VERSION ""

NS_ :

BS_:

BU_: LMFS RMFS TPMS TCU_ERAGLONASS E_APU PCCM NOX_2 NOX_1 ENGINE_CONTROL_MODULE TRANSMISSION INTARDER EBS TACHOGRAPH INSTRUMENT_CLUSTER CAMERA RADAR BCM

BO_ 2566841377 SHUTDN_BCM: 8 BCM
 SG_ ConcretePumpStartRequest : 62|2@1+ (1,0) [0|3] ""  PCCM,ENGINE_CONTROL_MODULE
 SG_ APUPressureSwitchStatus : 26|2@1+ (1,0) [0|3] ""  PCCM,ENGINE_CONTROL_MODULE
 SG_ AC_clutch_status : 22|2@1+ (1,0) [0|3] ""  PCCM,ENGINE_CONTROL_MODULE
 SG_ EngOverspeedTest : 54|2@1+ (1,0) [0|3] ""  PCCM,ENGINE_CONTROL_MODULE
 SG_ EngAirShutoffCmdStatus : 52|2@1+ (1,0) [0|3] ""  PCCM,ENGINE_CONTROL_MODULE
 SG_ EngAlarmOutputCmdStatus : 50|2@1+ (1,0) [0|3] ""  PCCM,ENGINE_CONTROL_MODULE
 SG_ EngAlarmAcknowledge : 48|2@1+ (1,0) [0|3] ""  PCCM,ENGINE_CONTROL_MODULE
 SG_ EngProtectionSystemConfig : 46|2@1+ (1,0) [0|3] ""  PCCM,ENGINE_CONTROL_MODULE
 SG_ EngProtectionSystemTimerState : 38|2@1+ (1,0) [0|3] ""  PCCM,ENGINE_CONTROL_MODULE
 SG_ EngPrtectionSystemTimerOverride : 36|2@1+ (1,0) [0|3] ""  PCCM,ENGINE_CONTROL_MODULE
 SG_ EngPrtctnSystmApprchingShutdown : 34|2@1+ (1,0) [0|3] ""  PCCM,ENGINE_CONTROL_MODULE
 SG_ EngWaitToStartLamp : 24|2@1+ (1,0) [0|3] ""  PCCM,ENGINE_CONTROL_MODULE
 SG_ RefrigerantHighPressSwitch : 20|2@1+ (1,0) [0|3] ""  PCCM,ENGINE_CONTROL_MODULE
 SG_ RefrigerantLowPressSwitch : 18|2@1+ (1,0) [0|3] ""  PCCM,ENGINE_CONTROL_MODULE
 SG_ A_CHighPressFanSwitch : 16|2@1+ (1,0) [0|3] ""  PCCM,ENGINE_CONTROL_MODULE
 SG_ EngIdleShutdownTimerFunction : 14|2@1+ (1,0) [0|3] ""  PCCM,ENGINE_CONTROL_MODULE
 SG_ EngIdleShutdownTimerState : 6|2@1+ (1,0) [0|3] ""  PCCM,ENGINE_CONTROL_MODULE
 SG_ EngIdleShutdownTimerOverride : 4|2@1+ (1,0) [0|3] ""  PCCM,ENGINE_CONTROL_MODULE
 SG_ EngIdleShutdownDriverAlertMode : 2|2@1+ (1,0) [0|3] ""  PCCM,ENGINE_CONTROL_MODULE
 SG_ PTOShutdownHasShutdownEng : 58|2@1+ (1,0) [0|3] ""  PCCM,ENGINE_CONTROL_MODULE
 SG_ EngPrtctnSystmHasShutdownEngine : 32|2@1+ (1,0) [0|3] ""  PCCM,ENGINE_CONTROL_MODULE
 SG_ EngIdlShutdownHasShutdownEngine : 0|2@1+ (1,0) [0|3] ""  PCCM,ENGINE_CONTROL_MODULE
 SG_ EngAirShutoffStatus : 56|2@1+ (1,0) [0|3] ""  PCCM,ENGINE_CONTROL_MODULE

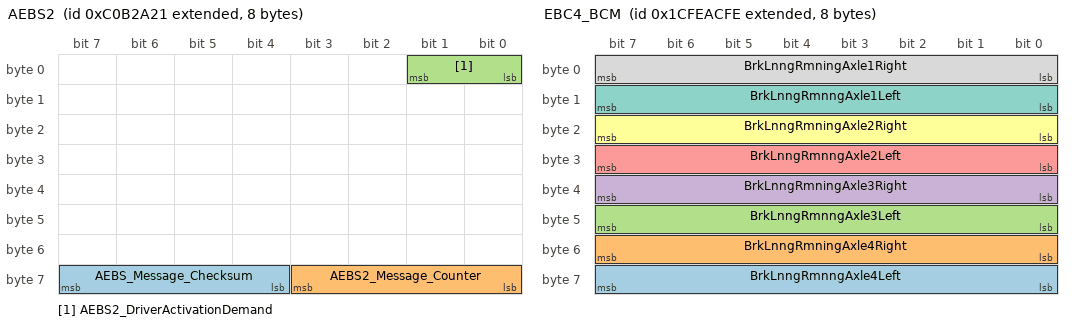
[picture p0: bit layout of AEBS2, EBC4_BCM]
BO_ 2349541921 AEBS2: 8 BCM
 SG_ AEBS_Message_Checksum : 60|4@1+ (1,0) [0|15] ""  PCCM,RADAR
 SG_ AEBS2_Message_Counter : 56|4@1+ (1,0) [0|15] ""  PCCM,RADAR
 SG_ AEBS2_DriverActivationDemand : 0|2@1+ (1,0) [0|3] ""  PCCM,RADAR

BO_ 2633936126 EBC4_BCM: 8 Vector__XXX
 SG_ BrkLnngRmnngAxle4Left : 56|8@1+ (1,0) [0|255] "" Vector__XXX
 SG_ BrkLnngRmningAxle4Right : 48|8@1+ (1,0) [0|255] "" Vector__XXX
 SG_ BrkLnngRmnngAxle3Left : 40|8@1+ (1,0) [0|255] "" Vector__XXX
 SG_ BrkLnngRmningAxle3Right : 32|8@1+ (1,0) [0|255] "" Vector__XXX
 SG_ BrkLnngRmnngAxle2Left : 24|8@1+ (1,0) [0|255] "" Vector__XXX
 SG_ BrkLnngRmningAxle2Right : 16|8@1+ (1,0) [0|255] "" Vector__XXX
 SG_ BrkLnngRmnngAxle1Left : 8|8@1+ (1,0) [0|255] "" Vector__XXX
 SG_ BrkLnngRmningAxle1Right : 0|8@1+ (1,0) [0|255] "" Vector__XXX

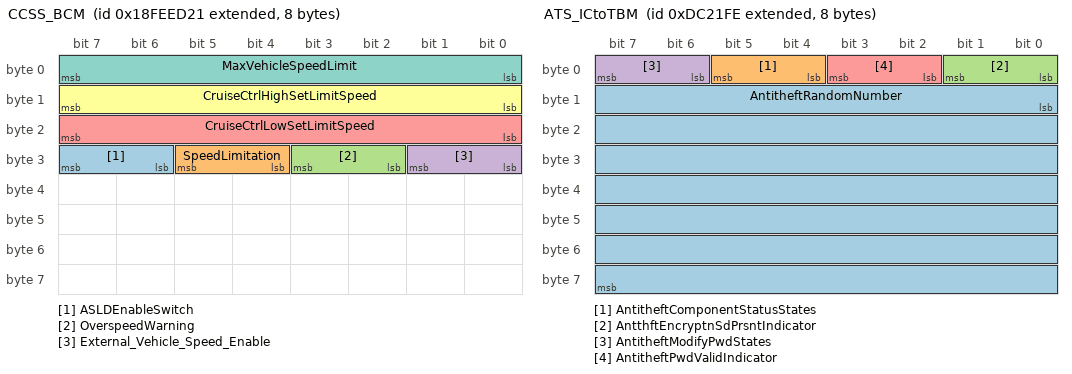
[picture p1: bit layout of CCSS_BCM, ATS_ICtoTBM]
BO_ 2566843681 CCSS_BCM: 8 BCM
 SG_ ASLDEnableSwitch : 30|2@1+ (1,0) [0|3] "SED"  PCCM,ENGINE_CONTROL_MODULE,INSTRUMENT_CLUSTER
 SG_ SpeedLimitation : 28|2@1+ (1,0) [0|3] ""  PCCM,ENGINE_CONTROL_MODULE,INSTRUMENT_CLUSTER
 SG_ OverspeedWarning : 26|2@1+ (1,0) [0|3] ""  PCCM,ENGINE_CONTROL_MODULE,INSTRUMENT_CLUSTER
 SG_ External_Vehicle_Speed_Enable : 24|2@1+ (1,0) [0|3] ""  PCCM,ENGINE_CONTROL_MODULE,INSTRUMENT_CLUSTER
 SG_ CruiseCtrlLowSetLimitSpeed : 16|8@1+ (1,0) [0|250] "km/h"  PCCM,ENGINE_CONTROL_MODULE,INSTRUMENT_CLUSTER
 SG_ CruiseCtrlHighSetLimitSpeed : 8|8@1+ (1,0) [0|250] "km/h"  PCCM,ENGINE_CONTROL_MODULE,INSTRUMENT_CLUSTER
 SG_ MaxVehicleSpeedLimit : 0|8@1+ (1,0) [0|250] "km/h"  PCCM,ENGINE_CONTROL_MODULE,INSTRUMENT_CLUSTER

BO_ 2566844705 CCVS_BCM: 8 BCM
 SG_ AutoECall_Inhibit : 40|2@1+ (1,0) [0|3] ""  PCCM
 SG_ PCCScreenSelection : 61|2@1+ (1,0) [0|3] ""  PCCM,INSTRUMENT_CLUSTER
 SG_ CruiseCtrlEnableSwitch_BCM : 26|2@1+ (1,0) [0|3] ""  PCCM
 SG_ CruiseControlDisableCommand_BCM : 0|2@1+ (1,0) [0|3] ""  PCCM,ENGINE_CONTROL_MODULE,INSTRUMENT_CLUSTER
 SG_ ConcretePumpTransferCaseACK : 56|2@1+ (1,0) [0|3] ""  PCCM,ENGINE_CONTROL_MODULE,INSTRUMENT_CLUSTER
 SG_ PTO_Application_Mode : 58|3@1+ (1,0) [0|7] ""  PCCM,ENGINE_CONTROL_MODULE,INSTRUMENT_CLUSTER
 SG_ ParkBrakeReleaseInhibitRq_CCVSB : 6|2@1+ (1,0) [0|3] ""  PCCM,ENGINE_CONTROL_MODULE,INSTRUMENT_CLUSTER
 SG_ PTOGovernorState_CCVS_BCM : 48|5@1+ (1,0) [0|31] ""  PCCM,ENGINE_CONTROL_MODULE,INSTRUMENT_CLUSTER
 SG_ CruiseCtrlAccelerateSwitch_CCVSB : 38|2@1+ (1,0) [0|3] ""  PCCM,ENGINE_CONTROL_MODULE,INSTRUMENT_CLUSTER
 SG_ CruiseCtrlResumeSwitch_CCVS_BCM : 36|2@1+ (1,0) [0|3] ""  PCCM,ENGINE_CONTROL_MODULE,INSTRUMENT_CLUSTER
 SG_ CruiseCtrlCoastSwitch_CCVS_BCM : 34|2@1+ (1,0) [0|3] ""  PCCM,ENGINE_CONTROL_MODULE,INSTRUMENT_CLUSTER
 SG_ CruiseCtrlOffSwitch : 32|2@1+ (1,0) [0|3] ""  PCCM,ENGINE_CONTROL_MODULE,INSTRUMENT_CLUSTER
 SG_ ClutchSwitch_CCVS_BCM : 30|2@1+ (1,0) [0|3] ""  PCCM,ENGINE_CONTROL_MODULE,INSTRUMENT_CLUSTER
 SG_ BrakeSwitch_CCVS_BCM : 28|2@1+ (1,0) [0|3] ""  PCCM,ENGINE_CONTROL_MODULE,INSTRUMENT_CLUSTER
 SG_ DamperActivation : 24|2@1+ (1,0) [0|3] ""  PCCM,ENGINE_CONTROL_MODULE,INSTRUMENT_CLUSTER
 SG_ WheelBasedVehicleSpeed_CCVS_BCM : 8|16@1+ (0.00390625,0) [0|251] "km/h"  PCCM,ENGINE_CONTROL_MODULE,INSTRUMENT_CLUSTER
 SG_ CruiseCtrlPauseSwitch_CCVS_BCM : 4|2@1+ (1,0) [0|3] ""  PCCM,ENGINE_CONTROL_MODULE,INSTRUMENT_CLUSTER
 SG_ ParkingBrakeSwitch_CCVS_BCM : 2|2@1+ (1,0) [0|3] ""  PCCM,ENGINE_CONTROL_MODULE,INSTRUMENT_CLUSTER

BO_ 2566834967 DM2_IC: 22 Vector__XXX
 SG_ MalfunctionIndicatorLampStatus : 6|2@1+ (1,0) [0|3] "" Vector__XXX
 SG_ RedStopLampState : 4|2@1+ (1,0) [0|3] "" Vector__XXX
 SG_ AmberWarningLampStatus : 2|2@1+ (1,0) [0|3] "" Vector__XXX
 SG_ ProtectLampStatus : 0|2@1+ (1,0) [0|3] "" Vector__XXX
 SG_ FlashRedStopLamp : 12|2@1+ (1,0) [0|3] "" Vector__XXX
 SG_ FlashProtectLamp : 8|2@1+ (1,0) [0|3] "" Vector__XXX
 SG_ FlashMalfuncIndicatorLamp : 14|2@1+ (1,0) [0|3] "" Vector__XXX
 SG_ FlashAmberWarningLamp : 10|2@1+ (1,0) [0|3] "" Vector__XXX
 SG_ DTC5 : 144|32@1+ (1,0) [0|4294967295] "" Vector__XXX
 SG_ DTC4 : 112|32@1+ (1,0) [0|4294967295] "" Vector__XXX
 SG_ DTC3 : 80|32@1+ (1,0) [0|4294967295] "" Vector__XXX
 SG_ DTC2 : 48|32@1+ (1,0) [0|4294967295] "" Vector__XXX
 SG_ DTC1 : 16|32@1+ (1,0) [0|4294967295] "" Vector__XXX

BO_ 2566834711 DM1_IC: 64 INSTRUMENT_CLUSTER
 SG_ FlashRedStopLamp : 12|2@1+ (1,0) [0|3] ""  PCCM
 SG_ FlashProtectLamp : 8|2@1+ (1,0) [0|3] ""  PCCM
 SG_ FlashMalfuncIndicatorLamp : 14|2@1+ (1,0) [0|3] ""  PCCM
 SG_ FlashAmberWarningLamp : 10|2@1+ (1,0) [0|3] ""  PCCM
 SG_ MalfunctionIndicatorLampStatus : 6|2@1+ (1,0) [0|3] ""  PCCM
 SG_ AmberWarningLampStatus : 2|2@1+ (1,0) [0|3] ""  PCCM
 SG_ RedStopLampState : 4|2@1+ (1,0) [0|3] ""  PCCM
 SG_ ProtectLampStatus : 0|2@1+ (1,0) [0|3] ""  PCCM
 SG_ DTC5 : 144|32@1+ (1,0) [0|4294967295] ""  PCCM
 SG_ DTC4 : 112|32@1+ (1,0) [0|4294967295] ""  PCCM
 SG_ DTC3 : 80|32@1+ (1,0) [0|4294967295] ""  PCCM
 SG_ DTC2 : 48|32@1+ (1,0) [0|4294967295] ""  PCCM
 SG_ DTC1 : 16|32@1+ (1,0) [0|4294967295] ""  PCCM

BO_ 2161910270 ATS_ICtoTBM: 8 Vector__XXX
 SG_ AntitheftRandomNumber : 8|56@1+ (1,0) [0|255] "" Vector__XXX
 SG_ AntitheftComponentStatusStates : 4|2@1+ (1,0) [0|3] "" Vector__XXX
 SG_ AntthftEncryptnSdPrsntIndicator : 0|2@1+ (1,0) [0|3] "" Vector__XXX
 SG_ AntitheftModifyPwdStates : 6|2@1+ (1,0) [0|3] "" Vector__XXX
 SG_ AntitheftPwdValidIndicator : 2|2@1+ (1,0) [0|3] "" Vector__XXX

BO_ 2566835198 DM2_ABS_ABSwESP: 22 Vector__XXX
 SG_ MalfunctionIndicatorLampStatus : 6|2@1+ (1,0) [0|3] "" Vector__XXX
 SG_ RedStopLampState : 4|2@1+ (1,0) [0|3] "" Vector__XXX
 SG_ AmberWarningLampStatus : 2|2@1+ (1,0) [0|3] "" Vector__XXX
 SG_ ProtectLampStatus : 0|2@1+ (1,0) [0|3] "" Vector__XXX
 SG_ FlashRedStopLamp : 12|2@1+ (1,0) [0|3] "" Vector__XXX
 SG_ FlashProtectLamp : 8|2@1+ (1,0) [0|3] "" Vector__XXX
 SG_ FlashMalfuncIndicatorLamp : 14|2@1+ (1,0) [0|3] "" Vector__XXX
 SG_ FlashAmberWarningLamp : 10|2@1+ (1,0) [0|3] "" Vector__XXX
 SG_ DTC5 : 144|32@1+ (1,0) [0|4294967295] "" Vector__XXX
 SG_ DTC4 : 112|32@1+ (1,0) [0|4294967295] "" Vector__XXX
 SG_ DTC3 : 80|32@1+ (1,0) [0|4294967295] "" Vector__XXX
 SG_ DTC2 : 48|32@1+ (1,0) [0|4294967295] "" Vector__XXX
 SG_ DTC1 : 16|32@1+ (1,0) [0|4294967295] "" Vector__XXX

BO_ 2550596608 EDC2NOx: 8 Vector__XXX

BO_ 2349334270 NOxSensorMessage: 8 Vector__XXX

BO_ 2566881534 FWLI: 8 Vector__XXX
 SG_ TBMTelltale : 0|2@1+ (1,0) [0|3] "" Vector__XXX
 SG_ ErrorIndication : 2|6@1+ (1,0) [0|63] "" Vector__XXX

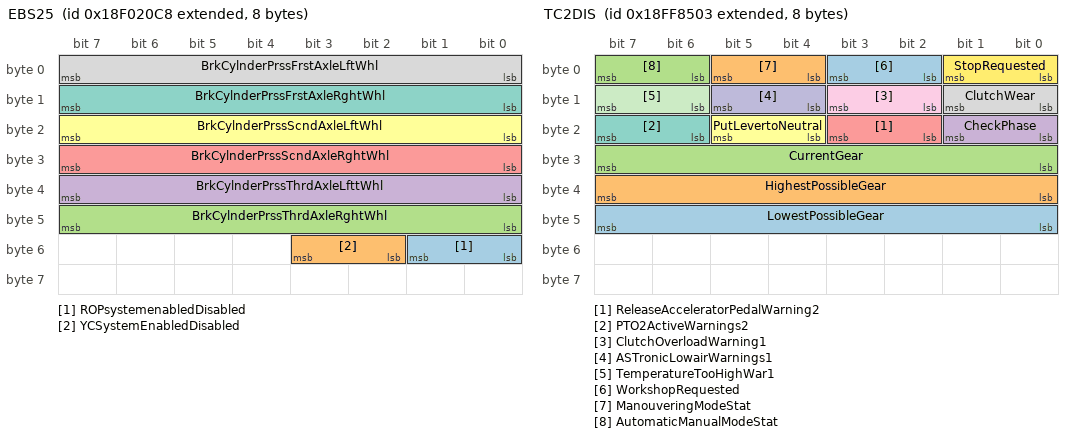
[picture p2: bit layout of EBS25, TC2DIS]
BO_ 2565873864 EBS25: 8 Vector__XXX
 SG_ ROPsystemenabledDisabled : 48|2@1+ (1,0) [0|3] "" Vector__XXX
 SG_ YCSystemEnabledDisabled : 50|2@1+ (1,0) [0|3] "" Vector__XXX
 SG_ BrkCylnderPrssThrdAxleRghtWhl : 40|8@1+ (5,0) [0|1250] "kPa" Vector__XXX
 SG_ BrkCylnderPrssThrdAxleLfttWhl : 32|8@1+ (5,0) [0|1250] "kPa" Vector__XXX
 SG_ BrkCylnderPrssScndAxleRghtWhl : 24|8@1+ (5,0) [0|1250] "kPa" Vector__XXX
 SG_ BrkCylnderPrssScndAxleLftWhl : 16|8@1+ (5,0) [0|1250] "kPa" Vector__XXX
 SG_ BrkCylnderPrssFrstAxleRghtWhl : 8|8@1+ (5,0) [0|1250] "kPa" Vector__XXX
 SG_ BrkCylnderPrssFrstAxleLftWhl : 0|8@1+ (5,0) [0|1250] "kPa" Vector__XXX

BO_ 2566882563 TC2DIS: 8 TRANSMISSION
 SG_ LowestPossibleGear : 40|8@1+ (1,-125) [-125|125] "gearvalue"  PCCM,INSTRUMENT_CLUSTER,BCM
 SG_ HighestPossibleGear : 32|8@1+ (1,-125) [-125|125] "gearvalue"  PCCM,INSTRUMENT_CLUSTER,BCM
 SG_ CurrentGear : 24|8@1+ (1,-125) [-125|125] "gearvalue"  PCCM,INSTRUMENT_CLUSTER,BCM
 SG_ CheckPhase : 16|2@1+ (1,0) [0|3] ""  PCCM,INSTRUMENT_CLUSTER,BCM
 SG_ ReleaseAcceleratorPedalWarning2 : 18|2@1+ (1,0) [0|3] ""  PCCM,INSTRUMENT_CLUSTER,BCM
 SG_ PutLevertoNeutral : 20|2@1+ (1,0) [0|3] ""  PCCM,INSTRUMENT_CLUSTER,BCM
 SG_ PTO2ActiveWarnings2 : 22|2@1+ (1,0) [0|3] ""  PCCM,INSTRUMENT_CLUSTER,BCM
 SG_ ClutchWear : 8|2@1+ (1,0) [0|3] ""  PCCM,INSTRUMENT_CLUSTER,BCM
 SG_ ClutchOverloadWarning1 : 10|2@1+ (1,0) [0|3] ""  PCCM,INSTRUMENT_CLUSTER,BCM
 SG_ ASTronicLowairWarnings1 : 12|2@1+ (1,0) [0|3] ""  PCCM,INSTRUMENT_CLUSTER,BCM
 SG_ TemperatureTooHighWar1 : 14|2@1+ (1,0) [0|3] ""  PCCM,INSTRUMENT_CLUSTER,BCM
 SG_ StopRequested : 0|2@1+ (1,0) [0|3] ""  PCCM,INSTRUMENT_CLUSTER,BCM
 SG_ WorkshopRequested : 2|2@1+ (1,0) [0|3] ""  PCCM,INSTRUMENT_CLUSTER,BCM
 SG_ ManouveringModeStat : 4|2@1+ (1,0) [0|3] ""  PCCM,BCM,INSTRUMENT_CLUSTER
 SG_ AutomaticManualModeStat : 6|2@1+ (1,0) [0|3] ""  PCCM,INSTRUMENT_CLUSTER,BCM

BO_ 2550596157 SCR2: 8 Vector__XXX
 SG_ UreaTankLevel : 0|8@1- (0.4,0) [0|100] "%" Vector__XXX
 SG_ SCR2 : 8|56@1+ (1,0) [0|7.2057594038E+016] "" Vector__XXX

BO_ 2550726398 SCR1_DCU: 8 Vector__XXX
 SG_ SCR1 : 0|64@1+ (1,0) [0|1.8446744074E+019] "" Vector__XXX

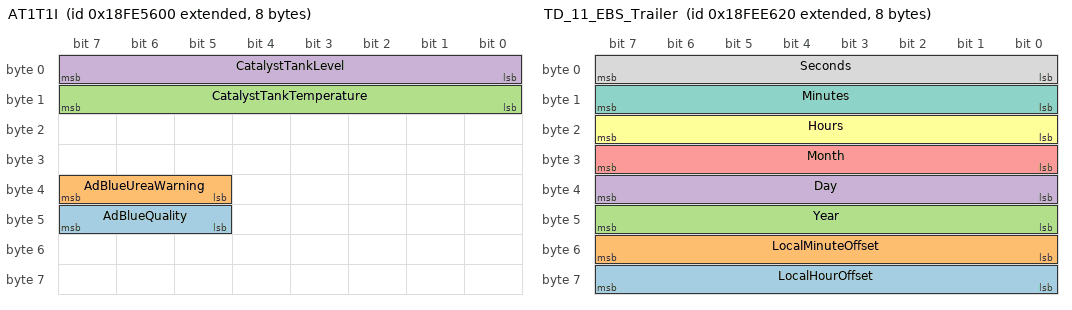
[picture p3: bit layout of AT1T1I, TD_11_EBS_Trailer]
BO_ 2566804992 AT1T1I: 8 ENGINE_CONTROL_MODULE
 SG_ AdBlueQuality : 45|3@1+ (1,0) [0|7] "SED"  PCCM,BCM,INSTRUMENT_CLUSTER
 SG_ AdBlueUreaWarning : 37|3@1+ (1,0) [0|7] "SED"  PCCM,BCM,INSTRUMENT_CLUSTER
 SG_ CatalystTankTemperature : 8|8@1+ (1,-40) [-40|210] "degree"  PCCM,BCM,INSTRUMENT_CLUSTER
 SG_ CatalystTankLevel : 0|8@1+ (0.4,0) [0|100] "%"  PCCM,BCM,INSTRUMENT_CLUSTER

BO_ 2566857214 EDC2BC: 8 Vector__XXX
 SG_ Humudity : 56|8@1+ (0.4,0) [0|102] "%" Vector__XXX
 SG_ EngineDegradationLevel : 48|4@1+ (1,0) [0|15] "" Vector__XXX
 SG_ EDCOperationalStat : 52|4@1+ (1,0) [0|15] "" Vector__XXX
 SG_ EngineOilPressureLow : 40|2@1+ (1,0) [0|3] "" Vector__XXX
 SG_ WaterinFeulDetection : 42|2@1+ (1,0) [0|3] "" Vector__XXX
 SG_ FuelFilterStatus : 44|2@1+ (1,0) [0|3] "" Vector__XXX
 SG_ EngineOilTemperatureHigh : 46|2@1+ (1,0) [0|3] "" Vector__XXX
 SG_ StatofEngComprtmntStopButton : 36|2@1+ (1,0) [0|3] "" Vector__XXX
 SG_ StatofEngCompartmentStartButton : 38|2@1+ (1,0) [0|3] "" Vector__XXX
 SG_ MILStatus : 24|2@1+ (1,0) [0|3] "" Vector__XXX
 SG_ AdjustabelSpeedLimiterStatus : 28|2@1+ (1,0) [0|3] "" Vector__XXX
 SG_ ECMFuellingState : 30|2@1+ (1,0) [0|3] "" Vector__XXX
 SG_ MaximumVehicleSpeedLimitSetPoint : 16|8@1+ (1,0) [0|255] "km/h" Vector__XXX
 SG_ SpeedLimiterStatus : 8|2@1+ (1,0) [0|3] "" Vector__XXX
 SG_ EngineOverSpeed : 10|2@1+ (1,0) [0|3] "" Vector__XXX
 SG_ EngineOverTemperature : 13|3@1+ (1,0) [0|7] "" Vector__XXX
 SG_ ColdStartHeaterStat : 0|4@1+ (1,0) [0|15] "" Vector__XXX
 SG_ FuelBlockStatByImmobilizer : 4|2@1+ (1,0) [0|3] "" Vector__XXX
 SG_ DiagnosticLampStat : 6|2@1+ (1,0) [0|3] "" Vector__XXX

BO_ 2365537790 ECM2SCR: 8 Vector__XXX
 SG_ ECM2SCR : 0|64@1+ (1,0) [0|999999] "" Vector__XXX

BO_ 2566841888 TD_11_EBS_Trailer: 8 Vector__XXX
 SG_ LocalHourOffset : 56|8@1+ (1,-125) [-125|125] "hr" Vector__XXX
 SG_ LocalMinuteOffset : 48|8@1+ (1,-125) [-125|125] "mins" Vector__XXX
 SG_ Year : 40|8@1+ (1,1985) [1985|2235] "years" Vector__XXX
 SG_ Day : 32|8@1+ (0.25,0) [0|62.5] "days" Vector__XXX
 SG_ Month : 24|8@1+ (1,0) [0|250] "months" Vector__XXX
 SG_ Hours : 16|8@1+ (1,0) [0|250] "hr" Vector__XXX
 SG_ Minutes : 8|8@1+ (1,0) [0|250] "mins" Vector__XXX
 SG_ Seconds : 0|8@1+ (0.25,0) [0|62.5] "s" Vector__XXX

BO_ 2566835710 DM4_AST: 13 Vector__XXX
 SG_ EngIntakeManifold1Press : 48|8@1+ (2,0) [0|500] "kPa" Vector__XXX
 SG_ FreezeFrameLength : 0|8@1+ (1,0) [0|255] "Byte" Vector__XXX
 SG_ EngSpeed : 56|16@1+ (0.125,0) [0|8031.875] "rpm" Vector__XXX
 SG_ EngTorqueMode : 40|4@1+ (1,0) [0|15] "" Vector__XXX
 SG_ WheelBasedVehicleSpeed : 88|16@1+ (0.00390625,0) [0|250.996] "km/h" Vector__XXX
 SG_ EngPercentLoadAtCurrentSpeed : 72|8@1+ (1,0) [0|250] "%" Vector__XXX
 SG_ EngineCoolantTemperature : 80|8@1+ (1,-40) [-40|210] "°C" Vector__XXX
 SG_ DTC1 : 8|32@1+ (1,0) [0|4294967295] "" Vector__XXX

BO_ 2566840592 RC_Intarder: 19 INTARDER
 SG_ PercentTorqueAtPeakTorquePoint5 : 144|8@1+ (1,-125) [-125|125] "%"  PCCM,TRANSMISSION,EBS
 SG_ ReferenceRetarderTorque : 128|16@1+ (1,0) [0|64255] "Nm"  PCCM,TRANSMISSION,EBS
 SG_ RetarderSpeedAtPeakTorquePoint5 : 112|16@1+ (0.125,0) [0|8031.875] "rpm"  PCCM,TRANSMISSION,EBS
 SG_ PercentTorqueAtPoint4 : 104|8@1+ (1,-125) [-125|125] "%"  PCCM,TRANSMISSION,EBS
 SG_ RetarderSpeedAtPoint4 : 88|16@1+ (0.125,0) [0|8031.875] "rpm"  PCCM,TRANSMISSION,EBS
 SG_ PercentTorqueAtPoint3 : 80|8@1+ (1,-125) [-125|125] "%"  PCCM,TRANSMISSION,EBS
 SG_ RetarderSpeedAtPoint3 : 64|16@1+ (0.125,0) [0|8031.875] "rpm"  PCCM,TRANSMISSION,EBS
 SG_ PercentTorqueAtMaxSpeedPoint2 : 56|8@1+ (1,-125) [-125|125] "%"  PCCM,TRANSMISSION,EBS
 SG_ MaxRetarderSpeedPoint2 : 40|16@1+ (0.125,0) [0|8031.875] "rpm"  PCCM,TRANSMISSION,EBS
 SG_ PercentTorqueAtIdlePoint1 : 32|8@1+ (1,-125) [-125|125] "%"  PCCM,TRANSMISSION,EBS
 SG_ RetarderSpeedAtIdlePoint1 : 16|16@1+ (0.125,0) [0|8031.875] "rpm"  PCCM,TRANSMISSION,EBS
 SG_ RetarderCtrlMethod : 8|8@1+ (1,0) [0|250] "steps"  PCCM,TRANSMISSION,EBS
 SG_ RetarderLocation : 4|4@1+ (1,0) [0|15] ""  PCCM,TRANSMISSION,EBS
 SG_ RetarderType : 0|4@1+ (1,0) [0|15] ""  PCCM,TRANSMISSION,EBS

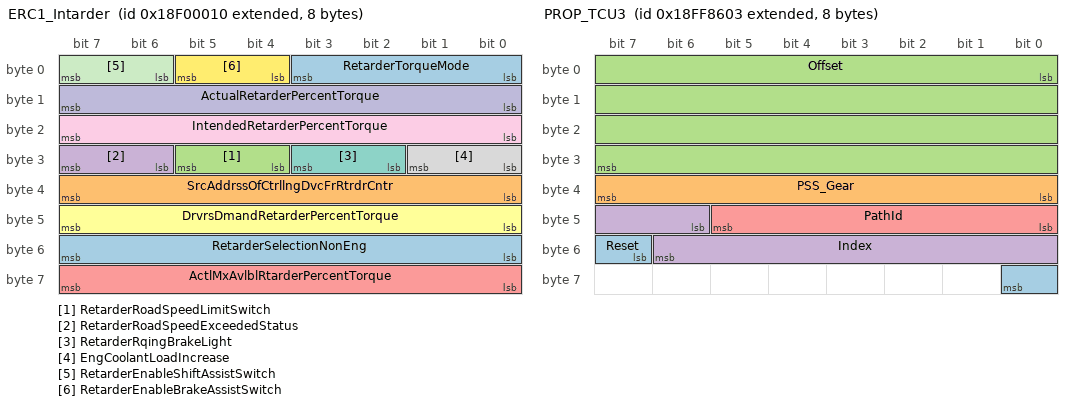
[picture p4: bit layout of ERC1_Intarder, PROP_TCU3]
BO_ 2565865488 ERC1_Intarder: 8 INTARDER
 SG_ RetarderSelectionNonEng : 48|8@1+ (0.4,0) [0|100] "%"  PCCM,TRANSMISSION,EBS,INSTRUMENT_CLUSTER,BCM
 SG_ SrcAddrssOfCtrllngDvcFrRtrdrCntr : 32|8@1+ (1,0) [0|255] ""  PCCM,TRANSMISSION,EBS,INSTRUMENT_CLUSTER,BCM
 SG_ RetarderRoadSpeedLimitSwitch : 28|2@1+ (1,0) [0|3] ""  PCCM,TRANSMISSION,EBS,INSTRUMENT_CLUSTER,BCM
 SG_ RetarderRoadSpeedExceededStatus : 30|2@1+ (1,0) [0|3] ""  PCCM,TRANSMISSION,EBS,INSTRUMENT_CLUSTER,BCM
 SG_ ActlMxAvlblRtarderPercentTorque : 56|8@1+ (1,-125) [-125|0] "%"  PCCM,TRANSMISSION,EBS,INSTRUMENT_CLUSTER,BCM
 SG_ DrvrsDmandRetarderPercentTorque : 40|8@1+ (1,-125) [-125|0] "%"  PCCM,TRANSMISSION,EBS,INSTRUMENT_CLUSTER,BCM
 SG_ RetarderRqingBrakeLight : 26|2@1+ (1,0) [0|3] ""  PCCM,TRANSMISSION,EBS,INSTRUMENT_CLUSTER,BCM
 SG_ EngCoolantLoadIncrease : 24|2@1+ (1,0) [0|3] ""  PCCM,TRANSMISSION,EBS,INSTRUMENT_CLUSTER,BCM
 SG_ IntendedRetarderPercentTorque : 16|8@1+ (1,-125) [-125|0] "%"  PCCM,TRANSMISSION,EBS,INSTRUMENT_CLUSTER,BCM
 SG_ ActualRetarderPercentTorque : 8|8@1+ (1,-125) [-125|0] "%"  PCCM,TRANSMISSION,EBS,INSTRUMENT_CLUSTER,BCM
 SG_ RetarderEnableShiftAssistSwitch : 6|2@1+ (1,0) [0|3] ""  PCCM,TRANSMISSION,EBS,INSTRUMENT_CLUSTER,BCM
 SG_ RetarderEnableBrakeAssistSwitch : 4|2@1+ (1,0) [0|3] ""  PCCM,TRANSMISSION,EBS,INSTRUMENT_CLUSTER,BCM
 SG_ RetarderTorqueMode : 0|4@1+ (1,0) [0|15] ""  PCCM,TRANSMISSION,EBS,INSTRUMENT_CLUSTER,BCM

BO_ 2566834960 DM2_Int: 64 INTARDER
 SG_ MalfunctionIndicatorLampStatus : 6|2@1+ (1,0) [0|3] ""  PCCM
 SG_ RedStopLampState : 4|2@1+ (1,0) [0|3] ""  PCCM
 SG_ AmberWarningLampStatus : 2|2@1+ (1,0) [0|3] ""  PCCM
 SG_ ProtectLampStatus : 0|2@1+ (1,0) [0|3] ""  PCCM
 SG_ FlashRedStopLamp : 12|2@1+ (1,0) [0|3] ""  PCCM
 SG_ FlashProtectLamp : 8|2@1+ (1,0) [0|3] ""  PCCM
 SG_ FlashMalfuncIndicatorLamp : 14|2@1+ (1,0) [0|3] ""  PCCM
 SG_ FlashAmberWarningLamp : 10|2@1+ (1,0) [0|3] ""  PCCM
 SG_ DTC5 : 144|32@1+ (1,0) [0|4294967295] ""  PCCM
 SG_ DTC4 : 112|32@1+ (1,0) [0|4294967295] ""  PCCM
 SG_ DTC3 : 80|32@1+ (1,0) [0|4294967295] ""  PCCM
 SG_ DTC2 : 48|32@1+ (1,0) [0|4294967295] ""  PCCM
 SG_ DTC1 : 16|32@1+ (1,0) [0|4294967295] ""  PCCM

BO_ 2566882819 PROP_TCU3: 8 TRANSMISSION
 SG_ Reset : 55|2@1+ (1,0) [0|3] ""  PCCM
 SG_ PSS_Gear : 32|8@1+ (1,-125) [-125|125] ""  PCCM
 SG_ Offset : 0|32@1+ (1,0) [0|4294967295] "m"  PCCM
 SG_ Index : 46|9@1+ (1,0) [0|511] ""  PCCM
 SG_ PathId : 40|6@1+ (1,0) [0|63] ""  PCCM

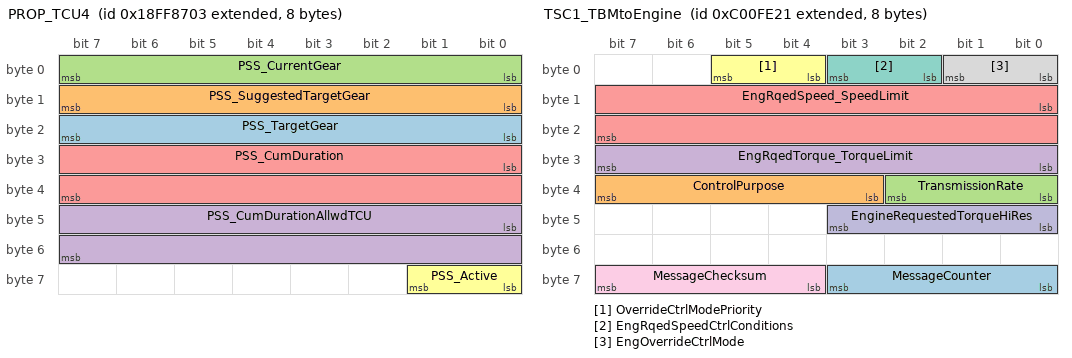
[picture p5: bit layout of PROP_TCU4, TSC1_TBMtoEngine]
BO_ 2566883075 PROP_TCU4: 8 TRANSMISSION
 SG_ PSS_TargetGear : 16|8@1+ (1,-125) [-125|125] ""  PCCM
 SG_ PSS_SuggestedTargetGear : 8|8@1+ (1,-125) [-125|125] ""  PCCM
 SG_ PSS_CurrentGear : 0|8@1+ (1,-125) [-125|125] ""  PCCM
 SG_ PSS_CumDurationAllwdTCU : 40|16@1+ (1,0) [0|65535] "min"  PCCM
 SG_ PSS_CumDuration : 24|16@1+ (1,0) [0|65535] "min"  PCCM
 SG_ PSS_Active : 56|2@1+ (1,0) [0|3] ""  PCCM

BO_ 2566834749 DM1_DCU: 22 Vector__XXX
 SG_ FlashRedStopLamp : 12|2@1+ (1,0) [0|3] "" Vector__XXX
 SG_ FlashProtectLamp : 8|2@1+ (1,0) [0|3] "" Vector__XXX
 SG_ FlashMalfuncIndicatorLamp : 14|2@1+ (1,0) [0|3] "" Vector__XXX
 SG_ FlashAmberWarningLamp : 10|2@1+ (1,0) [0|3] "" Vector__XXX
 SG_ MalfunctionIndicatorLampStatus : 6|2@1+ (1,0) [0|3] "" Vector__XXX
 SG_ AmberWarningLampStatus : 2|2@1+ (1,0) [0|3] "" Vector__XXX
 SG_ RedStopLampState : 4|2@1+ (1,0) [0|3] "" Vector__XXX
 SG_ ProtectLampStatus : 0|2@1+ (1,0) [0|3] "" Vector__XXX
 SG_ DTC5 : 144|32@1+ (1,0) [0|4294967295] "" Vector__XXX
 SG_ DTC4 : 112|32@1+ (1,0) [0|4294967295] "" Vector__XXX
 SG_ DTC3 : 80|32@1+ (1,0) [0|4294967295] "" Vector__XXX
 SG_ DTC2 : 48|32@1+ (1,0) [0|4294967295] "" Vector__XXX
 SG_ DTC1 : 16|32@1+ (1,0) [0|4294967295] "" Vector__XXX

BO_ 2348875297 TSC1_TBMtoEngine: 8 Vector__XXX
 SG_ MessageCounter : 56|4@1+ (1,0) [0|15] "" Vector__XXX
 SG_ ControlPurpose : 35|5@1+ (1,0) [0|31] "" Vector__XXX
 SG_ TransmissionRate : 32|3@1+ (1,0) [0|7] "" Vector__XXX
 SG_ EngRqedTorque_TorqueLimit : 24|8@1+ (1,-125) [-125|125] "%" Vector__XXX
 SG_ EngRqedSpeed_SpeedLimit : 8|16@1+ (0.125,0) [0|8031.875] "rpm" Vector__XXX
 SG_ OverrideCtrlModePriority : 4|2@1+ (1,0) [0|3] "" Vector__XXX
 SG_ EngRqedSpeedCtrlConditions : 2|2@1+ (1,0) [0|3] "" Vector__XXX
 SG_ EngOverrideCtrlMode : 0|2@1+ (1,0) [0|3] "" Vector__XXX
 SG_ MessageChecksum : 60|4@1+ (1,0) [0|15] "" Vector__XXX
 SG_ EngineRequestedTorqueHiRes : 40|4@1+ (0.125,0) [0|0.875] "%" Vector__XXX

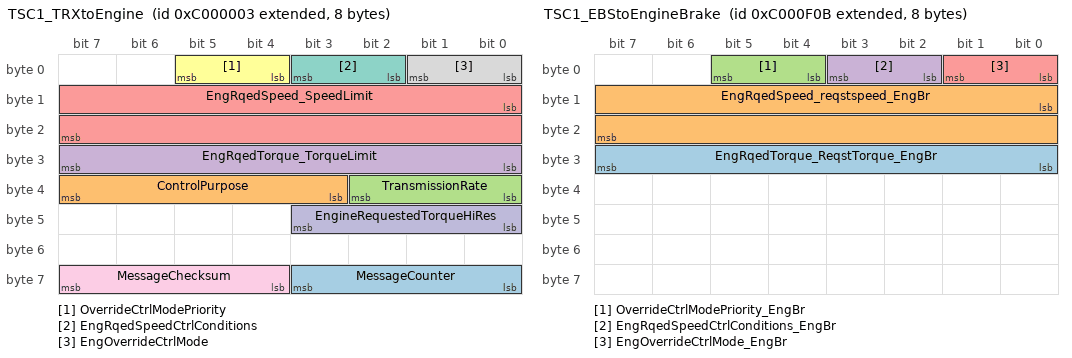
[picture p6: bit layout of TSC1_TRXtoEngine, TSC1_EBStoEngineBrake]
BO_ 2348810243 TSC1_TRXtoEngine: 8 TRANSMISSION
 SG_ MessageCounter : 56|4@1+ (1,0) [0|15] ""  PCCM,ENGINE_CONTROL_MODULE
 SG_ ControlPurpose : 35|5@1+ (1,0) [0|31] ""  PCCM,ENGINE_CONTROL_MODULE
 SG_ TransmissionRate : 32|3@1+ (1,0) [0|7] ""  PCCM,ENGINE_CONTROL_MODULE
 SG_ EngRqedTorque_TorqueLimit : 24|8@1+ (1,-125) [-125|125] "%"  PCCM,ENGINE_CONTROL_MODULE
 SG_ EngRqedSpeed_SpeedLimit : 8|16@1+ (0.125,0) [0|8031.875] "rpm"  PCCM,ENGINE_CONTROL_MODULE
 SG_ OverrideCtrlModePriority : 4|2@1+ (1,0) [0|3] ""  PCCM,ENGINE_CONTROL_MODULE
 SG_ EngRqedSpeedCtrlConditions : 2|2@1+ (1,0) [0|3] ""  PCCM,ENGINE_CONTROL_MODULE
 SG_ EngOverrideCtrlMode : 0|2@1+ (1,0) [0|3] ""  PCCM,ENGINE_CONTROL_MODULE
 SG_ MessageChecksum : 60|4@1+ (1,0) [0|15] ""  PCCM,ENGINE_CONTROL_MODULE
 SG_ EngineRequestedTorqueHiRes : 40|4@1+ (0.125,0) [0|0.875] "%"  PCCM,ENGINE_CONTROL_MODULE

BO_ 2348814091 TSC1_EBStoEngineBrake: 8 EBS
 SG_ EngRqedTorque_ReqstTorque_EngBr : 24|8@1+ (1,-125) [-125|125] "%"  ENGINE_CONTROL_MODULE,PCCM
 SG_ EngRqedSpeed_reqstspeed_EngBr : 8|16@1+ (0.125,0) [0|8031.875] "rpm"  ENGINE_CONTROL_MODULE,PCCM
 SG_ OverrideCtrlModePriority_EngBr : 4|2@1+ (1,0) [0|3] ""  ENGINE_CONTROL_MODULE,PCCM
 SG_ EngRqedSpeedCtrlConditions_EngBr : 2|2@1+ (1,0) [0|3] ""  ENGINE_CONTROL_MODULE,PCCM
 SG_ EngOverrideCtrlMode_EngBr : 0|2@1+ (1,0) [0|3] ""  ENGINE_CONTROL_MODULE,PCCM

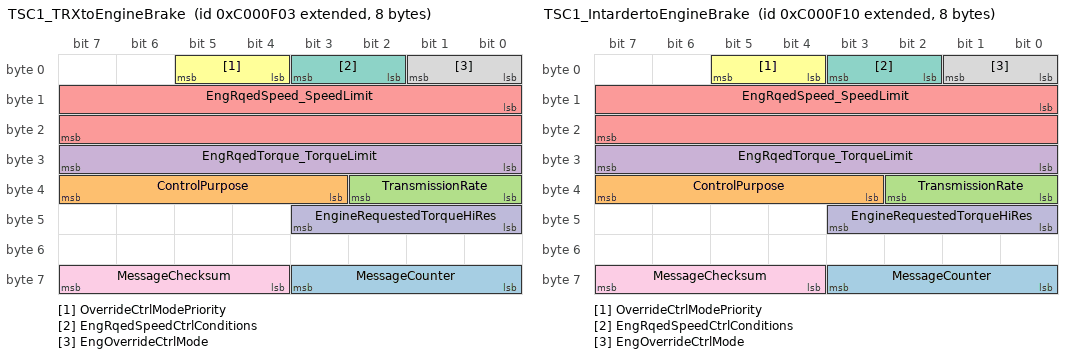
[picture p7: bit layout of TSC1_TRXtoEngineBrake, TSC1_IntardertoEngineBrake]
BO_ 2348814083 TSC1_TRXtoEngineBrake: 8 TRANSMISSION
 SG_ MessageCounter : 56|4@1+ (1,0) [0|15] ""  PCCM
 SG_ ControlPurpose : 35|5@1+ (1,0) [0|31] ""  PCCM
 SG_ TransmissionRate : 32|3@1+ (1,0) [0|7] ""  PCCM
 SG_ EngRqedTorque_TorqueLimit : 24|8@1+ (1,-125) [-125|125] "%"  PCCM
 SG_ EngRqedSpeed_SpeedLimit : 8|16@1+ (0.125,0) [0|8031.875] "rpm"  PCCM
 SG_ OverrideCtrlModePriority : 4|2@1+ (1,0) [0|3] ""  PCCM
 SG_ EngRqedSpeedCtrlConditions : 2|2@1+ (1,0) [0|3] ""  PCCM
 SG_ EngOverrideCtrlMode : 0|2@1+ (1,0) [0|3] ""  PCCM
 SG_ MessageChecksum : 60|4@1+ (1,0) [0|15] ""  PCCM
 SG_ EngineRequestedTorqueHiRes : 40|4@1+ (0.125,0) [0|0.875] "%"  PCCM

BO_ 2348814096 TSC1_IntardertoEngineBrake: 8 INTARDER
 SG_ MessageCounter : 56|4@1+ (1,0) [0|15] ""  PCCM,ENGINE_CONTROL_MODULE
 SG_ ControlPurpose : 35|5@1+ (1,0) [0|31] ""  PCCM,ENGINE_CONTROL_MODULE
 SG_ TransmissionRate : 32|3@1+ (1,0) [0|7] ""  PCCM,ENGINE_CONTROL_MODULE
 SG_ EngRqedTorque_TorqueLimit : 24|8@1+ (1,-125) [-125|125] "%"  PCCM,ENGINE_CONTROL_MODULE
 SG_ EngRqedSpeed_SpeedLimit : 8|16@1+ (0.125,0) [0|8031.875] "rpm"  PCCM,ENGINE_CONTROL_MODULE
 SG_ OverrideCtrlModePriority : 4|2@1+ (1,0) [0|3] ""  PCCM,ENGINE_CONTROL_MODULE
 SG_ EngRqedSpeedCtrlConditions : 2|2@1+ (1,0) [0|3] ""  PCCM,ENGINE_CONTROL_MODULE
 SG_ EngOverrideCtrlMode : 0|2@1+ (1,0) [0|3] ""  PCCM,ENGINE_CONTROL_MODULE
 SG_ MessageChecksum : 60|4@1+ (1,0) [0|15] ""  PCCM,ENGINE_CONTROL_MODULE
 SG_ EngineRequestedTorqueHiRes : 40|4@1+ (0.125,0) [0|0.875] "%"  PCCM,ENGINE_CONTROL_MODULE

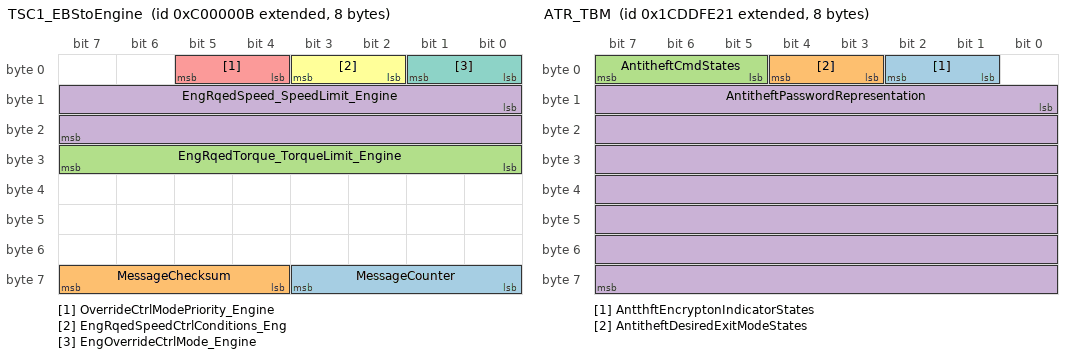
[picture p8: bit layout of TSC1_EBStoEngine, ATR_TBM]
BO_ 2348810251 TSC1_EBStoEngine: 8 EBS
 SG_ MessageCounter : 56|4@1+ (1,0) [0|7] ""  PCCM
 SG_ MessageChecksum : 60|4@1+ (1,0) [0|15] ""  PCCM
 SG_ EngRqedTorque_TorqueLimit_Engine : 24|8@1+ (1,-125) [-125|125] "%"  PCCM,ENGINE_CONTROL_MODULE
 SG_ EngRqedSpeed_SpeedLimit_Engine : 8|16@1+ (0.125,0) [0|8031.875] "rpm"  PCCM,ENGINE_CONTROL_MODULE
 SG_ OverrideCtrlModePriority_Engine : 4|2@1+ (1,0) [0|3] ""  PCCM,ENGINE_CONTROL_MODULE
 SG_ EngRqedSpeedCtrlConditions_Eng : 2|2@1+ (1,0) [0|3] ""  PCCM,ENGINE_CONTROL_MODULE
 SG_ EngOverrideCtrlMode_Engine : 0|2@1+ (1,0) [0|3] ""  PCCM,ENGINE_CONTROL_MODULE

BO_ 2566834699 DM1_EBS: 64 EBS
 SG_ FlashRedStopLamp : 12|2@1+ (1,0) [0|3] ""  PCCM,INSTRUMENT_CLUSTER
 SG_ FlashProtectLamp : 8|2@1+ (1,0) [0|3] ""  PCCM,INSTRUMENT_CLUSTER
 SG_ FlashMalfuncIndicatorLamp : 14|2@1+ (1,0) [0|3] ""  PCCM,INSTRUMENT_CLUSTER
 SG_ FlashAmberWarningLamp : 10|2@1+ (1,0) [0|3] ""  PCCM,INSTRUMENT_CLUSTER
 SG_ MalfunctionIndicatorLampStatus : 6|2@1+ (1,0) [0|3] ""  PCCM,INSTRUMENT_CLUSTER
 SG_ AmberWarningLampStatus : 2|2@1+ (1,0) [0|3] ""  PCCM,INSTRUMENT_CLUSTER
 SG_ RedStopLampState : 4|2@1+ (1,0) [0|3] ""  PCCM,INSTRUMENT_CLUSTER
 SG_ ProtectLampStatus : 0|2@1+ (1,0) [0|3] ""  PCCM,INSTRUMENT_CLUSTER
 SG_ DTC5 : 144|32@1+ (1,0) [0|4294967295] ""  PCCM,INSTRUMENT_CLUSTER
 SG_ DTC4 : 112|32@1+ (1,0) [0|4294967295] ""  PCCM,INSTRUMENT_CLUSTER
 SG_ DTC3 : 80|32@1+ (1,0) [0|4294967295] ""  PCCM,INSTRUMENT_CLUSTER
 SG_ DTC2 : 48|32@1+ (1,0) [0|4294967295] ""  PCCM,INSTRUMENT_CLUSTER
 SG_ DTC1 : 16|32@1+ (1,0) [0|4294967295] ""  PCCM,INSTRUMENT_CLUSTER

BO_ 2566834942 DM1_AST: 22 Vector__XXX
 SG_ FlashRedStopLamp : 12|2@1+ (1,0) [0|3] "" Vector__XXX
 SG_ FlashProtectLamp : 8|2@1+ (1,0) [0|3] "" Vector__XXX
 SG_ FlashMalfuncIndicatorLamp : 14|2@1+ (1,0) [0|3] "" Vector__XXX
 SG_ FlashAmberWarningLamp : 10|2@1+ (1,0) [0|3] "" Vector__XXX
 SG_ MalfunctionIndicatorLampStatus : 6|2@1+ (1,0) [0|3] "" Vector__XXX
 SG_ AmberWarningLampStatus : 2|2@1+ (1,0) [0|3] "" Vector__XXX
 SG_ RedStopLampState : 4|2@1+ (1,0) [0|3] "" Vector__XXX
 SG_ ProtectLampStatus : 0|2@1+ (1,0) [0|3] "" Vector__XXX
 SG_ DTC5 : 144|32@1+ (1,0) [0|4294967295] "" Vector__XXX
 SG_ DTC4 : 112|32@1+ (1,0) [0|4294967295] "" Vector__XXX
 SG_ DTC3 : 80|32@1+ (1,0) [0|4294967295] "" Vector__XXX
 SG_ DTC2 : 48|32@1+ (1,0) [0|4294967295] "" Vector__XXX
 SG_ DTC1 : 16|32@1+ (1,0) [0|4294967295] "" Vector__XXX

BO_ 2566834688 DM1_ECM: 22 ENGINE_CONTROL_MODULE
 SG_ FlashRedStopLamp : 12|2@1+ (1,0) [0|3] ""  LMFS,PCCM,BCM,INSTRUMENT_CLUSTER
 SG_ FlashProtectLamp : 8|2@1+ (1,0) [0|3] ""  LMFS,PCCM,BCM,INSTRUMENT_CLUSTER
 SG_ FlashMalfuncIndicatorLamp : 14|2@1+ (1,0) [0|3] ""  LMFS,PCCM,BCM,INSTRUMENT_CLUSTER
 SG_ FlashAmberWarningLamp : 10|2@1+ (1,0) [0|3] ""  LMFS,PCCM,BCM,INSTRUMENT_CLUSTER
 SG_ MalfunctionIndicatorLampStatus : 6|2@1+ (1,0) [0|3] ""  LMFS,PCCM,BCM,INSTRUMENT_CLUSTER
 SG_ AmberWarningLampStatus : 2|2@1+ (1,0) [0|3] ""  LMFS,PCCM,BCM,INSTRUMENT_CLUSTER
 SG_ RedStopLampState : 4|2@1+ (1,0) [0|3] ""  LMFS,PCCM,BCM,INSTRUMENT_CLUSTER
 SG_ ProtectLampStatus : 0|2@1+ (1,0) [0|3] ""  LMFS,PCCM,BCM,INSTRUMENT_CLUSTER
 SG_ DTC5 : 144|32@1+ (1,0) [0|4294967295] ""  LMFS,PCCM,BCM,INSTRUMENT_CLUSTER
 SG_ DTC4 : 112|32@1+ (1,0) [0|4294967295] ""  LMFS,PCCM,BCM,INSTRUMENT_CLUSTER
 SG_ DTC3 : 80|32@1+ (1,0) [0|4294967295] ""  LMFS,PCCM,BCM,INSTRUMENT_CLUSTER
 SG_ DTC2 : 48|32@1+ (1,0) [0|4294967295] ""  LMFS,PCCM,BCM,INSTRUMENT_CLUSTER
 SG_ DTC1 : 16|32@1+ (1,0) [0|4294967295] ""  LMFS,PCCM,BCM,INSTRUMENT_CLUSTER

BO_ 2566834926 DM1_Tachograph: 64 TACHOGRAPH
 SG_ FlashRedStopLamp : 12|2@1+ (1,0) [0|3] ""  PCCM,INSTRUMENT_CLUSTER
 SG_ FlashProtectLamp : 8|2@1+ (1,0) [0|3] ""  PCCM,INSTRUMENT_CLUSTER
 SG_ FlashMalfuncIndicatorLamp : 14|2@1+ (1,0) [0|3] ""  PCCM,INSTRUMENT_CLUSTER
 SG_ FlashAmberWarningLamp : 10|2@1+ (1,0) [0|3] ""  PCCM,INSTRUMENT_CLUSTER
 SG_ MalfunctionIndicatorLampStatus : 6|2@1+ (1,0) [0|3] ""  PCCM,INSTRUMENT_CLUSTER
 SG_ AmberWarningLampStatus : 2|2@1+ (1,0) [0|3] ""  PCCM,INSTRUMENT_CLUSTER
 SG_ RedStopLampState : 4|2@1+ (1,0) [0|3] ""  PCCM,INSTRUMENT_CLUSTER
 SG_ ProtectLampStatus : 0|2@1+ (1,0) [0|3] ""  PCCM,INSTRUMENT_CLUSTER
 SG_ DTC5 : 144|32@1+ (1,0) [0|4294967295] ""  PCCM,INSTRUMENT_CLUSTER
 SG_ DTC4 : 112|32@1+ (1,0) [0|4294967295] ""  PCCM,INSTRUMENT_CLUSTER
 SG_ DTC3 : 80|32@1+ (1,0) [0|4294967295] ""  PCCM,INSTRUMENT_CLUSTER
 SG_ DTC2 : 48|32@1+ (1,0) [0|4294967295] ""  PCCM,INSTRUMENT_CLUSTER
 SG_ DTC1 : 16|32@1+ (1,0) [0|4294967295] ""  PCCM,INSTRUMENT_CLUSTER

BO_ 2631794209 ATR_TBM: 8 Vector__XXX
 SG_ AntthftEncryptonIndicatorStates : 1|2@1+ (1,0) [0|3] "" Vector__XXX
 SG_ AntitheftDesiredExitModeStates : 3|2@1+ (1,0) [0|3] "" Vector__XXX
 SG_ AntitheftCmdStates : 5|3@1+ (1,0) [0|7] "" Vector__XXX
 SG_ AntitheftPasswordRepresentation : 8|56@1+ (1,0) [0|255] "" Vector__XXX

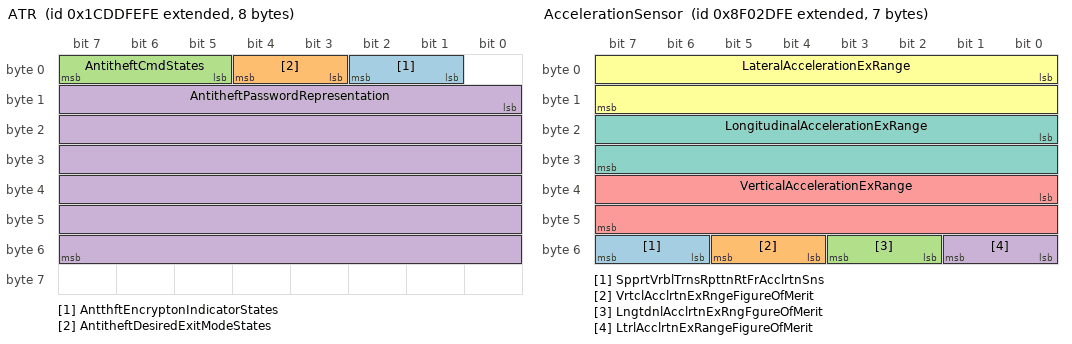
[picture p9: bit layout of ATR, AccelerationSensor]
BO_ 2631794430 ATR: 8 Vector__XXX
 SG_ AntthftEncryptonIndicatorStates : 1|2@1+ (1,0) [0|3] "" Vector__XXX
 SG_ AntitheftDesiredExitModeStates : 3|2@1+ (1,0) [0|3] "" Vector__XXX
 SG_ AntitheftCmdStates : 5|3@1+ (1,0) [0|7] "" Vector__XXX
 SG_ AntitheftPasswordRepresentation : 8|48@1+ (1,0) [0|4] "" Vector__XXX

BO_ 2297441790 AccelerationSensor: 7 Vector__XXX
 SG_ SpprtVrblTrnsRpttnRtFrAcclrtnSns : 54|2@1+ (1,0) [0|3] "" Vector__XXX
 SG_ VrtclAcclrtnExRngeFigureOfMerit : 52|2@1+ (1,0) [0|3] "" Vector__XXX
 SG_ LngtdnlAcclrtnExRngFgureOfMerit : 50|2@1+ (1,0) [0|3] "" Vector__XXX
 SG_ LtrlAcclrtnExRangeFigureOfMerit : 48|2@1+ (1,0) [0|3] "" Vector__XXX
 SG_ VerticalAccelerationExRange : 32|16@1+ (0.01,-320) [-320|322.55] "m/s²" Vector__XXX
 SG_ LateralAccelerationExRange : 0|16@1+ (0.01,-320) [-320|322.55] "m/s²" Vector__XXX
 SG_ LongitudinalAccelerationExRange : 16|16@1+ (0.01,-320) [-320|322.55] "m/s²" Vector__XXX

BO_ 2566712062 VEP4: 8 Vector__XXX
 SG_ HybrdBatteryPackRemainingCharge : 0|16@1+ (0.0025,0) [0|160.6375] "%" Vector__XXX

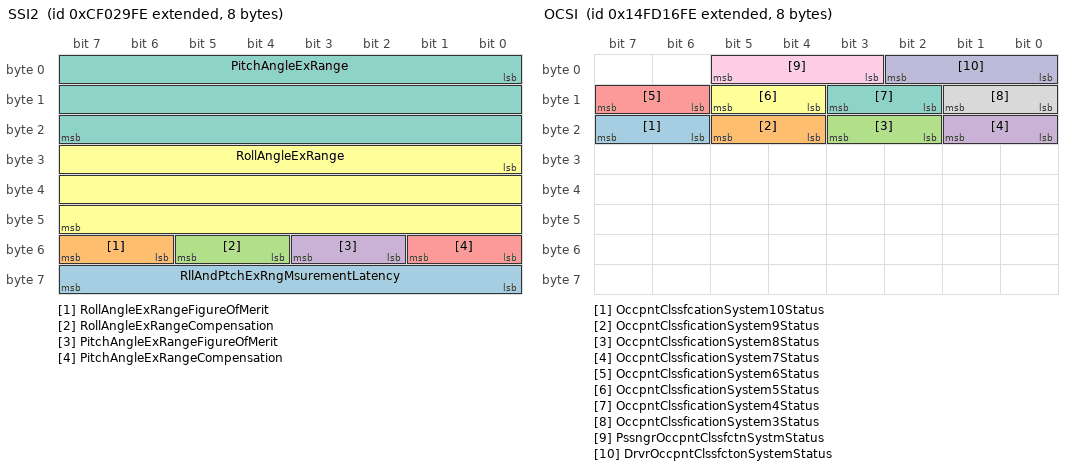
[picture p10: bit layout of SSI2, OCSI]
BO_ 2364549630 SSI2: 8 Vector__XXX
 SG_ RllAndPtchExRngMsurementLatency : 56|8@1+ (0.5,0) [0|125] "ms" Vector__XXX
 SG_ RollAngleExRangeFigureOfMerit : 54|2@1+ (1,0) [0|3] "" Vector__XXX
 SG_ RollAngleExRangeCompensation : 52|2@1+ (1,0) [0|3] "" Vector__XXX
 SG_ PitchAngleExRangeFigureOfMerit : 50|2@1+ (1,0) [0|3] "" Vector__XXX
 SG_ PitchAngleExRangeCompensation : 48|2@1+ (1,0) [0|3] "" Vector__XXX
 SG_ RollAngleExRange : 24|24@1+ (3.0517578125E-005,-250) [-250|250.9999] "deg" Vector__XXX
 SG_ PitchAngleExRange : 0|24@1+ (3.0517578125E-005,-250) [-250|250.9999] "deg" Vector__XXX

BO_ 2499614462 OCSI: 8 Vector__XXX
 SG_ OccpntClssfcationSystem10Status : 22|2@1+ (1,0) [0|3] "" Vector__XXX
 SG_ OccpntClssficationSystem9Status : 20|2@1+ (1,0) [0|3] "" Vector__XXX
 SG_ OccpntClssficationSystem8Status : 18|2@1+ (1,0) [0|3] "" Vector__XXX
 SG_ OccpntClssficationSystem7Status : 16|2@1+ (1,0) [0|3] "" Vector__XXX
 SG_ OccpntClssficationSystem6Status : 14|2@1+ (1,0) [0|3] "" Vector__XXX
 SG_ OccpntClssficationSystem5Status : 12|2@1+ (1,0) [0|3] "" Vector__XXX
 SG_ OccpntClssficationSystem4Status : 10|2@1+ (1,0) [0|3] "" Vector__XXX
 SG_ OccpntClssficationSystem3Status : 8|2@1+ (1,0) [0|3] "" Vector__XXX
 SG_ PssngrOccpntClssfctnSystmStatus : 3|3@1+ (1,0) [0|7] "" Vector__XXX
 SG_ DrvrOccpntClssfctonSystemStatus : 0|3@1+ (1,0) [0|7] "" Vector__XXX

BO_ 2560098046 NCS: 8 Vector__XXX
 SG_ CabNoiseCtrlTuningStatus : 2|4@1+ (1,0) [0|15] "" Vector__XXX
 SG_ CabNoiseCtrlStatus : 0|2@1+ (1,0) [0|3] "" Vector__XXX

BO_ 2560163582 NC1: 8 Vector__XXX
 SG_ CabNoiseCtrlTuningState : 2|3@1+ (1,0) [0|7] "" Vector__XXX
 SG_ CabNoiseCtrlState : 0|2@1+ (1,0) [0|3] "" Vector__XXX

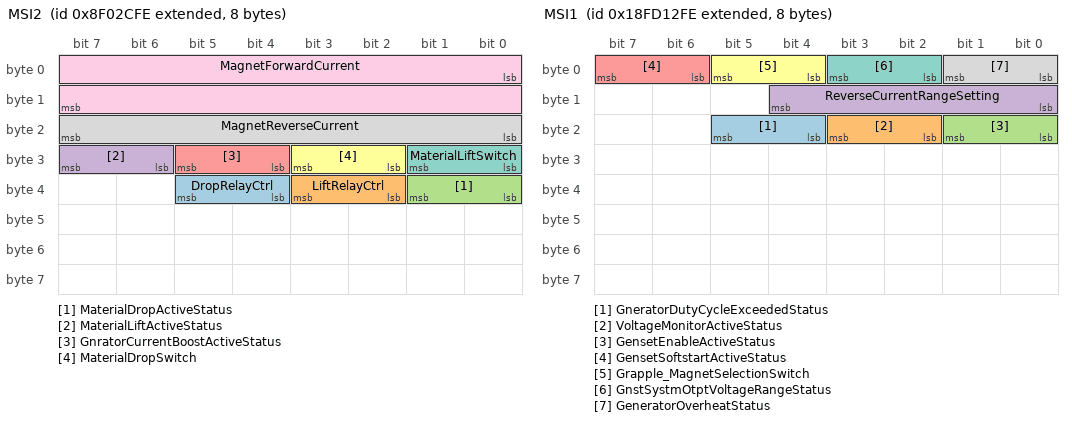
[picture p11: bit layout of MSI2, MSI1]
BO_ 2297441534 MSI2: 8 Vector__XXX
 SG_ DropRelayCtrl : 36|2@1+ (1,0) [0|3] "" Vector__XXX
 SG_ LiftRelayCtrl : 34|2@1+ (1,0) [0|3] "" Vector__XXX
 SG_ MaterialDropActiveStatus : 32|2@1+ (1,0) [0|3] "" Vector__XXX
 SG_ MaterialLiftActiveStatus : 30|2@1+ (1,0) [0|3] "" Vector__XXX
 SG_ GnratorCurrentBoostActiveStatus : 28|2@1+ (1,0) [0|3] "" Vector__XXX
 SG_ MaterialDropSwitch : 26|2@1+ (1,0) [0|3] "" Vector__XXX
 SG_ MaterialLiftSwitch : 24|2@1+ (1,0) [0|3] "" Vector__XXX
 SG_ MagnetReverseCurrent : 16|8@1+ (1,0) [0|250] "A" Vector__XXX
 SG_ MagnetForwardCurrent : 0|16@1+ (1,0) [0|64255] "Amps" Vector__XXX

BO_ 2566722302 MSI1: 8 Vector__XXX
 SG_ GneratorDutyCycleExceededStatus : 20|2@1+ (1,0) [0|3] "" Vector__XXX
 SG_ VoltageMonitorActiveStatus : 18|2@1+ (1,0) [0|3] "" Vector__XXX
 SG_ GensetEnableActiveStatus : 16|2@1+ (1,0) [0|3] "" Vector__XXX
 SG_ ReverseCurrentRangeSetting : 8|5@1+ (1,0) [0|31] "" Vector__XXX
 SG_ GensetSoftstartActiveStatus : 6|2@1+ (1,0) [0|3] "" Vector__XXX
 SG_ Grapple_MagnetSelectionSwitch : 4|2@1+ (1,0) [0|3] "" Vector__XXX
 SG_ GnstSystmOtptVoltageRangeStatus : 2|2@1+ (1,0) [0|3] "" Vector__XXX
 SG_ GeneratorOverheatStatus : 0|2@1+ (1,0) [0|3] "" Vector__XXX

BO_ 2566722558 MSCI: 8 Vector__XXX
 SG_ MagnetRatedPower : 8|16@1+ (0.5,0) [0|32127.5] "kW" Vector__XXX
 SG_ MagnetBoostTime : 0|8@1+ (0.25,0) [0|62.5] "s" Vector__XXX

BO_ 2560032510 LVDSOM: 8 Vector__XXX
 SG_ LwVltgDscnnctDsredOperatingMode : 0|4@1+ (1,0) [0|15] "" Vector__XXX

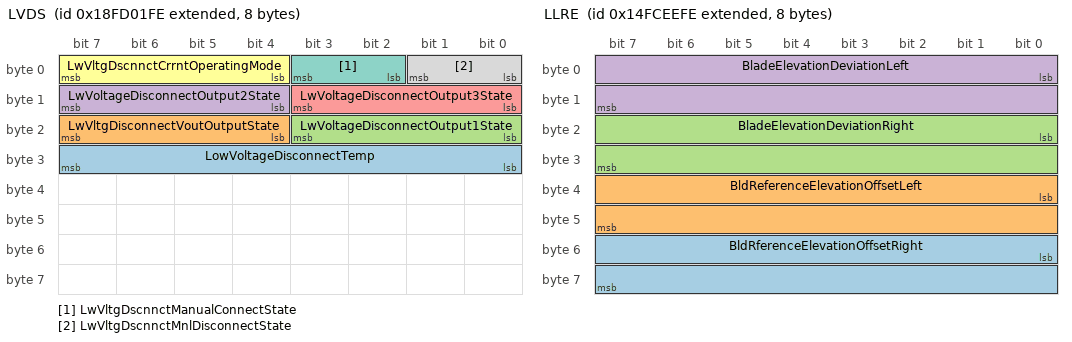
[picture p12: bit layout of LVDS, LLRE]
BO_ 2566717950 LVDS: 8 Vector__XXX
 SG_ LowVoltageDisconnectTemp : 24|8@1+ (1,-40) [-40|210] "deg C" Vector__XXX
 SG_ LwVltgDisconnectVoutOutputState : 20|4@1+ (1,0) [0|15] "" Vector__XXX
 SG_ LwVoltageDisconnectOutput1State : 16|4@1+ (1,0) [0|15] "" Vector__XXX
 SG_ LwVoltageDisconnectOutput2State : 12|4@1+ (1,0) [0|15] "" Vector__XXX
 SG_ LwVoltageDisconnectOutput3State : 8|4@1+ (1,0) [0|15] "" Vector__XXX
 SG_ LwVltgDscnnctCrrntOperatingMode : 4|4@1+ (1,0) [0|15] "" Vector__XXX
 SG_ LwVltgDscnnctManualConnectState : 2|2@1+ (1,0) [0|3] "" Vector__XXX
 SG_ LwVltgDscnnctMnlDisconnectState : 0|2@1+ (1,0) [0|3] "" Vector__XXX

BO_ 2499604222 LLRE: 8 Vector__XXX
 SG_ BldRferenceElevationOffsetRight : 48|16@1+ (1,-32000) [-32000|32255] "mm" Vector__XXX
 SG_ BldReferenceElevationOffsetLeft : 32|16@1+ (1,-32000) [-32000|32255] "mm" Vector__XXX
 SG_ BladeElevationDeviationRight : 16|16@1+ (1,-32000) [-32000|32255] "mm" Vector__XXX
 SG_ BladeElevationDeviationLeft : 0|16@1+ (1,-32000) [-32000|32255] "mm" Vector__XXX

BO_ 2358902526 JLCM: 8 Vector__XXX
 SG_ Joystick3Lamp10Cmd : 58|2@1+ (1,0) [0|3] "" Vector__XXX
 SG_ Joystick3Lamp9Cmd : 56|2@1+ (1,0) [0|3] "" Vector__XXX
 SG_ Joystick3Lamp8Cmd : 54|2@1+ (1,0) [0|3] "" Vector__XXX
 SG_ Joystick3Lamp7Cmd : 52|2@1+ (1,0) [0|3] "" Vector__XXX
 SG_ Joystick3Lamp6Cmd : 50|2@1+ (1,0) [0|3] "" Vector__XXX
 SG_ Joystick3Lamp5Cmd : 48|2@1+ (1,0) [0|3] "" Vector__XXX
 SG_ Joystick3Lamp4Cmd : 46|2@1+ (1,0) [0|3] "" Vector__XXX
 SG_ Joystick3Lamp3Cmd : 44|2@1+ (1,0) [0|3] "" Vector__XXX
 SG_ Joystick3Lamp2Cmd : 42|2@1+ (1,0) [0|3] "" Vector__XXX
 SG_ Joystick3Lamp1Cmd : 40|2@1+ (1,0) [0|3] "" Vector__XXX
 SG_ Joystick2Lamp10Cmd : 38|2@1+ (1,0) [0|3] "" Vector__XXX
 SG_ Joystick2Lamp9Cmd : 36|2@1+ (1,0) [0|3] "" Vector__XXX
 SG_ Joystick2Lamp8Cmd : 34|2@1+ (1,0) [0|3] "" Vector__XXX
 SG_ Joystick2Lamp7Cmd : 32|2@1+ (1,0) [0|3] "" Vector__XXX
 SG_ Joystick2Lamp6Cmd : 30|2@1+ (1,0) [0|3] "" Vector__XXX
 SG_ Joystick2Lamp5Cmd : 28|2@1+ (1,0) [0|3] "" Vector__XXX
 SG_ Joystick2Lamp4Cmd : 26|2@1+ (1,0) [0|3] "" Vector__XXX
 SG_ Joystick2Lamp3Cmd : 24|2@1+ (1,0) [0|3] "" Vector__XXX
 SG_ Joystick2Lamp2Cmd : 22|2@1+ (1,0) [0|3] "" Vector__XXX
 SG_ Joystick2Lamp1Cmd : 20|2@1+ (1,0) [0|3] "" Vector__XXX
 SG_ Joystick1Lamp10Cmd : 18|2@1+ (1,0) [0|3] "" Vector__XXX
 SG_ Joystick1Lamp9Cmd : 16|2@1+ (1,0) [0|3] "" Vector__XXX
 SG_ Joystick1Lamp8Cmd : 14|2@1+ (1,0) [0|3] "" Vector__XXX
 SG_ Joystick1Lamp7Cmd : 12|2@1+ (1,0) [0|3] "" Vector__XXX
 SG_ Joystick1Lamp6Cmd : 10|2@1+ (1,0) [0|3] "" Vector__XXX
 SG_ Joystick1Lamp5Cmd : 8|2@1+ (1,0) [0|3] "" Vector__XXX
 SG_ Joystick1Lamp4Cmd : 6|2@1+ (1,0) [0|3] "" Vector__XXX
 SG_ Joystick1Lamp3Cmd : 4|2@1+ (1,0) [0|3] "" Vector__XXX
 SG_ Joystick1Lamp2Cmd : 2|2@1+ (1,0) [0|3] "" Vector__XXX
 SG_ Joystick1Lamp1Cmd : 0|2@1+ (1,0) [0|3] "" Vector__XXX

BO_ 2566711550 IVAC: 8 Vector__XXX
 SG_ IntkVlvActtnSystmOlPrss2SlndCtrl : 2|2@1+ (1,0) [0|3] "" Vector__XXX
 SG_ IntkVlvActtnSystmOlPrss1SlndCtrl : 0|2@1+ (1,0) [0|3] "" Vector__XXX

BO_ 2633832958 ILI: 200 Vector__XXX
 SG_ SpecialIgnitorLoop90Resistance : 1584|16@1+ (0.1,0) [0|6425.5] "ohm" Vector__XXX
 SG_ SpecialIgnitorLoop89Resistance : 1568|16@1+ (0.1,0) [0|6425.5] "ohm" Vector__XXX
 SG_ SpecialIgnitorLoop88Resistance : 1552|16@1+ (0.1,0) [0|6425.5] "ohm" Vector__XXX
 SG_ SpecialIgnitorLoop87Resistance : 1536|16@1+ (0.1,0) [0|6425.5] "ohm" Vector__XXX
 SG_ SpecialIgnitorLoop86Resistance : 1520|16@1+ (0.1,0) [0|6425.5] "ohm" Vector__XXX
 SG_ SpecialIgnitorLoop85Resistance : 1504|16@1+ (0.1,0) [0|6425.5] "ohm" Vector__XXX
 SG_ SpecialIgnitorLoop84Resistance : 1488|16@1+ (0.1,0) [0|6425.5] "ohm" Vector__XXX
 SG_ SpecialIgnitorLoop83Resistance : 1472|16@1+ (0.1,0) [0|6425.5] "ohm" Vector__XXX
 SG_ SpecialIgnitorLoop82Resistance : 1456|16@1+ (0.1,0) [0|6425.5] "ohm" Vector__XXX
 SG_ SpecialIgnitorLoop81Resistance : 1440|16@1+ (0.1,0) [0|6425.5] "ohm" Vector__XXX
 SG_ SpecialIgnitorLoop80Resistance : 1424|16@1+ (0.1,0) [0|6425.5] "ohm" Vector__XXX
 SG_ SpecialIgnitorLoop79Resistance : 1408|16@1+ (0.1,0) [0|6425.5] "ohm" Vector__XXX
 SG_ SpecialIgnitorLoop78Resistance : 1392|16@1+ (0.1,0) [0|6425.5] "ohm" Vector__XXX
 SG_ SpecialIgnitorLoop77Resistance : 1376|16@1+ (0.1,0) [0|6425.5] "ohm" Vector__XXX
 SG_ SpecialIgnitorLoop76Resistance : 1360|16@1+ (0.1,0) [0|6425.5] "ohm" Vector__XXX
 SG_ SpecialIgnitorLoop75Resistance : 1344|16@1+ (0.1,0) [0|6425.5] "ohm" Vector__XXX
 SG_ SpecialIgnitorLoop74Resistance : 1328|16@1+ (0.1,0) [0|6425.5] "ohm" Vector__XXX
 SG_ SpecialIgnitorLoop73Resistance : 1312|16@1+ (0.1,0) [0|6425.5] "ohm" Vector__XXX
 SG_ SpecialIgnitorLoop72Resistance : 1296|16@1+ (0.1,0) [0|6425.5] "ohm" Vector__XXX
 SG_ SpecialIgnitorLoop71Resistance : 1280|16@1+ (0.1,0) [0|6425.5] "ohm" Vector__XXX
 SG_ SpecialIgnitorLoop70Resistance : 1264|16@1+ (0.1,0) [0|6425.5] "ohm" Vector__XXX
 SG_ SpecialIgnitorLoop69Resistance : 1248|16@1+ (0.1,0) [0|6425.5] "ohm" Vector__XXX
 SG_ SpecialIgnitorLoop68Resistance : 1232|16@1+ (0.1,0) [0|6425.5] "ohm" Vector__XXX
 SG_ SpecialIgnitorLoop67Resistance : 1216|16@1+ (0.1,0) [0|6425.5] "ohm" Vector__XXX
 SG_ SpecialIgnitorLoop66Resistance : 1200|16@1+ (0.1,0) [0|6425.5] "ohm" Vector__XXX
 SG_ SpecialIgnitorLoop65Resistance : 1184|16@1+ (0.1,0) [0|6425.5] "ohm" Vector__XXX
 SG_ SpecialIgnitorLoop64Resistance : 1168|16@1+ (0.1,0) [0|6425.5] "ohm" Vector__XXX
 SG_ SpecialIgnitorLoop63Resistance : 1152|16@1+ (0.1,0) [0|6425.5] "ohm" Vector__XXX
 SG_ SpecialIgnitorLoop61Resistance : 1120|16@1+ (0.1,0) [0|6425.5] "ohm" Vector__XXX
 SG_ SpecialIgnitorLoop60Resistance : 1104|16@1+ (0.1,0) [0|6425.5] "ohm" Vector__XXX
 SG_ SpecialIgnitorLoop59Resistance : 1088|16@1+ (0.1,0) [0|6425.5] "ohm" Vector__XXX
 SG_ SpecialIgnitorLoop58Resistance : 1072|16@1+ (0.1,0) [0|6425.5] "ohm" Vector__XXX
 SG_ SpecialIgnitorLoop57Resistance : 1056|16@1+ (0.1,0) [0|6425.5] "ohm" Vector__XXX
 SG_ SpecialIgnitorLoop56Resistance : 1040|16@1+ (0.1,0) [0|6425.5] "ohm" Vector__XXX
 SG_ SpecialIgnitorLoop55Resistance : 1024|16@1+ (0.1,0) [0|6425.5] "ohm" Vector__XXX
 SG_ SpecialIgnitorLoop54Resistance : 1008|16@1+ (0.1,0) [0|6425.5] "ohm" Vector__XXX
 SG_ SpecialIgnitorLoop53Resistance : 992|16@1+ (0.1,0) [0|6425.5] "ohm" Vector__XXX
 SG_ SpecialIgnitorLoop52Resistance : 976|16@1+ (0.1,0) [0|6425.5] "ohm" Vector__XXX
 SG_ SpecialIgnitorLoop51Resistance : 960|16@1+ (0.1,0) [0|6425.5] "ohm" Vector__XXX
 SG_ SpecialIgnitorLoop50Resistance : 944|16@1+ (0.1,0) [0|6425.5] "ohm" Vector__XXX
 SG_ SpecialIgnitorLoop49Resistance : 928|16@1+ (0.1,0) [0|6425.5] "ohm" Vector__XXX
 SG_ SpecialIgnitorLoop48Resistance : 912|16@1+ (0.1,0) [0|6425.5] "ohm" Vector__XXX
 SG_ SpecialIgnitorLoop47Resistance : 896|16@1+ (0.1,0) [0|6425.5] "ohm" Vector__XXX
 SG_ SpecialIgnitorLoop46Resistance : 880|16@1+ (0.1,0) [0|6425.5] "ohm" Vector__XXX
 SG_ SpecialIgnitorLoop45Resistance : 864|16@1+ (0.1,0) [0|6425.5] "ohm" Vector__XXX
 SG_ SpecialIgnitorLoop44Resistance : 848|16@1+ (0.1,0) [0|6425.5] "ohm" Vector__XXX
 SG_ SpecialIgnitorLoop43Resistance : 832|16@1+ (0.1,0) [0|6425.5] "ohm" Vector__XXX
 SG_ SpecialIgnitorLoop42Resistance : 816|16@1+ (0.1,0) [0|6425.5] "ohm" Vector__XXX
 SG_ SpecialIgnitorLoop41Resistance : 800|16@1+ (0.1,0) [0|6425.5] "ohm" Vector__XXX
 SG_ SpecialIgnitorLoop40Resistance : 784|16@1+ (0.1,0) [0|6425.5] "ohm" Vector__XXX
 SG_ SpecialIgnitorLoop39Resistance : 768|16@1+ (0.1,0) [0|6425.5] "ohm" Vector__XXX
 SG_ SpecialIgnitorLoop38Resistance : 752|16@1+ (0.1,0) [0|6425.5] "ohm" Vector__XXX
 SG_ SpecialIgnitorLoop37Resistance : 736|16@1+ (0.1,0) [0|6425.5] "ohm" Vector__XXX
 SG_ SpecialIgnitorLoop36Resistance : 720|16@1+ (0.1,0) [0|6425.5] "ohm" Vector__XXX
 SG_ SpecialIgnitorLoop35Resistance : 704|16@1+ (0.1,0) [0|6425.5] "ohm" Vector__XXX
 SG_ SpecialIgnitorLoop34Resistance : 688|16@1+ (0.1,0) [0|6425.5] "ohm" Vector__XXX
 SG_ SpecialIgnitorLoop33Resistance : 672|16@1+ (0.1,0) [0|6425.5] "ohm" Vector__XXX
 SG_ SpecialIgnitorLoop32Resistance : 656|16@1+ (0.1,0) [0|6425.5] "ohm" Vector__XXX
 SG_ SpecialIgnitorLoop31Resistance : 640|16@1+ (0.1,0) [0|6425.5] "ohm" Vector__XXX
 SG_ SpecialIgnitorLoop30Resistance : 624|16@1+ (0.1,0) [0|6425.5] "ohm" Vector__XXX
 SG_ SpecialIgnitorLoop29Resistance : 608|16@1+ (0.1,0) [0|6425.5] "ohm" Vector__XXX
 SG_ SpecialIgnitorLoop28Resistance : 592|16@1+ (0.1,0) [0|6425.5] "ohm" Vector__XXX
 SG_ SpecialIgnitorLoop27Resistance : 576|16@1+ (0.1,0) [0|6425.5] "ohm" Vector__XXX
 SG_ SpecialIgnitorLoop26Resistance : 560|16@1+ (0.1,0) [0|6425.5] "ohm" Vector__XXX
 SG_ SpecialIgnitorLoop25Resistance : 544|16@1+ (0.1,0) [0|6425.5] "ohm" Vector__XXX
 SG_ SpecialIgnitorLoop24Resistance : 528|16@1+ (0.1,0) [0|6425.5] "ohm" Vector__XXX
 SG_ SpecialIgnitorLoop23Resistance : 512|16@1+ (0.1,0) [0|6425.5] "ohm" Vector__XXX
 SG_ SpecialIgnitorLoop22Resistance : 496|16@1+ (0.1,0) [0|6425.5] "ohm" Vector__XXX
 SG_ SpecialIgnitorLoop21Resistance : 480|16@1+ (0.1,0) [0|6425.5] "ohm" Vector__XXX
 SG_ SpecialIgnitorLoop20Resistance : 464|16@1+ (0.1,0) [0|6425.5] "ohm" Vector__XXX
 SG_ SpecialIgnitorLoop19Resistance : 448|16@1+ (0.1,0) [0|6425.5] "ohm" Vector__XXX
 SG_ SpecialIgnitorLoop18Resistance : 432|16@1+ (0.1,0) [0|6425.5] "ohm" Vector__XXX
 SG_ SpecialIgnitorLoop17Resistance : 416|16@1+ (0.1,0) [0|6425.5] "ohm" Vector__XXX
 SG_ SpecialIgnitorLoop16Resistance : 400|16@1+ (0.1,0) [0|6425.5] "ohm" Vector__XXX
 SG_ SpecialIgnitorLoop15Resistance : 384|16@1+ (0.1,0) [0|6425.5] "ohm" Vector__XXX
 SG_ SpecialIgnitorLoop14Resistance : 368|16@1+ (0.1,0) [0|6425.5] "ohm" Vector__XXX
 SG_ SpecialIgnitorLoop13Resistance : 352|16@1+ (0.1,0) [0|6425.5] "ohm" Vector__XXX
 SG_ SpecialIgnitorLoop12Resistance : 336|16@1+ (0.1,0) [0|6425.5] "ohm" Vector__XXX
 SG_ SpecialIgnitorLoop11Resistance : 320|16@1+ (0.1,0) [0|6425.5] "ohm" Vector__XXX
 SG_ SpecialIgnitorLoop10Resistance : 304|16@1+ (0.1,0) [0|6425.5] "ohm" Vector__XXX
 SG_ SpecialIgnitorLoop9Resistance : 288|16@1+ (0.1,0) [0|6425.5] "ohm" Vector__XXX
 SG_ SpecialIgnitorLoop8Resistance : 272|16@1+ (0.1,0) [0|6425.5] "ohm" Vector__XXX
 SG_ SpecialIgnitorLoop7Resistance : 256|16@1+ (0.1,0) [0|6425.5] "ohm" Vector__XXX
 SG_ SpecialIgnitorLoop6Resistance : 240|16@1+ (0.1,0) [0|6425.5] "ohm" Vector__XXX
 SG_ SpecialIgnitorLoop5Resistance : 224|16@1+ (0.1,0) [0|6425.5] "ohm" Vector__XXX
 SG_ SpecialIgnitorLoop4Resistance : 208|16@1+ (0.1,0) [0|6425.5] "ohm" Vector__XXX
 SG_ SpecialIgnitorLoop3Resistance : 192|16@1+ (0.1,0) [0|6425.5] "ohm" Vector__XXX
 SG_ SpecialIgnitorLoop2Resistance : 176|16@1+ (0.1,0) [0|6425.5] "ohm" Vector__XXX
 SG_ SpecialIgnitorLoop1Resistance : 160|16@1+ (0.1,0) [0|6425.5] "ohm" Vector__XXX
 SG_ SdBgIgnitorLoop2RightResistance : 144|16@1+ (0.1,0) [0|6425.5] "ohm" Vector__XXX
 SG_ SdBgIgnitorLoop1RightResistance : 128|16@1+ (0.1,0) [0|6425.5] "ohm" Vector__XXX
 SG_ SdBagIgnitorLoop2LeftResistance : 112|16@1+ (0.1,0) [0|6425.5] "ohm" Vector__XXX
 SG_ SdBagIgnitorLoop1LeftResistance : 96|16@1+ (0.1,0) [0|6425.5] "ohm" Vector__XXX
 SG_ PssngrBltTnsnrIgntrLpResistance : 80|16@1+ (0.1,0) [0|6425.5] "ohm" Vector__XXX
 SG_ DrvrBltTnsnrIgntrLoopResistance : 64|16@1+ (0.1,0) [0|6425.5] "ohm" Vector__XXX
 SG_ PssngrArbgIgntrLp2ndStgRsstance : 48|16@1+ (0.1,0) [0|6425.5] "ohm" Vector__XXX
 SG_ DrvrArbgIgntrLp2ndStgResistance : 32|16@1+ (0.1,0) [0|6425.5] "ohm" Vector__XXX
 SG_ PssngrArbgIgntrLp1stStgRsstance : 16|16@1+ (0.1,0) [0|6425.5] "ohm" Vector__XXX
 SG_ DrvrArbgIgntrLp1stStgResistance : 0|16@1+ (0.1,0) [0|6425.5] "ohm" Vector__XXX

BO_ 2566719998 HRLFC: 8 Vector__XXX
 SG_ HighResolutionEngTotalFuelUsed : 32|32@1+ (0.001,0) [0|4211081.215] "L" Vector__XXX
 SG_ HighResolutionEngTripFuel : 0|32@1+ (0.001,0) [0|4211081.215] "L" Vector__XXX

CM_ BO_ 2566841377 "Shutdown";
CM_ SG_ 2566841377 EngOverspeedTest "The engine overspeed test signal as measured by the reporting ECM.";
CM_ SG_ 2566841377 EngAirShutoffCmdStatus "State signal which indicates when the Air Shutoff driver output is being driven.";
CM_ SG_ 2566841377 EngAlarmOutputCmdStatus "State signal which indicates when the Alarm driver output is being driven.";
CM_ SG_ 2566841377 EngAlarmAcknowledge "The Engine Alarm Acknowledge Input signal as measured by the reporting ECM.";
CM_ SG_ 2566841377 EngProtectionSystemConfig "Parameter which indicates the configuration of the engine shutdown system.";
CM_ SG_ 2566841377 EngProtectionSystemTimerState "Status signal which indicates the current mode of the engine protection system timer system.";
CM_ SG_ 2566841377 EngPrtectionSystemTimerOverride "Status signal which indicates the status of the override feature of the engine protection system timer.";
CM_ SG_ 2566841377 EngPrtctnSystmApprchingShutdown "Status signal which indicates that engine shutdown is imminent.";
CM_ SG_ 2566841377 EngWaitToStartLamp "Lamp signal which indicates that the engine is too cold to start and the operator should wait until the signal becomes";
CM_ SG_ 2566841377 RefrigerantHighPressSwitch "Switch signal which indicates the position of the high pressure switch in the coolant circuit of an air conditioning system.";
CM_ SG_ 2566841377 RefrigerantLowPressSwitch "Switch signal which indicates the position of the low pressure switch in the coolant circuit of an air conditioning system.";
CM_ SG_ 2566841377 A_CHighPressFanSwitch "Switch signal which indicates that the pressure in the coolant circuit of an air conditioning system is high and the fan may";
CM_ SG_ 2566841377 EngIdleShutdownTimerFunction "Parameter which indicates the configuration of the idle shutdown timer system.";
CM_ SG_ 2566841377 EngIdleShutdownTimerState "Status signal which indicates the current mode of operation of the idle shutdown timer system.";
CM_ SG_ 2566841377 EngIdleShutdownTimerOverride "Status signal which indicates the status of the override feature of the idle shutdown timer system.";
CM_ SG_ 2566841377 EngIdleShutdownDriverAlertMode "Status signal which indicates the status of the driver alert mode of the idle shutdown timer system.";
CM_ SG_ 2566841377 PTOShutdownHasShutdownEng "Status signal which identifies whether or not the engine has been shutdown by the PTO shutdown system.";
CM_ SG_ 2566841377 EngPrtctnSystmHasShutdownEngine "Status signal which indicates whether or not the engine protection system has shutdown the engine.";
CM_ SG_ 2566841377 EngIdlShutdownHasShutdownEngine "Status signal which identifies whether or not the engine has been shutdown by the idle shutdown timer system.";
CM_ SG_ 2566841377 EngAirShutoffStatus "State signal which indicates the actual measured position of the Air Shutoff.";
CM_ BO_ 2633936126 "Wheel Brake Lining Remaining Information";
CM_ SG_ 2633936126 BrkLnngRmnngAxle4Left "The percentage of brake lining which can still be measured for the right wheel on the rear axle #3.";
CM_ SG_ 2633936126 BrkLnngRmningAxle4Right "The percentage of brake lining which can still be measured for the left wheel on the rear axle #3.";
CM_ SG_ 2633936126 BrkLnngRmnngAxle3Left "The percentage of brake lining which can still be measured for the right wheel on the rear axle #2.";
CM_ SG_ 2633936126 BrkLnngRmningAxle3Right "The percentage of brake lining which can still be measured for the left wheel on the rear axle #2.";
CM_ SG_ 2633936126 BrkLnngRmnngAxle2Left "The percentage of brake lining which can still be measured for the right wheel on the rear axle #1.";
CM_ SG_ 2633936126 BrkLnngRmningAxle2Right "The percentage of brake lining which can still be measured for the left wheel on the rear axle #1.";
CM_ SG_ 2633936126 BrkLnngRmnngAxle1Left "The percentage of brake lining which can still be measured for the right wheel on the front axle.";
CM_ BO_ 2566843681 "Cruise Control/Vehicle Speed Setup";
CM_ SG_ 2566843681 CruiseCtrlLowSetLimitSpeed "Minimum vehicle velocity at which cruise can be set or minimum vehicle velocity for cruise operation before it will exit";
CM_ SG_ 2566843681 CruiseCtrlHighSetLimitSpeed "Maximum vehicle velocity at which cruise can be set.";
CM_ SG_ 2566843681 MaxVehicleSpeedLimit "Maximum vehicle velocity allowed.";
CM_ BO_ 2566844705 "Cruise Control/Vehicle Speed";
CM_ SG_ 2566844705 CruiseCtrlEnableSwitch_BCM "Switch signal which indicates that it is possible to manage the cruise control function.";
CM_ SG_ 2566844705 ParkBrakeReleaseInhibitRq_CCVSB "Park Brake Release Inhibit Request signals the desire that an applied park brake remain applied and limit the ability of the";
CM_ SG_ 2566844705 PTOGovernorState_CCVS_BCM "This parameter is used to indicate the current state or mode of operation by the power takeoff (PTO) governor.";
CM_ SG_ 2566844705 CruiseCtrlAccelerateSwitch_CCVSB "Switch signal of the cruise control activator which indicates that the activator is in the position “accelerate.";
CM_ SG_ 2566844705 CruiseCtrlResumeSwitch_CCVS_BCM "Switch signal of the cruise control activator which indicates that the activator is in the position “resume.";
CM_ SG_ 2566844705 CruiseCtrlCoastSwitch_CCVS_BCM "Switch signal of the cruise control activator which indicates that the activator is in the position “coast (decelerate).";
CM_ SG_ 2566844705 CruiseCtrlOffSwitch "Switch signal of the cruise control activator which indicates that the activator is in the position “set.";
CM_ SG_ 2566844705 ClutchSwitch_CCVS_BCM "Switch signal which indicates that the clutch pedal is being pressed.";
CM_ SG_ 2566844705 BrakeSwitch_CCVS_BCM "Switch signal which indicates that the driver operated brake foot pedal is being pressed.";
CM_ SG_ 2566844705 DamperActivation "Cruise control is switched on.";
CM_ SG_ 2566844705 WheelBasedVehicleSpeed_CCVS_BCM "Speed of the vehicle as calculated from wheel or tailshaft speed.";
CM_ SG_ 2566844705 CruiseCtrlPauseSwitch_CCVS_BCM "Switch signal which indicates the position of the Cruise Control Pause Switch used on Remote Cruise Control applications.";
CM_ SG_ 2566844705 ParkingBrakeSwitch_CCVS_BCM "Switch signal which indicates when the parking brake is set.";
CM_ BO_ 2566834967 "Previously active diagnostic trouble codes";
CM_ SG_ 2566834967 MalfunctionIndicatorLampStatus "A lamp used to relay only emissions-related trouble code information.";
CM_ SG_ 2566834967 RedStopLampState "This lamp is uesed to relay trouble code information that is of a severe enought condition that it warrants stopping the vehicle.";
CM_ SG_ 2566834967 AmberWarningLampStatus "This lamp is used to relay trouble code information that is reporting a problem with the vehicle system but the vehicle need
not be immediately stopped.";
CM_ SG_ 2566834967 ProtectLampStatus "This lamp is used to relay trouble code informatio that is reporting a problem with a vehicle system that is most
probably not electronic subsystem related.";
CM_ SG_ 2566834967 FlashRedStopLamp "This parameter provides the capability to flash the RSL (SPN 3039).";
CM_ SG_ 2566834967 FlashProtectLamp "This parameter provides the capability to flash the engine protect lamp (SPN 3041).";
CM_ SG_ 2566834967 FlashMalfuncIndicatorLamp "This parameter provides the capability to flash the MIL (SPN 3038).";
CM_ SG_ 2566834967 FlashAmberWarningLamp "This parameter provides the capability to flash the AWL (SPN 3040). ";
CM_ SG_ 2566834967 DTC5 "Diagnostic Trouble Code";
CM_ SG_ 2566834967 DTC4 "Diagnostic Trouble Code";
CM_ SG_ 2566834967 DTC3 "Diagnostic Trouble Code";
CM_ SG_ 2566834967 DTC2 "Diagnostic Trouble Code";
CM_ SG_ 2566834967 DTC1 "Diagnostic Trouble Code";
CM_ BO_ 2566834711 "Active diagnostic trouble codes";
CM_ SG_ 2566834711 FlashRedStopLamp "This parameter provides the capability to flash the RSL (SPN 3039).";
CM_ SG_ 2566834711 FlashProtectLamp "This parameter provides the capability to flash the engine protect lamp (SPN 3041).";
CM_ SG_ 2566834711 FlashMalfuncIndicatorLamp "This parameter provides the capability to flash the MIL (SPN 3038).";
CM_ SG_ 2566834711 FlashAmberWarningLamp "This parameter provides the capability to flash the AWL (SPN 3040). ";
CM_ SG_ 2566834711 MalfunctionIndicatorLampStatus "A lamp used to relay only emissions-related trouble code information.";
CM_ SG_ 2566834711 AmberWarningLampStatus "This lamp is used to relay trouble code information that is reporting a problem with the vehicle system but the vehicle need
not be immediately stopped.";
CM_ SG_ 2566834711 RedStopLampState "This lamp is uesed to relay trouble code information that is of a severe enought condition that it warrants stopping the vehicle.";
CM_ SG_ 2566834711 ProtectLampStatus "This lamp is used to relay trouble code informatio that is reporting a problem with a vehicle system that is most
probably not electronic subsystem related.";
CM_ SG_ 2566834711 DTC5 "Diagnostic Trouble Code";
CM_ SG_ 2566834711 DTC4 "Diagnostic Trouble Code";
CM_ SG_ 2566834711 DTC3 "Diagnostic Trouble Code";
CM_ SG_ 2566834711 DTC2 "Diagnostic Trouble Code";
CM_ SG_ 2566834711 DTC1 "Diagnostic Trouble Code";
CM_ BO_ 2161910270 "Anti-theft Status";
CM_ SG_ 2161910270 AntitheftRandomNumber "A seven byte random numeric code provided by the component in response to an anti-theft request.";
CM_ SG_ 2161910270 AntitheftComponentStatusStates "Indicates whether or not the component can be started.";
CM_ SG_ 2161910270 AntthftEncryptnSdPrsntIndicator "Indicates the presence of the encryption seed random number.";
CM_ SG_ 2161910270 AntitheftModifyPwdStates "This parameter is used to indicate whether a password request was successfully performed, or if the request could not be";
CM_ SG_ 2161910270 AntitheftPwdValidIndicator "Indicates the presence of a validated password.";
CM_ BO_ 2566835198 "Previously active diagnostic trouble codes";
CM_ SG_ 2566835198 MalfunctionIndicatorLampStatus "A lamp used to relay only emissions-related trouble code information.";
CM_ SG_ 2566835198 RedStopLampState "This lamp is uesed to relay trouble code information that is of a severe enought condition that it warrants stopping the vehicle.";
CM_ SG_ 2566835198 AmberWarningLampStatus "This lamp is used to relay trouble code information that is reporting a problem with the vehicle system but the vehicle need
not be immediately stopped.";
CM_ SG_ 2566835198 ProtectLampStatus "This lamp is used to relay trouble code informatio that is reporting a problem with a vehicle system that is most
probably not electronic subsystem related.";
CM_ SG_ 2566835198 FlashRedStopLamp "This parameter provides the capability to flash the RSL (SPN 3039).";
CM_ SG_ 2566835198 FlashProtectLamp "This parameter provides the capability to flash the engine protect lamp (SPN 3041).";
CM_ SG_ 2566835198 FlashMalfuncIndicatorLamp "This parameter provides the capability to flash the MIL (SPN 3038).";
CM_ SG_ 2566835198 FlashAmberWarningLamp "This parameter provides the capability to flash the AWL (SPN 3040). ";
CM_ SG_ 2566835198 DTC5 "Diagnostic Trouble Code";
CM_ SG_ 2566835198 DTC4 "Diagnostic Trouble Code";
CM_ SG_ 2566835198 DTC3 "Diagnostic Trouble Code";
CM_ SG_ 2566835198 DTC2 "Diagnostic Trouble Code";
CM_ SG_ 2566835198 DTC1 "Diagnostic Trouble Code";
CM_ BO_ 2566841888 "Time/Date";
CM_ SG_ 2566841888 LocalHourOffset "The hour component of the offset between the UTC (Universal Time Coordinate) time and date and a local time zone time";
CM_ SG_ 2566841888 LocalMinuteOffset "The minute component of the offset between the UTC time and date and a local time zone time and date.";
CM_ SG_ 2566841888 Year "The year component of the current calendar date.";
CM_ SG_ 2566841888 Day "The day component of the current calendar date.";
CM_ SG_ 2566841888 Month "The month component of the current calendar date.";
CM_ SG_ 2566841888 Hours "The hour component of the current time of day.";
CM_ SG_ 2566841888 Minutes "The minutes component of the current time of day.";
CM_ SG_ 2566841888 Seconds "The seconds component of the current time of day.";
CM_ BO_ 2566835710 "Freeze frame parameters";
CM_ SG_ 2566835710 EngIntakeManifold1Press "The gage pressure measurement of the air intake manifold.";
CM_ SG_ 2566835710 FreezeFrameLength "The freeze frame length shall be equal to the number of bytes in the required parameters plus the number of bytes in the
manufacturer specific parameters.";
CM_ SG_ 2566835710 EngSpeed "Actual engine speed which is calculated over a minimum crankshaft angle of 720 degrees divided by the number of cylinders.";
CM_ SG_ 2566835710 EngTorqueMode "State signal which indicates which engine torque mode is currently generating, limiting, or controlling the torque.";
CM_ SG_ 2566835710 WheelBasedVehicleSpeed "Speed of the vehicle as calculated from wheel or tailshaft speed.";
CM_ SG_ 2566835710 EngPercentLoadAtCurrentSpeed "The ratio of actual engine percent torque (indicated) to maximum indicated torque available at the current engine speed,";
CM_ SG_ 2566835710 DTC1 "Diagnostic Trouble Code";
CM_ BO_ 2566840592 "Retarder Configuration";
CM_ SG_ 2566840592 PercentTorqueAtPeakTorquePoint5 "The torque limit that indicates the available retarder torque which can be provided by the retarder at point 5 of the retarder";
CM_ SG_ 2566840592 ReferenceRetarderTorque "This parameter is the 100% reference value for all defined indicated retarder torque parameters.";
CM_ SG_ 2566840592 RetarderSpeedAtPeakTorquePoint5 "Please reference PGN 65249";
CM_ SG_ 2566840592 PercentTorqueAtPoint4 "The torque limit that indicates the available retarder torque which can be provided by the retarder at points 3 and 4 of the";
CM_ SG_ 2566840592 RetarderSpeedAtPoint4 "Retarder speed of point 4 of the engine retarder torque map.";
CM_ SG_ 2566840592 PercentTorqueAtPoint3 "The torque limit that indicates the available retarder torque which can be provided by the retarder at points 3 and 4 of the";
CM_ SG_ 2566840592 RetarderSpeedAtPoint3 "Retarder speed of point 3 of the engine retarder torque map.";
CM_ SG_ 2566840592 PercentTorqueAtMaxSpeedPoint2 "The torque limit that indicates the available retarder torque which can be provided by the retarder at its maximum speed.";
CM_ SG_ 2566840592 MaxRetarderSpeedPoint2 "Maximum speed of retarder (Please reference PGN 65249).";
CM_ SG_ 2566840592 PercentTorqueAtIdlePoint1 "The torque limit that indicates the available retarder torque which can be provided by the retarder at idle speed.";
CM_ SG_ 2566840592 RetarderSpeedAtIdlePoint1 "Please reference PGN 65249";
CM_ SG_ 2566840592 RetarderCtrlMethod "This parameter identifies the number of steps used by the retarder.";
CM_ SG_ 2566840592 RetarderLocation "This parameter defines whether the “torque/speed curve” defined by the retarder configuration message (PGN 65249) is";
CM_ SG_ 2566840592 RetarderType "A vehicle retarder is a supplementary device to the wheel brakes for the driver to better control the vehicle.";
CM_ BO_ 2565865488 "Electronic Retarder Controller 1";
CM_ SG_ 2565865488 RetarderSelectionNonEng "The “Retarder Selection, non-engine” is the position of the driver’s selector for retarders that are not part of the engine";
CM_ SG_ 2565865488 SrcAddrssOfCtrllngDvcFrRtrdrCntr "The source address of the SAE J1939 device currently controlling the retarder.";
CM_ SG_ 2565865488 RetarderRoadSpeedLimitSwitch "Retarder road speed limit switch states:";
CM_ SG_ 2565865488 RetarderRoadSpeedExceededStatus "Retarder Road Speed Exceeded Status:";
CM_ SG_ 2565865488 ActlMxAvlblRtarderPercentTorque "This is the maximum amount of torque that the retarder can immediately deliver.";
CM_ SG_ 2565865488 DrvrsDmandRetarderPercentTorque "The Drivers demand retarder – percent torque is the maximum torque selected by the driver when one or more modes";
CM_ SG_ 2565865488 RetarderRqingBrakeLight "Indicates that whether the retarder is requesting that the brake lights are illuminated.";
CM_ SG_ 2565865488 EngCoolantLoadIncrease "Status of an event, external to the engine, that may increase the nominal temperature of the engine coolant liquid.";
CM_ SG_ 2565865488 IntendedRetarderPercentTorque "Braking torque of retarder that the retarder is currently trying to achieve.";
CM_ SG_ 2565865488 ActualRetarderPercentTorque "Actual braking torque of the retarder as a percent of retarder configuration reference torque SPN 556.";
CM_ SG_ 2565865488 RetarderEnableShiftAssistSwitch "Switch signal which indicates whether the operator wishes the retarder to be enabled for transmission shift assist.";
CM_ SG_ 2565865488 RetarderEnableBrakeAssistSwitch "Switch signal which indicates whether the operator wishes the retarder to be enabled for vehicle braking assist.";
CM_ SG_ 2565865488 RetarderTorqueMode "State signal which indicates which retarder torque mode is currently generating, limiting, or controlling the torque.";
CM_ BO_ 2566834960 "Previously active diagnostic trouble codes";
CM_ SG_ 2566834960 MalfunctionIndicatorLampStatus "A lamp used to relay only emissions-related trouble code information.";
CM_ SG_ 2566834960 RedStopLampState "This lamp is uesed to relay trouble code information that is of a severe enought condition that it warrants stopping the vehicle.";
CM_ SG_ 2566834960 AmberWarningLampStatus "This lamp is used to relay trouble code information that is reporting a problem with the vehicle system but the vehicle need
not be immediately stopped.";
CM_ SG_ 2566834960 ProtectLampStatus "This lamp is used to relay trouble code informatio that is reporting a problem with a vehicle system that is most
probably not electronic subsystem related.";
CM_ SG_ 2566834960 FlashRedStopLamp "This parameter provides the capability to flash the RSL (SPN 3039).";
CM_ SG_ 2566834960 FlashProtectLamp "This parameter provides the capability to flash the engine protect lamp (SPN 3041).";
CM_ SG_ 2566834960 FlashMalfuncIndicatorLamp "This parameter provides the capability to flash the MIL (SPN 3038).";
CM_ SG_ 2566834960 FlashAmberWarningLamp "This parameter provides the capability to flash the AWL (SPN 3040). ";
CM_ SG_ 2566834960 DTC5 "Diagnostic Trouble Code";
CM_ SG_ 2566834960 DTC4 "Diagnostic Trouble Code";
CM_ SG_ 2566834960 DTC3 "Diagnostic Trouble Code";
CM_ SG_ 2566834960 DTC2 "Diagnostic Trouble Code";
CM_ SG_ 2566834960 DTC1 "Diagnostic Trouble Code";
CM_ BO_ 2566834749 "Active diagnostic trouble codes";
CM_ SG_ 2566834749 FlashRedStopLamp "This parameter provides the capability to flash the RSL (SPN 3039).";
CM_ SG_ 2566834749 FlashProtectLamp "This parameter provides the capability to flash the engine protect lamp (SPN 3041).";
CM_ SG_ 2566834749 FlashMalfuncIndicatorLamp "This parameter provides the capability to flash the MIL (SPN 3038).";
CM_ SG_ 2566834749 FlashAmberWarningLamp "This parameter provides the capability to flash the AWL (SPN 3040). ";
CM_ SG_ 2566834749 MalfunctionIndicatorLampStatus "A lamp used to relay only emissions-related trouble code information.";
CM_ SG_ 2566834749 AmberWarningLampStatus "This lamp is used to relay trouble code information that is reporting a problem with the vehicle system but the vehicle need
not be immediately stopped.";
CM_ SG_ 2566834749 RedStopLampState "This lamp is uesed to relay trouble code information that is of a severe enought condition that it warrants stopping the vehicle.";
CM_ SG_ 2566834749 ProtectLampStatus "This lamp is used to relay trouble code informatio that is reporting a problem with a vehicle system that is most
probably not electronic subsystem related.";
CM_ SG_ 2566834749 DTC5 "Diagnostic Trouble Code";
CM_ SG_ 2566834749 DTC4 "Diagnostic Trouble Code";
CM_ SG_ 2566834749 DTC3 "Diagnostic Trouble Code";
CM_ SG_ 2566834749 DTC2 "Diagnostic Trouble Code";
CM_ SG_ 2566834749 DTC1 "Diagnostic Trouble Code";
CM_ BO_ 2348875297 "Torque/Speed Control 1";
CM_ SG_ 2348875297 MessageCounter "The message counter is used to detect situations where the transmitting ECU malfunction repeats the same frame all the time.";
CM_ SG_ 2348875297 ControlPurpose "State signal which indicates which control mode the sending device is using to generate the TSC1 command.";
CM_ SG_ 2348875297 TransmissionRate "This parameter indicates the transmission rate at which the sending device will transmit the TSC1 message.";
CM_ SG_ 2348875297 EngRqedTorque_TorqueLimit "Parameter provided to the engine or retarder in the torque/speed control message for controlling or limiting the output torque.";
CM_ SG_ 2348875297 EngRqedSpeed_SpeedLimit "Parameter provided to the engine from external sources in the torque/speed control message.";
CM_ SG_ 2348875297 EngRqedSpeedCtrlConditions "This mode tells the engine control system the governor characteristics that are desired during speed control.";
CM_ SG_ 2348875297 MessageChecksum "The checksum is used to verify the signal path from the transmitting device to the receiving device.";
CM_ SG_ 2348875297 EngineRequestedTorqueHiRes "This parameter displays an additional torque in percent of the reference engine torque.";
CM_ BO_ 2348810243 "Torque/Speed Control 1";
CM_ SG_ 2348810243 MessageCounter "The message counter is used to detect situations where the transmitting ECU malfunction repeats the same frame all the time.";
CM_ SG_ 2348810243 ControlPurpose "State signal which indicates which control mode the sending device is using to generate the TSC1 command.";
CM_ SG_ 2348810243 TransmissionRate "This parameter indicates the transmission rate at which the sending device will transmit the TSC1 message.";
CM_ SG_ 2348810243 EngRqedTorque_TorqueLimit "Parameter provided to the engine or retarder in the torque/speed control message for controlling or limiting the output torque.";
CM_ SG_ 2348810243 EngRqedSpeed_SpeedLimit "Parameter provided to the engine from external sources in the torque/speed control message.";
CM_ SG_ 2348810243 EngRqedSpeedCtrlConditions "This mode tells the engine control system the governor characteristics that are desired during speed control.";
CM_ SG_ 2348810243 MessageChecksum "The checksum is used to verify the signal path from the transmitting device to the receiving device.";
CM_ SG_ 2348810243 EngineRequestedTorqueHiRes "This parameter displays an additional torque in percent of the reference engine torque.";
CM_ BO_ 2348814091 "Torque/Speed Control 1";
CM_ SG_ 2348814091 EngRqedTorque_ReqstTorque_EngBr "Parameter provided to the engine or retarder in the torque/speed control message for controlling or limiting the output torque.";
CM_ SG_ 2348814091 EngRqedSpeed_reqstspeed_EngBr "Parameter provided to the engine from external sources in the torque/speed control message.";
CM_ SG_ 2348814091 EngRqedSpeedCtrlConditions_EngBr "This mode tells the engine control system the governor characteristics that are desired during speed control.";
CM_ BO_ 2348814083 "Torque/Speed Control 1";
CM_ SG_ 2348814083 MessageCounter "The message counter is used to detect situations where the transmitting ECU malfunction repeats the same frame all the time.";
CM_ SG_ 2348814083 ControlPurpose "State signal which indicates which control mode the sending device is using to generate the TSC1 command.";
CM_ SG_ 2348814083 TransmissionRate "This parameter indicates the transmission rate at which the sending device will transmit the TSC1 message.";
CM_ SG_ 2348814083 EngRqedTorque_TorqueLimit "Parameter provided to the engine or retarder in the torque/speed control message for controlling or limiting the output torque.";
CM_ SG_ 2348814083 EngRqedSpeed_SpeedLimit "Parameter provided to the engine from external sources in the torque/speed control message.";
CM_ SG_ 2348814083 EngRqedSpeedCtrlConditions "This mode tells the engine control system the governor characteristics that are desired during speed control.";
CM_ SG_ 2348814083 MessageChecksum "The checksum is used to verify the signal path from the transmitting device to the receiving device.";
CM_ SG_ 2348814083 EngineRequestedTorqueHiRes "This parameter displays an additional torque in percent of the reference engine torque.";
CM_ BO_ 2348814096 "Torque/Speed Control 1";
CM_ SG_ 2348814096 MessageCounter "The message counter is used to detect situations where the transmitting ECU malfunction repeats the same frame all the time.";
CM_ SG_ 2348814096 ControlPurpose "State signal which indicates which control mode the sending device is using to generate the TSC1 command.";
CM_ SG_ 2348814096 TransmissionRate "This parameter indicates the transmission rate at which the sending device will transmit the TSC1 message.";
CM_ SG_ 2348814096 EngRqedTorque_TorqueLimit "Parameter provided to the engine or retarder in the torque/speed control message for controlling or limiting the output torque.";
CM_ SG_ 2348814096 EngRqedSpeed_SpeedLimit "Parameter provided to the engine from external sources in the torque/speed control message.";
CM_ SG_ 2348814096 EngRqedSpeedCtrlConditions "This mode tells the engine control system the governor characteristics that are desired during speed control.";
CM_ SG_ 2348814096 MessageChecksum "The checksum is used to verify the signal path from the transmitting device to the receiving device.";
CM_ SG_ 2348814096 EngineRequestedTorqueHiRes "This parameter displays an additional torque in percent of the reference engine torque.";
CM_ BO_ 2348810251 "Torque/Speed Control 1";
CM_ SG_ 2348810251 EngRqedTorque_TorqueLimit_Engine "Parameter provided to the engine or retarder in the torque/speed control message for controlling or limiting the output torque.";
CM_ SG_ 2348810251 EngRqedSpeed_SpeedLimit_Engine "Parameter provided to the engine from external sources in the torque/speed control message.";
CM_ SG_ 2348810251 EngRqedSpeedCtrlConditions_Eng "This mode tells the engine control system the governor characteristics that are desired during speed control.";
CM_ BO_ 2566834699 "Active diagnostic trouble codes";
CM_ SG_ 2566834699 FlashRedStopLamp "This parameter provides the capability to flash the RSL (SPN 3039).";
CM_ SG_ 2566834699 FlashProtectLamp "This parameter provides the capability to flash the engine protect lamp (SPN 3041).";
CM_ SG_ 2566834699 FlashMalfuncIndicatorLamp "This parameter provides the capability to flash the MIL (SPN 3038).";
CM_ SG_ 2566834699 FlashAmberWarningLamp "This parameter provides the capability to flash the AWL (SPN 3040). ";
CM_ SG_ 2566834699 MalfunctionIndicatorLampStatus "A lamp used to relay only emissions-related trouble code information.";
CM_ SG_ 2566834699 AmberWarningLampStatus "This lamp is used to relay trouble code information that is reporting a problem with the vehicle system but the vehicle need
not be immediately stopped.";
CM_ SG_ 2566834699 RedStopLampState "This lamp is uesed to relay trouble code information that is of a severe enought condition that it warrants stopping the vehicle.";
CM_ SG_ 2566834699 ProtectLampStatus "This lamp is used to relay trouble code informatio that is reporting a problem with a vehicle system that is most
probably not electronic subsystem related.";
CM_ SG_ 2566834699 DTC5 "Diagnostic Trouble Code";
CM_ SG_ 2566834699 DTC4 "Diagnostic Trouble Code";
CM_ SG_ 2566834699 DTC3 "Diagnostic Trouble Code";
CM_ SG_ 2566834699 DTC2 "Diagnostic Trouble Code";
CM_ SG_ 2566834699 DTC1 "Diagnostic Trouble Code";
CM_ BO_ 2566834942 "Active diagnostic trouble codes";
CM_ SG_ 2566834942 FlashRedStopLamp "This parameter provides the capability to flash the RSL (SPN 3039).";
CM_ SG_ 2566834942 FlashProtectLamp "This parameter provides the capability to flash the engine protect lamp (SPN 3041).";
CM_ SG_ 2566834942 FlashMalfuncIndicatorLamp "This parameter provides the capability to flash the MIL (SPN 3038).";
CM_ SG_ 2566834942 FlashAmberWarningLamp "This parameter provides the capability to flash the AWL (SPN 3040). ";
CM_ SG_ 2566834942 MalfunctionIndicatorLampStatus "A lamp used to relay only emissions-related trouble code information.";
CM_ SG_ 2566834942 AmberWarningLampStatus "This lamp is used to relay trouble code information that is reporting a problem with the vehicle system but the vehicle need
not be immediately stopped.";
CM_ SG_ 2566834942 RedStopLampState "This lamp is uesed to relay trouble code information that is of a severe enought condition that it warrants stopping the vehicle.";
CM_ SG_ 2566834942 ProtectLampStatus "This lamp is used to relay trouble code informatio that is reporting a problem with a vehicle system that is most
probably not electronic subsystem related.";
CM_ SG_ 2566834942 DTC5 "Diagnostic Trouble Code";
CM_ SG_ 2566834942 DTC4 "Diagnostic Trouble Code";
CM_ SG_ 2566834942 DTC3 "Diagnostic Trouble Code";
CM_ SG_ 2566834942 DTC2 "Diagnostic Trouble Code";
CM_ SG_ 2566834942 DTC1 "Diagnostic Trouble Code";
CM_ BO_ 2566834688 "Active diagnostic trouble codes";
CM_ SG_ 2566834688 FlashRedStopLamp "This parameter provides the capability to flash the RSL (SPN 3039).";
CM_ SG_ 2566834688 FlashProtectLamp "This parameter provides the capability to flash the engine protect lamp (SPN 3041).";
CM_ SG_ 2566834688 FlashMalfuncIndicatorLamp "This parameter provides the capability to flash the MIL (SPN 3038).";
CM_ SG_ 2566834688 FlashAmberWarningLamp "This parameter provides the capability to flash the AWL (SPN 3040). ";
CM_ SG_ 2566834688 MalfunctionIndicatorLampStatus "A lamp used to relay only emissions-related trouble code information.";
CM_ SG_ 2566834688 AmberWarningLampStatus "This lamp is used to relay trouble code information that is reporting a problem with the vehicle system but the vehicle need
not be immediately stopped.";
CM_ SG_ 2566834688 RedStopLampState "This lamp is uesed to relay trouble code information that is of a severe enought condition that it warrants stopping the vehicle.";
CM_ SG_ 2566834688 ProtectLampStatus "This lamp is used to relay trouble code informatio that is reporting a problem with a vehicle system that is most
probably not electronic subsystem related.";
CM_ SG_ 2566834688 DTC5 "Diagnostic Trouble Code";
CM_ SG_ 2566834688 DTC4 "Diagnostic Trouble Code";
CM_ SG_ 2566834688 DTC3 "Diagnostic Trouble Code";
CM_ SG_ 2566834688 DTC2 "Diagnostic Trouble Code";
CM_ SG_ 2566834688 DTC1 "Diagnostic Trouble Code";
CM_ BO_ 2566834926 "Active diagnostic trouble codes";
CM_ SG_ 2566834926 FlashRedStopLamp "This parameter provides the capability to flash the RSL (SPN 3039).";
CM_ SG_ 2566834926 FlashProtectLamp "This parameter provides the capability to flash the engine protect lamp (SPN 3041).";
CM_ SG_ 2566834926 FlashMalfuncIndicatorLamp "This parameter provides the capability to flash the MIL (SPN 3038).";
CM_ SG_ 2566834926 FlashAmberWarningLamp "This parameter provides the capability to flash the AWL (SPN 3040). ";
CM_ SG_ 2566834926 MalfunctionIndicatorLampStatus "A lamp used to relay only emissions-related trouble code information.";
CM_ SG_ 2566834926 AmberWarningLampStatus "This lamp is used to relay trouble code information that is reporting a problem with the vehicle system but the vehicle need
not be immediately stopped.";
CM_ SG_ 2566834926 RedStopLampState "This lamp is uesed to relay trouble code information that is of a severe enought condition that it warrants stopping the vehicle.";
CM_ SG_ 2566834926 ProtectLampStatus "This lamp is used to relay trouble code informatio that is reporting a problem with a vehicle system that is most
probably not electronic subsystem related.";
CM_ SG_ 2566834926 DTC5 "Diagnostic Trouble Code";
CM_ SG_ 2566834926 DTC4 "Diagnostic Trouble Code";
CM_ SG_ 2566834926 DTC3 "Diagnostic Trouble Code";
CM_ SG_ 2566834926 DTC2 "Diagnostic Trouble Code";
CM_ SG_ 2566834926 DTC1 "Diagnostic Trouble Code";
CM_ BO_ 2631794209 "Anti-theft Request";
CM_ SG_ 2631794209 AntthftEncryptonIndicatorStates "This parameter is used to indicate if a random number seed is being requested, or if an encrypted password is being";
CM_ SG_ 2631794209 AntitheftDesiredExitModeStates "This parameter is used to specify the desired triggers that are to be used by the component in deciding when to transition";
CM_ SG_ 2631794209 AntitheftCmdStates "This parameter is used to identify the specific requests being sent to the component.";
CM_ SG_ 2631794209 AntitheftPasswordRepresentation "This parameter is the seven byte numeric code (i.";
CM_ BO_ 2631794430 "Anti-theft Request";
CM_ SG_ 2631794430 AntthftEncryptonIndicatorStates "This parameter is used to indicate if a random number seed is being requested, or if an encrypted password is being";
CM_ SG_ 2631794430 AntitheftDesiredExitModeStates "This parameter is used to specify the desired triggers that are to be used by the component in deciding when to transition";
CM_ SG_ 2631794430 AntitheftCmdStates "This parameter is used to identify the specific requests being sent to the component.";
CM_ SG_ 2631794430 AntitheftPasswordRepresentation "This parameter is the seven byte numeric code (i.";
CM_ BO_ 2297441790 "The acceleration sensor message shall provide a measurement of the vehicle's acceleration in the lateral, longitudinal,
and vertical axes.";
CM_ SG_ 2297441790 SpprtVrblTrnsRpttnRtFrAcclrtnSns "Indicates which acceleration transmission rate are supported by the ECU in addition to the required 10 ms transmission";
CM_ SG_ 2297441790 VrtclAcclrtnExRngeFigureOfMerit "Figure of merit for vertical acceleration measurement.";
CM_ SG_ 2297441790 LngtdnlAcclrtnExRngFgureOfMerit "Figure of merit for longitudinal acceleration measurement.";
CM_ SG_ 2297441790 LtrlAcclrtnExRangeFigureOfMerit "Figure of merit for lateral acceleration measurement.";
CM_ SG_ 2297441790 VerticalAccelerationExRange "Indicates vertical acceleration of the vehicle and the effect of gravity.";
CM_ SG_ 2297441790 LateralAccelerationExRange "Indicates lateral acceleration of the vehicle.";
CM_ SG_ 2297441790 LongitudinalAccelerationExRange "Indicates longitudinal acceleration of the vehicle.";
CM_ BO_ 2566712062 "Vehicle Electrical Power #4";
CM_ SG_ 2566712062 HybrdBatteryPackRemainingCharge "Indicates the hybrid battery pack remaining charge.";
CM_ BO_ 2364549630 "Slope Sensor Information 2";
CM_ SG_ 2364549630 RllAndPtchExRngMsurementLatency "Time between start of sensor processing and CAN transmission";
CM_ SG_ 2364549630 RollAngleExRangeFigureOfMerit "Figure of merit for roll angle measurement.";
CM_ SG_ 2364549630 RollAngleExRangeCompensation "Compensated mode for the roll measurement.";
CM_ SG_ 2364549630 PitchAngleExRangeFigureOfMerit "Figure of merit for pitch angle measurement.";
CM_ SG_ 2364549630 PitchAngleExRangeCompensation "Compensated mode for the pitch measurement.";
CM_ SG_ 2364549630 RollAngleExRange "The angle between the vehicle y-axis and the ground plane.";
CM_ SG_ 2364549630 PitchAngleExRange "The angle between the vehicle x-axis and the ground plane.";
CM_ BO_ 2499614462 "Occupant Classification System Information";
CM_ SG_ 2499614462 OccpntClssfcationSystem10Status "State of Occupant Classification System for seat position 10.";
CM_ SG_ 2499614462 OccpntClssficationSystem9Status "State of Occupant Classification System for seat position 9.";
CM_ SG_ 2499614462 OccpntClssficationSystem8Status "State of Occupant Classification System for seat position 8.";
CM_ SG_ 2499614462 OccpntClssficationSystem7Status "State of Occupant Classification System for seat position 7.";
CM_ SG_ 2499614462 OccpntClssficationSystem6Status "State of Occupant Classification System for seat position 6.";
CM_ SG_ 2499614462 OccpntClssficationSystem5Status "State of Occupant Classification System for seat position 5.";
CM_ SG_ 2499614462 OccpntClssficationSystem4Status "State of Occupant Classification System for seat position 4.";
CM_ SG_ 2499614462 OccpntClssficationSystem3Status "State of Occupant Classification System for seat position 3.";
CM_ SG_ 2499614462 PssngrOccpntClssfctnSystmStatus "State of Occupant Classification System for passenger.";
CM_ SG_ 2499614462 DrvrOccpntClssfctonSystemStatus "State of Occupant Classification System for driver.";
CM_ BO_ 2560098046 "Noise Control Status";
CM_ SG_ 2560098046 CabNoiseCtrlTuningStatus "This parameter returns the current status of tuning function of the Cab Noise Control system.";
CM_ SG_ 2560098046 CabNoiseCtrlStatus "This parameter returns the current status of the Cab Noise Control system.";
CM_ BO_ 2560163582 "Noise Control 1";
CM_ SG_ 2560163582 CabNoiseCtrlTuningState "Command values for the Tuning State of the Cab Noise Control System.";
CM_ SG_ 2560163582 CabNoiseCtrlState "Command signal to change the state of the Cab Noise Control System to on-line or off-line";
CM_ BO_ 2297441534 "Magnet Status Information 2";
CM_ SG_ 2297441534 DropRelayCtrl "Command signal used to Engage and Disengage the Drop Relay controlling a Steady-State Magnet.";
CM_ SG_ 2297441534 LiftRelayCtrl "Command signal used to Engage and Disengage the Lift Relay controlling a Steady-State Magnet.";
CM_ SG_ 2297441534 MaterialDropActiveStatus "The status of Material Drop Relay.";
CM_ SG_ 2297441534 MaterialLiftActiveStatus "The status of Material Lift Relay.";
CM_ SG_ 2297441534 GnratorCurrentBoostActiveStatus "Status of generator current boost relay that can boost the generator output current for picking-up material operations.";
CM_ SG_ 2297441534 MaterialDropSwitch "This is a switch that can be used to enable the drop functionality of the Material Handler machine.";
CM_ SG_ 2297441534 MaterialLiftSwitch "This is a switch that can be used to enable the lift functionality of the Material Handler machine.";
CM_ SG_ 2297441534 MagnetReverseCurrent "A reverse current being supplied to the electric magnet to reduce the forward current generated magnet field as quick as";
CM_ SG_ 2297441534 MagnetForwardCurrent "The forward current being supplied by the generator to the electric magnet to create a magnet field to lift material.";
CM_ BO_ 2566722302 "Magnet Status Information 1";
CM_ SG_ 2566722302 GneratorDutyCycleExceededStatus "The status of the duty cycle of the generator usage, indicating if the generator has been on for too much time within a";
CM_ SG_ 2566722302 VoltageMonitorActiveStatus "Status of Voltage Monitor Relay.";
CM_ SG_ 2566722302 GensetEnableActiveStatus "Status of the Genset Enable Relay that enables or disables the Genset.";
CM_ SG_ 2566722302 ReverseCurrentRangeSetting "The operator setting for the Reverse Current.";
CM_ SG_ 2566722302 GensetSoftstartActiveStatus "The Genset Softstart Active Status refers to the status of the genset softstart relay.";
CM_ SG_ 2566722302 Grapple_MagnetSelectionSwitch "This is a switch that can be used to select either the Grapple or Magnet function of the material handler machine.";
CM_ SG_ 2566722302 GnstSystmOtptVoltageRangeStatus "Status of generator voltage in or out of desired operating range.";
CM_ SG_ 2566722302 GeneratorOverheatStatus "The Status of Generator being Overheated.";
CM_ BO_ 2566722558 "Magnet System Configuration Information";
CM_ SG_ 2566722558 MagnetRatedPower "The rated power that the magnet can accept during material holding operations.";
CM_ SG_ 2566722558 MagnetBoostTime "The duration of time after the activation of the magnet circuit that a relatively high current is sent to the magnet for";
CM_ BO_ 2560032510 "Low Voltage Disconnect Set Operating Mode";
CM_ SG_ 2560032510 LwVltgDscnnctDsredOperatingMode "Desired Operating Mode of the LVD.";
CM_ BO_ 2566717950 "Low Voltage Disconnect Status";
CM_ SG_ 2566717950 LowVoltageDisconnectTemp "Internal temperature of the LVD.";
CM_ SG_ 2566717950 LwVltgDisconnectVoutOutputState "State of the Vout Output from the LVD.";
CM_ SG_ 2566717950 LwVoltageDisconnectOutput1State "State of the Output #1 from the LVD.";
CM_ SG_ 2566717950 LwVoltageDisconnectOutput2State "State of the Output #2 from the LVD.";
CM_ SG_ 2566717950 LwVoltageDisconnectOutput3State "State of the Output #3 from the LVD.";
CM_ SG_ 2566717950 LwVltgDscnnctCrrntOperatingMode "Current operating mode of the LVD.";
CM_ SG_ 2566717950 LwVltgDscnnctManualConnectState "State of the Manual Connect hardwired input to the LVD.";
CM_ SG_ 2566717950 LwVltgDscnnctMnlDisconnectState "State of the Manual Disconnect hardwired input to the LVD.";
CM_ BO_ 2499604222 "Land Leveling System Reference Elevation Data";
CM_ SG_ 2499604222 BldRferenceElevationOffsetRight "Indicates the blade's right elevation offset with respect to the reference elevation.";
CM_ SG_ 2499604222 BldReferenceElevationOffsetLeft "Indicates the blade's left elevation offset with respect to the reference elevation.";
CM_ SG_ 2499604222 BladeElevationDeviationRight "Indicate the blade's right elevation deviation with respect to the reference elevation.";
CM_ SG_ 2499604222 BladeElevationDeviationLeft "Indicate the blade's left elevation deviation with respect to the reference elevation.";
CM_ BO_ 2358902526 "Joystick Lamp Command Message";
CM_ SG_ 2358902526 Joystick3Lamp10Cmd "Tells joystick 3 to switch on/off/blinking lamp 10.";
CM_ SG_ 2358902526 Joystick3Lamp9Cmd "Tells joystick 3 to switch on/off/blinking lamp 9.";
CM_ SG_ 2358902526 Joystick3Lamp8Cmd "Tells joystick 3 to switch on/off/blinking lamp 8.";
CM_ SG_ 2358902526 Joystick3Lamp7Cmd "Tells joystick 3 to switch on/off/blinking lamp 7.";
CM_ SG_ 2358902526 Joystick3Lamp6Cmd "Tells joystick 3 to switch on/off/blinking lamp 6.";
CM_ SG_ 2358902526 Joystick3Lamp5Cmd "Tells joystick 3 to switch on/off/blinking lamp 5.";
CM_ SG_ 2358902526 Joystick3Lamp4Cmd "Tells joystick 3 to switch on/off/blinking lamp 4.";
CM_ SG_ 2358902526 Joystick3Lamp3Cmd "Tells joystick 3 to switch on/off/blinking lamp 3.";
CM_ SG_ 2358902526 Joystick3Lamp2Cmd "Tells joystick 3 to switch on/off/blinking lamp 2.";
CM_ SG_ 2358902526 Joystick3Lamp1Cmd "Tells joystick 3 to switch on/off/blinking lamp 1.";
CM_ SG_ 2358902526 Joystick2Lamp10Cmd "Tells joystick 2 to switch on/off/blinking lamp 10.";
CM_ SG_ 2358902526 Joystick2Lamp9Cmd "Tells joystick 2 to switch on/off/blinking lamp 9.";
CM_ SG_ 2358902526 Joystick2Lamp8Cmd "Tells joystick 2 to switch on/off/blinking lamp 8.";
CM_ SG_ 2358902526 Joystick2Lamp7Cmd "Tells joystick 2 to switch on/off/blinking lamp 7.";
CM_ SG_ 2358902526 Joystick2Lamp6Cmd "Tells joystick 2 to switch on/off/blinking lamp 6.";
CM_ SG_ 2358902526 Joystick2Lamp5Cmd "Tells joystick 2 to switch on/off/blinking lamp 5.";
CM_ SG_ 2358902526 Joystick2Lamp4Cmd "Tells joystick 2 to switch on/off/blinking lamp 4.";
CM_ SG_ 2358902526 Joystick2Lamp3Cmd "Tells joystick 2 to switch on/off/blinking lamp 3.";
CM_ SG_ 2358902526 Joystick2Lamp2Cmd "Tells joystick 2 to switch on/off/blinking lamp 2.";
CM_ SG_ 2358902526 Joystick2Lamp1Cmd "Tells joystick 2 to switch on/off/blinking lamp 1.";
CM_ SG_ 2358902526 Joystick1Lamp10Cmd "Tells joystick 1 to switch on/off/blinking lamp 10.";
CM_ SG_ 2358902526 Joystick1Lamp9Cmd "Tells joystick 1 to switch on/off/blinking lamp 9.";
CM_ SG_ 2358902526 Joystick1Lamp8Cmd "Tells joystick 1 to switch on/off/blinking lamp 8.";
CM_ SG_ 2358902526 Joystick1Lamp7Cmd "Tells joystick 1 to switch on/off/blinking lamp 7.";
CM_ SG_ 2358902526 Joystick1Lamp6Cmd "Tells joystick 1 to switch on/off/blinking lamp 6.";
CM_ SG_ 2358902526 Joystick1Lamp5Cmd "Tells joystick 1 to switch on/off/blinking lamp 5.";
CM_ SG_ 2358902526 Joystick1Lamp4Cmd "Tells joystick 1 to switch on/off/blinking lamp 4.";
CM_ SG_ 2358902526 Joystick1Lamp3Cmd "Tells joystick 1 to switch on/off/blinking lamp 3.";
CM_ SG_ 2358902526 Joystick1Lamp2Cmd "Tells joystick 1 to switch on/off/blinking lamp 2.";
CM_ SG_ 2358902526 Joystick1Lamp1Cmd "Tells joystick 1 to switch on/off/blinking lamp 1.";
CM_ BO_ 2566711550 "Intake Valve Actuation Control";
CM_ SG_ 2566711550 IntkVlvActtnSystmOlPrss2SlndCtrl "Indicates the current command to the solenoid that controls the intake valve actuation system oil pressure 2 valve.";
CM_ SG_ 2566711550 IntkVlvActtnSystmOlPrss1SlndCtrl "Indicates the current command to the solenoid that controls the intake valve actuation system oil pressure 1 valve.";
CM_ BO_ 2633832958 "Ignitor Loop Information";
CM_ SG_ 2633832958 SpecialIgnitorLoop90Resistance "Resistance of Special Ignitor Loop 90.";
CM_ SG_ 2633832958 SpecialIgnitorLoop89Resistance "Resistance of Special Ignitor Loop 89.";
CM_ SG_ 2633832958 SpecialIgnitorLoop88Resistance "Resistance of Special Ignitor Loop 88.";
CM_ SG_ 2633832958 SpecialIgnitorLoop87Resistance "Resistance of Special Ignitor Loop 87.";
CM_ SG_ 2633832958 SpecialIgnitorLoop86Resistance "Resistance of Special Ignitor Loop 86.";
CM_ SG_ 2633832958 SpecialIgnitorLoop85Resistance "Resistance of Special Ignitor Loop 85.";
CM_ SG_ 2633832958 SpecialIgnitorLoop84Resistance "Resistance of Special Ignitor Loop 84.";
CM_ SG_ 2633832958 SpecialIgnitorLoop83Resistance "Resistance of Special Ignitor Loop 83.";
CM_ SG_ 2633832958 SpecialIgnitorLoop82Resistance "Resistance of Special Ignitor Loop 82.";
CM_ SG_ 2633832958 SpecialIgnitorLoop81Resistance "Resistance of Special Ignitor Loop 81.";
CM_ SG_ 2633832958 SpecialIgnitorLoop80Resistance "Resistance of Special Ignitor Loop 80.";
CM_ SG_ 2633832958 SpecialIgnitorLoop79Resistance "Resistance of Special Ignitor Loop 79.";
CM_ SG_ 2633832958 SpecialIgnitorLoop78Resistance "Resistance of Special Ignitor Loop 78.";
CM_ SG_ 2633832958 SpecialIgnitorLoop77Resistance "Resistance of Special Ignitor Loop 77.";
CM_ SG_ 2633832958 SpecialIgnitorLoop76Resistance "Resistance of Special Ignitor Loop 76.";
CM_ SG_ 2633832958 SpecialIgnitorLoop75Resistance "Resistance of Special Ignitor Loop 75.";
CM_ SG_ 2633832958 SpecialIgnitorLoop74Resistance "Resistance of Special Ignitor Loop 74.";
CM_ SG_ 2633832958 SpecialIgnitorLoop73Resistance "Resistance of Special Ignitor Loop 73.";
CM_ SG_ 2633832958 SpecialIgnitorLoop72Resistance "Resistance of Special Ignitor Loop 72.";
CM_ SG_ 2633832958 SpecialIgnitorLoop71Resistance "Resistance of Special Ignitor Loop 71.";
CM_ SG_ 2633832958 SpecialIgnitorLoop70Resistance "Resistance of Special Ignitor Loop 70.";
CM_ SG_ 2633832958 SpecialIgnitorLoop69Resistance "Resistance of Special Ignitor Loop 69.";
CM_ SG_ 2633832958 SpecialIgnitorLoop68Resistance "Resistance of Special Ignitor Loop 68.";
CM_ SG_ 2633832958 SpecialIgnitorLoop67Resistance "Resistance of Special Ignitor Loop 67.";
CM_ SG_ 2633832958 SpecialIgnitorLoop66Resistance "Resistance of Special Ignitor Loop 66.";
CM_ SG_ 2633832958 SpecialIgnitorLoop65Resistance "Resistance of Special Ignitor Loop 65.";
CM_ SG_ 2633832958 SpecialIgnitorLoop64Resistance "Resistance of Special Ignitor Loop 64.";
CM_ SG_ 2633832958 SpecialIgnitorLoop63Resistance "Resistance of Special Ignitor Loop 63.";
CM_ SG_ 2633832958 SpecialIgnitorLoop61Resistance "Resistance of Special Ignitor Loop 61.";
CM_ SG_ 2633832958 SpecialIgnitorLoop60Resistance "Resistance of Special Ignitor Loop 60.";
CM_ SG_ 2633832958 SpecialIgnitorLoop59Resistance "Resistance of Special Ignitor Loop 59.";
CM_ SG_ 2633832958 SpecialIgnitorLoop58Resistance "Resistance of Special Ignitor Loop 58.";
CM_ SG_ 2633832958 SpecialIgnitorLoop57Resistance "Resistance of Special Ignitor Loop 57.";
CM_ SG_ 2633832958 SpecialIgnitorLoop56Resistance "Resistance of Special Ignitor Loop 56.";
CM_ SG_ 2633832958 SpecialIgnitorLoop55Resistance "Resistance of Special Ignitor Loop 55.";
CM_ SG_ 2633832958 SpecialIgnitorLoop54Resistance "Resistance of Special Ignitor Loop 54.";
CM_ SG_ 2633832958 SpecialIgnitorLoop53Resistance "Resistance of Special Ignitor Loop 53.";
CM_ SG_ 2633832958 SpecialIgnitorLoop52Resistance "Resistance of Special Ignitor Loop 52.";
CM_ SG_ 2633832958 SpecialIgnitorLoop51Resistance "Resistance of Special Ignitor Loop 51.";
CM_ SG_ 2633832958 SpecialIgnitorLoop50Resistance "Resistance of Special Ignitor Loop 50.";
CM_ SG_ 2633832958 SpecialIgnitorLoop49Resistance "Resistance of Special Ignitor Loop 49.";
CM_ SG_ 2633832958 SpecialIgnitorLoop48Resistance "Resistance of Special Ignitor Loop 48.";
CM_ SG_ 2633832958 SpecialIgnitorLoop47Resistance "Resistance of Special Ignitor Loop 47.";
CM_ SG_ 2633832958 SpecialIgnitorLoop46Resistance "Resistance of Special Ignitor Loop 46.";
CM_ SG_ 2633832958 SpecialIgnitorLoop45Resistance "Resistance of Special Ignitor Loop 45.";
CM_ SG_ 2633832958 SpecialIgnitorLoop44Resistance "Resistance of Special Ignitor Loop 44.";
CM_ SG_ 2633832958 SpecialIgnitorLoop43Resistance "Resistance of Special Ignitor Loop 43.";
CM_ SG_ 2633832958 SpecialIgnitorLoop42Resistance "Resistance of Special Ignitor Loop 42.";
CM_ SG_ 2633832958 SpecialIgnitorLoop41Resistance "Resistance of Special Ignitor Loop 41.";
CM_ SG_ 2633832958 SpecialIgnitorLoop40Resistance "Resistance of Special Ignitor Loop 40.";
CM_ SG_ 2633832958 SpecialIgnitorLoop39Resistance "Resistance of Special Ignitor Loop 39.";
CM_ SG_ 2633832958 SpecialIgnitorLoop38Resistance "Resistance of Special Ignitor Loop 38.";
CM_ SG_ 2633832958 SpecialIgnitorLoop37Resistance "Resistance of Special Ignitor Loop 37.";
CM_ SG_ 2633832958 SpecialIgnitorLoop36Resistance "Resistance of Special Ignitor Loop 36.";
CM_ SG_ 2633832958 SpecialIgnitorLoop35Resistance "Resistance of Special Ignitor Loop 35.";
CM_ SG_ 2633832958 SpecialIgnitorLoop34Resistance "Resistance of Special Ignitor Loop 34.";
CM_ SG_ 2633832958 SpecialIgnitorLoop33Resistance "Resistance of Special Ignitor Loop 33.";
CM_ SG_ 2633832958 SpecialIgnitorLoop32Resistance "Resistance of Special Ignitor Loop 32.";
CM_ SG_ 2633832958 SpecialIgnitorLoop31Resistance "Resistance of Special Ignitor Loop 31.";
CM_ SG_ 2633832958 SpecialIgnitorLoop30Resistance "Resistance of Special Ignitor Loop 30.";
CM_ SG_ 2633832958 SpecialIgnitorLoop29Resistance "Resistance of Special Ignitor Loop 29.";
CM_ SG_ 2633832958 SpecialIgnitorLoop28Resistance "Resistance of Special Ignitor Loop 28.";
CM_ SG_ 2633832958 SpecialIgnitorLoop27Resistance "Resistance of Special Ignitor Loop 27.";
CM_ SG_ 2633832958 SpecialIgnitorLoop26Resistance "Resistance of Special Ignitor Loop 26.";
CM_ SG_ 2633832958 SpecialIgnitorLoop25Resistance "Resistance of Special Ignitor Loop 25.";
CM_ SG_ 2633832958 SpecialIgnitorLoop24Resistance "Resistance of Special Ignitor Loop 24.";
CM_ SG_ 2633832958 SpecialIgnitorLoop23Resistance "Resistance of Special Ignitor Loop 23.";
CM_ SG_ 2633832958 SpecialIgnitorLoop22Resistance "Resistance of Special Ignitor Loop 22.";
CM_ SG_ 2633832958 SpecialIgnitorLoop21Resistance "Resistance of Special Ignitor Loop 21.";
CM_ SG_ 2633832958 SpecialIgnitorLoop20Resistance "Resistance of Special Ignitor Loop 20.";
CM_ SG_ 2633832958 SpecialIgnitorLoop19Resistance "Resistance of Special Ignitor Loop 19.";
CM_ SG_ 2633832958 SpecialIgnitorLoop18Resistance "Resistance of Special Ignitor Loop 18.";
CM_ SG_ 2633832958 SpecialIgnitorLoop17Resistance "Resistance of Special Ignitor Loop 17.";
CM_ SG_ 2633832958 SpecialIgnitorLoop16Resistance "Resistance of Special Ignitor Loop 16.";
CM_ SG_ 2633832958 SpecialIgnitorLoop15Resistance "Resistance of Special Ignitor Loop 15.";
CM_ SG_ 2633832958 SpecialIgnitorLoop14Resistance "Resistance of Special Ignitor Loop 14.";
CM_ SG_ 2633832958 SpecialIgnitorLoop13Resistance "Resistance of Special Ignitor Loop 13.";
CM_ SG_ 2633832958 SpecialIgnitorLoop12Resistance "Resistance of Special Ignitor Loop 12.";
CM_ SG_ 2633832958 SpecialIgnitorLoop11Resistance "Resistance of Special Ignitor Loop 11.";
CM_ SG_ 2633832958 SpecialIgnitorLoop10Resistance "Resistance of Special Ignitor Loop 10.";
CM_ SG_ 2633832958 SpecialIgnitorLoop9Resistance "Resistance of Special Ignitor Loop 9.";
CM_ SG_ 2633832958 SpecialIgnitorLoop8Resistance "Resistance of Special Ignitor Loop 8.";
CM_ SG_ 2633832958 SpecialIgnitorLoop7Resistance "Resistance of Special Ignitor Loop 7.";
CM_ SG_ 2633832958 SpecialIgnitorLoop6Resistance "Resistance of Special Ignitor Loop 6.";
CM_ SG_ 2633832958 SpecialIgnitorLoop5Resistance "Resistance of Special Ignitor Loop 5.";
CM_ SG_ 2633832958 SpecialIgnitorLoop4Resistance "Resistance of Special Ignitor Loop 4.";
CM_ SG_ 2633832958 SpecialIgnitorLoop3Resistance "Resistance of Special Ignitor Loop 3.";
CM_ SG_ 2633832958 SpecialIgnitorLoop2Resistance "Resistance of Special Ignitor Loop 2.";
CM_ SG_ 2633832958 SpecialIgnitorLoop1Resistance "Resistance of Special Ignitor Loop 1.";
CM_ SG_ 2633832958 SdBgIgnitorLoop2RightResistance "Resistance of Side Bag Ignitor Loop 2 - Right.";
CM_ SG_ 2633832958 SdBgIgnitorLoop1RightResistance "Resistance of Side Bag Ignitor Loop 1 - Right.";
CM_ SG_ 2633832958 SdBagIgnitorLoop2LeftResistance "Resistance of Side Bag Ignitor Loop 2 - Left.";
CM_ SG_ 2633832958 SdBagIgnitorLoop1LeftResistance "Resistance of Side Bag Ignitor Loop 1 - Left.";
CM_ SG_ 2633832958 PssngrBltTnsnrIgntrLpResistance "Resistance of Passenger Belt Tensioner Ignitor Loop 1st Stage.";
CM_ SG_ 2633832958 DrvrBltTnsnrIgntrLoopResistance "Resistance of Driver Belt Tensioner Ignitor Loop 1st Stage.";
CM_ SG_ 2633832958 PssngrArbgIgntrLp2ndStgRsstance "Resistance of Passenger Airbag Ignitor Loop 2nd Stage.";
CM_ SG_ 2633832958 DrvrArbgIgntrLp2ndStgResistance "Resistance of Driver Airbag Ignitor Loop 2nd Stage.";
CM_ SG_ 2633832958 PssngrArbgIgntrLp1stStgRsstance "Resistance of Passenger Airbag Ignitor Loop 1st Stage.";
CM_ SG_ 2633832958 DrvrArbgIgntrLp1stStgResistance "Resistance of Driver Airbag Ignitor Loop 1st Stage.";
CM_ BO_ 2566719998 "High Resolution Fuel Consumption (Liquid)";
CM_ SG_ 2566719998 HighResolutionEngTotalFuelUsed "Accumulated amount of fuel used during vehicle operation.";
CM_ SG_ 2566719998 HighResolutionEngTripFuel "Fuel consumed during all or part of a journey.";
BA_DEF_ SG_  "SigType" ENUM  "Default","Range","RangeSigned","ASCII","Discrete","Control","ReferencePGN","DTC","StringDelimiter","StringLength","StringLengthControl";
BA_DEF_ SG_  "GenSigStartValue" INT 0 10000;
BA_DEF_ SG_  "GenSigSendType" ENUM  "Cyclic","OnWrite","reserved","OnChange","reserved","reserved","reserved","NoSigSendType";
BA_DEF_ SG_  "GenSigILSupport" ENUM  "Yes","No";
BA_DEF_ SG_  "GenSigEVName" STRING ;
BA_DEF_ SG_  "SPN" INT 0 524287;
BA_DEF_ BO_  "GenMsgStartDelayTime" INT 0 100000;
BA_DEF_ BO_  "GenMsgILSupport" ENUM  "Yes","No";
BA_DEF_ BO_  "GenMsgDelayTime" INT 0 1000;
BA_DEF_ BO_  "GenMsgRequestable" INT 0 1;
BA_DEF_ BO_  "GenMsgSendType" ENUM  "cyclic","Spontaneus","cyclicIfActive","reserved","reserved","reserved","reserved","reserved","noMsgSendType","OnRequest";
BA_DEF_ BO_  "VFrameFormat" ENUM  "StandardCAN","ExtendedCAN","reserved","J1939PG";
BA_DEF_ BO_  "GenMsgCycleTime" INT 0 3600000;
BA_DEF_ SG_  "SystemSignalLongSymbol" STRING ;
BA_DEF_DEF_  "SigType" "Default";
BA_DEF_DEF_  "GenSigStartValue" 0;
BA_DEF_DEF_  "GenSigSendType" "NoSigSendType";
BA_DEF_DEF_  "GenSigILSupport" "Yes";
BA_DEF_DEF_  "GenSigEVName" "Env@Nodename_@Signame";
BA_DEF_DEF_  "SPN" 0;
BA_DEF_DEF_  "GenMsgStartDelayTime" 0;
BA_DEF_DEF_  "GenMsgILSupport" "Yes";
BA_DEF_DEF_  "GenMsgDelayTime" 0;
BA_DEF_DEF_  "GenMsgRequestable" 1;
BA_DEF_DEF_  "GenMsgSendType" "noMsgSendType";
BA_DEF_DEF_  "VFrameFormat" "J1939PG";
BA_DEF_DEF_  "GenMsgCycleTime" 0;
BA_DEF_DEF_  "SystemSignalLongSymbol" "";
BA_ "GenMsgSendType" BO_ 2566841377 0;
BA_ "GenMsgCycleTime" BO_ 2566841377 1000;
BA_ "GenMsgCycleTime" BO_ 2349541921 200;
BA_ "GenMsgSendType" BO_ 2349541921 0;
BA_ "GenMsgCycleTime" BO_ 2633936126 1000;
BA_ "GenMsgSendType" BO_ 2633936126 0;
BA_ "GenMsgCycleTime" BO_ 2566843681 100;
BA_ "GenMsgSendType" BO_ 2566843681 0;
BA_ "GenMsgCycleTime" BO_ 2566844705 100;
BA_ "GenMsgSendType" BO_ 2566844705 0;
BA_ "GenMsgSendType" BO_ 2566834711 2;
BA_ "GenMsgCycleTime" BO_ 2566834711 1000;
BA_ "GenMsgCycleTime" BO_ 2550596608 50;
BA_ "GenMsgSendType" BO_ 2550596608 0;
BA_ "GenMsgCycleTime" BO_ 2349334270 10;
BA_ "GenMsgSendType" BO_ 2349334270 0;
BA_ "GenMsgSendType" BO_ 2566881534 0;
BA_ "GenMsgCycleTime" BO_ 2566881534 100;
BA_ "GenMsgSendType" BO_ 2565873864 0;
BA_ "GenMsgCycleTime" BO_ 2565873864 50;
BA_ "GenMsgSendType" BO_ 2566882563 0;
BA_ "GenMsgCycleTime" BO_ 2566882563 50;
BA_ "GenMsgSendType" BO_ 2550596157 0;
BA_ "GenMsgCycleTime" BO_ 2550596157 50;
BA_ "GenMsgSendType" BO_ 2550726398 0;
BA_ "GenMsgCycleTime" BO_ 2550726398 50;
BA_ "GenMsgSendType" BO_ 2566804992 0;
BA_ "GenMsgCycleTime" BO_ 2566804992 1000;
BA_ "GenMsgSendType" BO_ 2566857214 0;
BA_ "GenMsgCycleTime" BO_ 2566857214 50;
BA_ "GenMsgSendType" BO_ 2365537790 0;
BA_ "GenMsgCycleTime" BO_ 2365537790 50;
BA_ "GenMsgCycleTime" BO_ 2566841888 1000;
BA_ "GenMsgSendType" BO_ 2566841888 0;
BA_ "GenMsgCycleTime" BO_ 2566840592 5000;
BA_ "GenMsgSendType" BO_ 2566840592 2;
BA_ "GenMsgCycleTime" BO_ 2565865488 100;
BA_ "GenMsgSendType" BO_ 2565865488 0;
BA_ "GenMsgCycleTime" BO_ 2566882819 50;
BA_ "GenMsgSendType" BO_ 2566882819 0;
BA_ "GenMsgCycleTime" BO_ 2566883075 200;
BA_ "GenMsgSendType" BO_ 2566883075 0;
BA_ "GenMsgCycleTime" BO_ 2566834749 1000;
BA_ "GenMsgSendType" BO_ 2566834749 0;
BA_ "GenMsgCycleTime" BO_ 2348875297 10;
BA_ "GenMsgSendType" BO_ 2348875297 0;
BA_ "GenMsgCycleTime" BO_ 2348810243 10;
BA_ "GenMsgSendType" BO_ 2348810243 2;
BA_ "GenMsgCycleTime" BO_ 2348814091 50;
BA_ "GenMsgSendType" BO_ 2348814091 2;
BA_ "GenMsgCycleTime" BO_ 2348814083 50;
BA_ "GenMsgSendType" BO_ 2348814083 2;
BA_ "GenMsgCycleTime" BO_ 2348814096 50;
BA_ "GenMsgSendType" BO_ 2348814096 0;
BA_ "GenMsgCycleTime" BO_ 2348810251 10;
BA_ "GenMsgSendType" BO_ 2348810251 2;
BA_ "GenMsgCycleTime" BO_ 2566834699 1000;
BA_ "GenMsgSendType" BO_ 2566834699 2;
BA_ "GenMsgCycleTime" BO_ 2566834942 1000;
BA_ "GenMsgSendType" BO_ 2566834942 2;
BA_ "GenMsgCycleTime" BO_ 2566834688 1000;
BA_ "GenMsgSendType" BO_ 2566834688 2;
BA_ "GenMsgCycleTime" BO_ 2566834926 1000;
BA_ "GenMsgSendType" BO_ 2566834926 0;
BA_ "GenMsgCycleTime" BO_ 2297441790 10;
BA_ "GenMsgSendType" BO_ 2297441790 0;
BA_ "GenMsgCycleTime" BO_ 2364549630 10;
BA_ "GenMsgSendType" BO_ 2364549630 0;
BA_ "GenMsgCycleTime" BO_ 2297441534 50;
BA_ "GenMsgSendType" BO_ 2297441534 0;
BA_ "GenMsgCycleTime" BO_ 2566722302 500;
BA_ "GenMsgSendType" BO_ 2566722302 0;
BA_ "GenMsgCycleTime" BO_ 2566717950 500;
BA_ "GenMsgSendType" BO_ 2566717950 0;
BA_ "GenMsgCycleTime" BO_ 2499604222 200;
BA_ "GenMsgSendType" BO_ 2499604222 0;
BA_ "GenMsgCycleTime" BO_ 2358902526 100;
BA_ "GenMsgSendType" BO_ 2358902526 0;
BA_ "GenMsgCycleTime" BO_ 2566711550 500;
BA_ "GenMsgSendType" BO_ 2566711550 0;
BA_ "GenMsgCycleTime" BO_ 2566719998 1000;
BA_ "GenMsgSendType" BO_ 2566719998 0;
BA_ "SPN" SG_ 2566841377 EngOverspeedTest 2812;
BA_ "SigType" SG_ 2566841377 EngOverspeedTest 4;
BA_ "SPN" SG_ 2566841377 EngAirShutoffCmdStatus 2813;
BA_ "SigType" SG_ 2566841377 EngAirShutoffCmdStatus 4;
BA_ "SPN" SG_ 2566841377 EngAlarmOutputCmdStatus 2814;
BA_ "SigType" SG_ 2566841377 EngAlarmOutputCmdStatus 4;
BA_ "SPN" SG_ 2566841377 EngAlarmAcknowledge 2815;
BA_ "SigType" SG_ 2566841377 EngAlarmAcknowledge 4;
BA_ "SPN" SG_ 2566841377 EngProtectionSystemConfig 1111;
BA_ "SigType" SG_ 2566841377 EngProtectionSystemConfig 4;
BA_ "SPN" SG_ 2566841377 EngProtectionSystemTimerState 1107;
BA_ "SigType" SG_ 2566841377 EngProtectionSystemTimerState 4;
BA_ "SPN" SG_ 2566841377 EngPrtectionSystemTimerOverride 1108;
BA_ "SigType" SG_ 2566841377 EngPrtectionSystemTimerOverride 4;
BA_ "SPN" SG_ 2566841377 EngPrtctnSystmApprchingShutdown 1109;
BA_ "SigType" SG_ 2566841377 EngPrtctnSystmApprchingShutdown 4;
BA_ "SPN" SG_ 2566841377 EngWaitToStartLamp 1081;
BA_ "SigType" SG_ 2566841377 EngWaitToStartLamp 4;
BA_ "SPN" SG_ 2566841377 RefrigerantHighPressSwitch 605;
BA_ "SigType" SG_ 2566841377 RefrigerantHighPressSwitch 4;
BA_ "SPN" SG_ 2566841377 RefrigerantLowPressSwitch 875;
BA_ "SigType" SG_ 2566841377 RefrigerantLowPressSwitch 4;
BA_ "SPN" SG_ 2566841377 A_CHighPressFanSwitch 985;
BA_ "SigType" SG_ 2566841377 A_CHighPressFanSwitch 4;
BA_ "SPN" SG_ 2566841377 EngIdleShutdownTimerFunction 591;
BA_ "SigType" SG_ 2566841377 EngIdleShutdownTimerFunction 4;
BA_ "SPN" SG_ 2566841377 EngIdleShutdownTimerState 590;
BA_ "SigType" SG_ 2566841377 EngIdleShutdownTimerState 4;
BA_ "SPN" SG_ 2566841377 EngIdleShutdownTimerOverride 592;
BA_ "SigType" SG_ 2566841377 EngIdleShutdownTimerOverride 4;
BA_ "SPN" SG_ 2566841377 EngIdleShutdownDriverAlertMode 594;
BA_ "SigType" SG_ 2566841377 EngIdleShutdownDriverAlertMode 4;
BA_ "SPN" SG_ 2566841377 PTOShutdownHasShutdownEng 5404;
BA_ "SigType" SG_ 2566841377 PTOShutdownHasShutdownEng 4;
BA_ "SPN" SG_ 2566841377 EngPrtctnSystmHasShutdownEngine 1110;
BA_ "SigType" SG_ 2566841377 EngPrtctnSystmHasShutdownEngine 4;
BA_ "SPN" SG_ 2566841377 EngIdlShutdownHasShutdownEngine 593;
BA_ "SigType" SG_ 2566841377 EngIdlShutdownHasShutdownEngine 4;
BA_ "SPN" SG_ 2566841377 EngAirShutoffStatus 3667;
BA_ "SigType" SG_ 2566841377 EngAirShutoffStatus 4;
BA_ "SPN" SG_ 2633936126 BrkLnngRmnngAxle4Left 1106;
BA_ "SigType" SG_ 2633936126 BrkLnngRmnngAxle4Left 1;
BA_ "SPN" SG_ 2633936126 BrkLnngRmningAxle4Right 1105;
BA_ "SigType" SG_ 2633936126 BrkLnngRmningAxle4Right 1;
BA_ "SPN" SG_ 2633936126 BrkLnngRmnngAxle3Left 1104;
BA_ "SigType" SG_ 2633936126 BrkLnngRmnngAxle3Left 1;
BA_ "SPN" SG_ 2633936126 BrkLnngRmningAxle3Right 1103;
BA_ "SigType" SG_ 2633936126 BrkLnngRmningAxle3Right 1;
BA_ "SPN" SG_ 2633936126 BrkLnngRmnngAxle2Left 1102;
BA_ "SigType" SG_ 2633936126 BrkLnngRmnngAxle2Left 1;
BA_ "SPN" SG_ 2633936126 BrkLnngRmningAxle2Right 1101;
BA_ "SigType" SG_ 2633936126 BrkLnngRmningAxle2Right 1;
BA_ "SPN" SG_ 2633936126 BrkLnngRmnngAxle1Left 1100;
BA_ "SigType" SG_ 2633936126 BrkLnngRmnngAxle1Left 1;
BA_ "SPN" SG_ 2633936126 BrkLnngRmningAxle1Right 1099;
BA_ "SigType" SG_ 2633936126 BrkLnngRmningAxle1Right 1;
BA_ "SPN" SG_ 2566843681 CruiseCtrlLowSetLimitSpeed 88;
BA_ "SigType" SG_ 2566843681 CruiseCtrlLowSetLimitSpeed 1;
BA_ "SPN" SG_ 2566843681 CruiseCtrlHighSetLimitSpeed 87;
BA_ "SigType" SG_ 2566843681 CruiseCtrlHighSetLimitSpeed 1;
BA_ "SPN" SG_ 2566843681 MaxVehicleSpeedLimit 74;
BA_ "SigType" SG_ 2566843681 MaxVehicleSpeedLimit 1;
BA_ "SPN" SG_ 2566844705 CruiseCtrlEnableSwitch_BCM 596;
BA_ "SigType" SG_ 2566844705 CruiseCtrlEnableSwitch_BCM 4;
BA_ "SPN" SG_ 2566844705 ParkBrakeReleaseInhibitRq_CCVSB 3807;
BA_ "SigType" SG_ 2566844705 ParkBrakeReleaseInhibitRq_CCVSB 4;
BA_ "SPN" SG_ 2566844705 PTOGovernorState_CCVS_BCM 976;
BA_ "SigType" SG_ 2566844705 PTOGovernorState_CCVS_BCM 4;
BA_ "SPN" SG_ 2566844705 CruiseCtrlAccelerateSwitch_CCVSB 602;
BA_ "SigType" SG_ 2566844705 CruiseCtrlAccelerateSwitch_CCVSB 4;
BA_ "SPN" SG_ 2566844705 CruiseCtrlResumeSwitch_CCVS_BCM 601;
BA_ "SigType" SG_ 2566844705 CruiseCtrlResumeSwitch_CCVS_BCM 4;
BA_ "SPN" SG_ 2566844705 CruiseCtrlCoastSwitch_CCVS_BCM 600;
BA_ "SigType" SG_ 2566844705 CruiseCtrlCoastSwitch_CCVS_BCM 4;
BA_ "SPN" SG_ 2566844705 CruiseCtrlOffSwitch 599;
BA_ "SigType" SG_ 2566844705 CruiseCtrlOffSwitch 4;
BA_ "SPN" SG_ 2566844705 ClutchSwitch_CCVS_BCM 598;
BA_ "SigType" SG_ 2566844705 ClutchSwitch_CCVS_BCM 4;
BA_ "SPN" SG_ 2566844705 BrakeSwitch_CCVS_BCM 597;
BA_ "SigType" SG_ 2566844705 BrakeSwitch_CCVS_BCM 4;
BA_ "SPN" SG_ 2566844705 DamperActivation 595;
BA_ "SigType" SG_ 2566844705 DamperActivation 4;
BA_ "SPN" SG_ 2566844705 WheelBasedVehicleSpeed_CCVS_BCM 84;
BA_ "SigType" SG_ 2566844705 WheelBasedVehicleSpeed_CCVS_BCM 1;
BA_ "SPN" SG_ 2566844705 CruiseCtrlPauseSwitch_CCVS_BCM 1633;
BA_ "SigType" SG_ 2566844705 CruiseCtrlPauseSwitch_CCVS_BCM 4;
BA_ "SPN" SG_ 2566844705 ParkingBrakeSwitch_CCVS_BCM 70;
BA_ "SigType" SG_ 2566844705 ParkingBrakeSwitch_CCVS_BCM 4;
BA_ "SPN" SG_ 2566834967 MalfunctionIndicatorLampStatus 1213;
BA_ "SigType" SG_ 2566834967 MalfunctionIndicatorLampStatus 4;
BA_ "SPN" SG_ 2566834967 RedStopLampState 623;
BA_ "SigType" SG_ 2566834967 RedStopLampState 4;
BA_ "SPN" SG_ 2566834967 AmberWarningLampStatus 624;
BA_ "SigType" SG_ 2566834967 AmberWarningLampStatus 4;
BA_ "SPN" SG_ 2566834967 ProtectLampStatus 987;
BA_ "SigType" SG_ 2566834967 ProtectLampStatus 4;
BA_ "SPN" SG_ 2566834967 FlashRedStopLamp 3039;
BA_ "SigType" SG_ 2566834967 FlashRedStopLamp 4;
BA_ "SPN" SG_ 2566834967 FlashProtectLamp 3041;
BA_ "SigType" SG_ 2566834967 FlashProtectLamp 4;
BA_ "SPN" SG_ 2566834967 FlashMalfuncIndicatorLamp 3038;
BA_ "SigType" SG_ 2566834967 FlashMalfuncIndicatorLamp 4;
BA_ "SPN" SG_ 2566834967 FlashAmberWarningLamp 3040;
BA_ "SigType" SG_ 2566834967 FlashAmberWarningLamp 4;
BA_ "SigType" SG_ 2566834967 DTC5 7;
BA_ "SigType" SG_ 2566834967 DTC4 7;
BA_ "SigType" SG_ 2566834967 DTC3 7;
BA_ "SigType" SG_ 2566834967 DTC2 7;
BA_ "SigType" SG_ 2566834967 DTC1 7;
BA_ "SPN" SG_ 2566834711 FlashRedStopLamp 3039;
BA_ "SigType" SG_ 2566834711 FlashRedStopLamp 4;
BA_ "SPN" SG_ 2566834711 FlashProtectLamp 3041;
BA_ "SigType" SG_ 2566834711 FlashProtectLamp 4;
BA_ "SPN" SG_ 2566834711 FlashMalfuncIndicatorLamp 3038;
BA_ "SigType" SG_ 2566834711 FlashMalfuncIndicatorLamp 4;
BA_ "SPN" SG_ 2566834711 FlashAmberWarningLamp 3040;
BA_ "SigType" SG_ 2566834711 FlashAmberWarningLamp 4;
BA_ "SPN" SG_ 2566834711 MalfunctionIndicatorLampStatus 1213;
BA_ "SigType" SG_ 2566834711 MalfunctionIndicatorLampStatus 4;
BA_ "SPN" SG_ 2566834711 AmberWarningLampStatus 624;
BA_ "SigType" SG_ 2566834711 AmberWarningLampStatus 4;
BA_ "SPN" SG_ 2566834711 RedStopLampState 623;
BA_ "SigType" SG_ 2566834711 RedStopLampState 4;
BA_ "SPN" SG_ 2566834711 ProtectLampStatus 987;
BA_ "SigType" SG_ 2566834711 ProtectLampStatus 4;
BA_ "SigType" SG_ 2566834711 DTC5 7;
BA_ "SigType" SG_ 2566834711 DTC4 7;
BA_ "SigType" SG_ 2566834711 DTC3 7;
BA_ "SigType" SG_ 2566834711 DTC2 7;
BA_ "SigType" SG_ 2566834711 DTC1 7;
BA_ "SPN" SG_ 2161910270 AntitheftRandomNumber 1198;
BA_ "SigType" SG_ 2161910270 AntitheftRandomNumber 1;
BA_ "SPN" SG_ 2161910270 AntitheftComponentStatusStates 1196;
BA_ "SigType" SG_ 2161910270 AntitheftComponentStatusStates 4;
BA_ "SPN" SG_ 2161910270 AntthftEncryptnSdPrsntIndicator 1194;
BA_ "SigType" SG_ 2161910270 AntthftEncryptnSdPrsntIndicator 4;
BA_ "SPN" SG_ 2161910270 AntitheftModifyPwdStates 1197;
BA_ "SigType" SG_ 2161910270 AntitheftModifyPwdStates 4;
BA_ "SPN" SG_ 2161910270 AntitheftPwdValidIndicator 1195;
BA_ "SigType" SG_ 2161910270 AntitheftPwdValidIndicator 4;
BA_ "SPN" SG_ 2566835198 MalfunctionIndicatorLampStatus 1213;
BA_ "SigType" SG_ 2566835198 MalfunctionIndicatorLampStatus 4;
BA_ "SPN" SG_ 2566835198 RedStopLampState 623;
BA_ "SigType" SG_ 2566835198 RedStopLampState 4;
BA_ "SPN" SG_ 2566835198 AmberWarningLampStatus 624;
BA_ "SigType" SG_ 2566835198 AmberWarningLampStatus 4;
BA_ "SPN" SG_ 2566835198 ProtectLampStatus 987;
BA_ "SigType" SG_ 2566835198 ProtectLampStatus 4;
BA_ "SPN" SG_ 2566835198 FlashRedStopLamp 3039;
BA_ "SigType" SG_ 2566835198 FlashRedStopLamp 4;
BA_ "SPN" SG_ 2566835198 FlashProtectLamp 3041;
BA_ "SigType" SG_ 2566835198 FlashProtectLamp 4;
BA_ "SPN" SG_ 2566835198 FlashMalfuncIndicatorLamp 3038;
BA_ "SigType" SG_ 2566835198 FlashMalfuncIndicatorLamp 4;
BA_ "SPN" SG_ 2566835198 FlashAmberWarningLamp 3040;
BA_ "SigType" SG_ 2566835198 FlashAmberWarningLamp 4;
BA_ "SigType" SG_ 2566835198 DTC5 7;
BA_ "SigType" SG_ 2566835198 DTC4 7;
BA_ "SigType" SG_ 2566835198 DTC3 7;
BA_ "SigType" SG_ 2566835198 DTC2 7;
BA_ "SigType" SG_ 2566835198 DTC1 7;
BA_ "GenSigStartValue" SG_ 2566882563 LowestPossibleGear 125;
BA_ "GenSigStartValue" SG_ 2566882563 HighestPossibleGear 125;
BA_ "GenSigStartValue" SG_ 2566882563 CurrentGear 125;
BA_ "GenSigStartValue" SG_ 2566804992 CatalystTankTemperature 40;
BA_ "SPN" SG_ 2566841888 LocalHourOffset 1602;
BA_ "SigType" SG_ 2566841888 LocalHourOffset 1;
BA_ "SPN" SG_ 2566841888 LocalMinuteOffset 1601;
BA_ "SigType" SG_ 2566841888 LocalMinuteOffset 1;
BA_ "SPN" SG_ 2566841888 Year 964;
BA_ "SigType" SG_ 2566841888 Year 1;
BA_ "SPN" SG_ 2566841888 Day 962;
BA_ "SigType" SG_ 2566841888 Day 1;
BA_ "SPN" SG_ 2566841888 Month 963;
BA_ "SigType" SG_ 2566841888 Month 1;
BA_ "SPN" SG_ 2566841888 Hours 961;
BA_ "SigType" SG_ 2566841888 Hours 1;
BA_ "SPN" SG_ 2566841888 Minutes 960;
BA_ "SigType" SG_ 2566841888 Minutes 1;
BA_ "SPN" SG_ 2566841888 Seconds 959;
BA_ "SigType" SG_ 2566841888 Seconds 1;
BA_ "SPN" SG_ 2566835710 EngIntakeManifold1Press 102;
BA_ "SigType" SG_ 2566835710 EngIntakeManifold1Press 1;
BA_ "SPN" SG_ 2566835710 FreezeFrameLength 1217;
BA_ "SPN" SG_ 2566835710 EngSpeed 190;
BA_ "SigType" SG_ 2566835710 EngSpeed 1;
BA_ "SPN" SG_ 2566835710 EngTorqueMode 899;
BA_ "SigType" SG_ 2566835710 EngTorqueMode 4;
BA_ "SPN" SG_ 2566835710 WheelBasedVehicleSpeed 84;
BA_ "SigType" SG_ 2566835710 WheelBasedVehicleSpeed 1;
BA_ "SPN" SG_ 2566835710 EngPercentLoadAtCurrentSpeed 92;
BA_ "SigType" SG_ 2566835710 EngPercentLoadAtCurrentSpeed 1;
BA_ "SPN" SG_ 2566835710 EngineCoolantTemperature 110;
BA_ "SigType" SG_ 2566835710 EngineCoolantTemperature 1;
BA_ "SigType" SG_ 2566835710 DTC1 7;
BA_ "SPN" SG_ 2566840592 PercentTorqueAtPeakTorquePoint5 555;
BA_ "SigType" SG_ 2566840592 PercentTorqueAtPeakTorquePoint5 1;
BA_ "SPN" SG_ 2566840592 ReferenceRetarderTorque 556;
BA_ "SigType" SG_ 2566840592 ReferenceRetarderTorque 1;
BA_ "SPN" SG_ 2566840592 RetarderSpeedAtPeakTorquePoint5 547;
BA_ "SigType" SG_ 2566840592 RetarderSpeedAtPeakTorquePoint5 1;
BA_ "SPN" SG_ 2566840592 PercentTorqueAtPoint4 554;
BA_ "SigType" SG_ 2566840592 PercentTorqueAtPoint4 1;
BA_ "SPN" SG_ 2566840592 RetarderSpeedAtPoint4 550;
BA_ "SigType" SG_ 2566840592 RetarderSpeedAtPoint4 1;
BA_ "SPN" SG_ 2566840592 PercentTorqueAtPoint3 553;
BA_ "SigType" SG_ 2566840592 PercentTorqueAtPoint3 1;
BA_ "SPN" SG_ 2566840592 RetarderSpeedAtPoint3 549;
BA_ "SigType" SG_ 2566840592 RetarderSpeedAtPoint3 1;
BA_ "SPN" SG_ 2566840592 PercentTorqueAtMaxSpeedPoint2 552;
BA_ "SigType" SG_ 2566840592 PercentTorqueAtMaxSpeedPoint2 1;
BA_ "SPN" SG_ 2566840592 MaxRetarderSpeedPoint2 548;
BA_ "SigType" SG_ 2566840592 MaxRetarderSpeedPoint2 1;
BA_ "SPN" SG_ 2566840592 PercentTorqueAtIdlePoint1 551;
BA_ "SigType" SG_ 2566840592 PercentTorqueAtIdlePoint1 1;
BA_ "SPN" SG_ 2566840592 RetarderSpeedAtIdlePoint1 546;
BA_ "SigType" SG_ 2566840592 RetarderSpeedAtIdlePoint1 1;
BA_ "SPN" SG_ 2566840592 RetarderCtrlMethod 557;
BA_ "SigType" SG_ 2566840592 RetarderCtrlMethod 1;
BA_ "SPN" SG_ 2566840592 RetarderLocation 902;
BA_ "SigType" SG_ 2566840592 RetarderLocation 4;
BA_ "SPN" SG_ 2566840592 RetarderType 901;
BA_ "SigType" SG_ 2566840592 RetarderType 4;
BA_ "SPN" SG_ 2565865488 RetarderSelectionNonEng 1716;
BA_ "SigType" SG_ 2565865488 RetarderSelectionNonEng 1;
BA_ "SPN" SG_ 2565865488 SrcAddrssOfCtrllngDvcFrRtrdrCntr 1480;
BA_ "SigType" SG_ 2565865488 SrcAddrssOfCtrllngDvcFrRtrdrCntr 1;
BA_ "SPN" SG_ 2565865488 RetarderRoadSpeedLimitSwitch 4233;
BA_ "SigType" SG_ 2565865488 RetarderRoadSpeedLimitSwitch 4;
BA_ "SPN" SG_ 2565865488 RetarderRoadSpeedExceededStatus 4234;
BA_ "SigType" SG_ 2565865488 RetarderRoadSpeedExceededStatus 4;
BA_ "SPN" SG_ 2565865488 ActlMxAvlblRtarderPercentTorque 1717;
BA_ "SigType" SG_ 2565865488 ActlMxAvlblRtarderPercentTorque 1;
BA_ "SPN" SG_ 2565865488 DrvrsDmandRetarderPercentTorque 1715;
BA_ "SigType" SG_ 2565865488 DrvrsDmandRetarderPercentTorque 1;
BA_ "SPN" SG_ 2565865488 RetarderRqingBrakeLight 1667;
BA_ "SigType" SG_ 2565865488 RetarderRqingBrakeLight 4;
BA_ "SPN" SG_ 2565865488 EngCoolantLoadIncrease 1082;
BA_ "SigType" SG_ 2565865488 EngCoolantLoadIncrease 4;
BA_ "SPN" SG_ 2565865488 IntendedRetarderPercentTorque 1085;
BA_ "SigType" SG_ 2565865488 IntendedRetarderPercentTorque 1;
BA_ "SPN" SG_ 2565865488 ActualRetarderPercentTorque 520;
BA_ "SigType" SG_ 2565865488 ActualRetarderPercentTorque 1;
BA_ "SPN" SG_ 2565865488 RetarderEnableShiftAssistSwitch 572;
BA_ "SigType" SG_ 2565865488 RetarderEnableShiftAssistSwitch 4;
BA_ "SPN" SG_ 2565865488 RetarderEnableBrakeAssistSwitch 571;
BA_ "SigType" SG_ 2565865488 RetarderEnableBrakeAssistSwitch 4;
BA_ "SPN" SG_ 2565865488 RetarderTorqueMode 900;
BA_ "SigType" SG_ 2565865488 RetarderTorqueMode 4;
BA_ "SPN" SG_ 2566834960 MalfunctionIndicatorLampStatus 1213;
BA_ "SigType" SG_ 2566834960 MalfunctionIndicatorLampStatus 4;
BA_ "SPN" SG_ 2566834960 RedStopLampState 623;
BA_ "SigType" SG_ 2566834960 RedStopLampState 4;
BA_ "SPN" SG_ 2566834960 AmberWarningLampStatus 624;
BA_ "SigType" SG_ 2566834960 AmberWarningLampStatus 4;
BA_ "SPN" SG_ 2566834960 ProtectLampStatus 987;
BA_ "SigType" SG_ 2566834960 ProtectLampStatus 4;
BA_ "SPN" SG_ 2566834960 FlashRedStopLamp 3039;
BA_ "SigType" SG_ 2566834960 FlashRedStopLamp 4;
BA_ "SPN" SG_ 2566834960 FlashProtectLamp 3041;
BA_ "SigType" SG_ 2566834960 FlashProtectLamp 4;
BA_ "SPN" SG_ 2566834960 FlashMalfuncIndicatorLamp 3038;
BA_ "SigType" SG_ 2566834960 FlashMalfuncIndicatorLamp 4;
BA_ "SPN" SG_ 2566834960 FlashAmberWarningLamp 3040;
BA_ "SigType" SG_ 2566834960 FlashAmberWarningLamp 4;
BA_ "SigType" SG_ 2566834960 DTC5 7;
BA_ "SigType" SG_ 2566834960 DTC4 7;
BA_ "SigType" SG_ 2566834960 DTC3 7;
BA_ "SigType" SG_ 2566834960 DTC2 7;
BA_ "SigType" SG_ 2566834960 DTC1 7;
BA_ "SPN" SG_ 2566834749 FlashRedStopLamp 3039;
BA_ "SigType" SG_ 2566834749 FlashRedStopLamp 4;
BA_ "SPN" SG_ 2566834749 FlashProtectLamp 3041;
BA_ "SigType" SG_ 2566834749 FlashProtectLamp 4;
BA_ "SPN" SG_ 2566834749 FlashMalfuncIndicatorLamp 3038;
BA_ "SigType" SG_ 2566834749 FlashMalfuncIndicatorLamp 4;
BA_ "SPN" SG_ 2566834749 FlashAmberWarningLamp 3040;
BA_ "SigType" SG_ 2566834749 FlashAmberWarningLamp 4;
BA_ "SPN" SG_ 2566834749 MalfunctionIndicatorLampStatus 1213;
BA_ "SigType" SG_ 2566834749 MalfunctionIndicatorLampStatus 4;
BA_ "SPN" SG_ 2566834749 AmberWarningLampStatus 624;
BA_ "SigType" SG_ 2566834749 AmberWarningLampStatus 4;
BA_ "SPN" SG_ 2566834749 RedStopLampState 623;
BA_ "SigType" SG_ 2566834749 RedStopLampState 4;
BA_ "SPN" SG_ 2566834749 ProtectLampStatus 987;
BA_ "SigType" SG_ 2566834749 ProtectLampStatus 4;
BA_ "SigType" SG_ 2566834749 DTC5 7;
BA_ "SigType" SG_ 2566834749 DTC4 7;
BA_ "SigType" SG_ 2566834749 DTC3 7;
BA_ "SigType" SG_ 2566834749 DTC2 7;
BA_ "SigType" SG_ 2566834749 DTC1 7;
BA_ "SPN" SG_ 2348875297 MessageCounter 4206;
BA_ "SPN" SG_ 2348875297 ControlPurpose 3350;
BA_ "SPN" SG_ 2348875297 TransmissionRate 3349;
BA_ "SPN" SG_ 2348875297 EngRqedTorque_TorqueLimit 518;
BA_ "SigType" SG_ 2348875297 EngRqedTorque_TorqueLimit 1;
BA_ "SPN" SG_ 2348875297 EngRqedSpeed_SpeedLimit 898;
BA_ "SigType" SG_ 2348875297 EngRqedSpeed_SpeedLimit 1;
BA_ "SPN" SG_ 2348875297 OverrideCtrlModePriority 897;
BA_ "SPN" SG_ 2348875297 EngRqedSpeedCtrlConditions 696;
BA_ "SPN" SG_ 2348875297 EngOverrideCtrlMode 695;
BA_ "SPN" SG_ 2348875297 MessageChecksum 4207;
BA_ "SPN" SG_ 2348875297 EngineRequestedTorqueHiRes 4191;
BA_ "SPN" SG_ 2348810243 MessageCounter 4206;
BA_ "SPN" SG_ 2348810243 ControlPurpose 3350;
BA_ "SPN" SG_ 2348810243 TransmissionRate 3349;
BA_ "SPN" SG_ 2348810243 EngRqedTorque_TorqueLimit 518;
BA_ "SigType" SG_ 2348810243 EngRqedTorque_TorqueLimit 1;
BA_ "SPN" SG_ 2348810243 EngRqedSpeed_SpeedLimit 898;
BA_ "SigType" SG_ 2348810243 EngRqedSpeed_SpeedLimit 1;
BA_ "SPN" SG_ 2348810243 OverrideCtrlModePriority 897;
BA_ "SPN" SG_ 2348810243 EngRqedSpeedCtrlConditions 696;
BA_ "SPN" SG_ 2348810243 EngOverrideCtrlMode 695;
BA_ "SPN" SG_ 2348810243 MessageChecksum 4207;
BA_ "SPN" SG_ 2348810243 EngineRequestedTorqueHiRes 4191;
BA_ "SPN" SG_ 2348814091 EngRqedTorque_ReqstTorque_EngBr 518;
BA_ "SigType" SG_ 2348814091 EngRqedTorque_ReqstTorque_EngBr 1;
BA_ "SPN" SG_ 2348814091 EngRqedSpeed_reqstspeed_EngBr 898;
BA_ "SigType" SG_ 2348814091 EngRqedSpeed_reqstspeed_EngBr 1;
BA_ "SPN" SG_ 2348814091 OverrideCtrlModePriority_EngBr 897;
BA_ "SPN" SG_ 2348814091 EngRqedSpeedCtrlConditions_EngBr 696;
BA_ "SPN" SG_ 2348814091 EngOverrideCtrlMode_EngBr 695;
BA_ "SPN" SG_ 2348814083 MessageCounter 4206;
BA_ "SPN" SG_ 2348814083 ControlPurpose 3350;
BA_ "SPN" SG_ 2348814083 TransmissionRate 3349;
BA_ "SPN" SG_ 2348814083 EngRqedTorque_TorqueLimit 518;
BA_ "SigType" SG_ 2348814083 EngRqedTorque_TorqueLimit 1;
BA_ "SPN" SG_ 2348814083 EngRqedSpeed_SpeedLimit 898;
BA_ "SigType" SG_ 2348814083 EngRqedSpeed_SpeedLimit 1;
BA_ "SPN" SG_ 2348814083 OverrideCtrlModePriority 897;
BA_ "SPN" SG_ 2348814083 EngRqedSpeedCtrlConditions 696;
BA_ "SPN" SG_ 2348814083 EngOverrideCtrlMode 695;
BA_ "SPN" SG_ 2348814083 MessageChecksum 4207;
BA_ "SPN" SG_ 2348814083 EngineRequestedTorqueHiRes 4191;
BA_ "SPN" SG_ 2348814096 MessageCounter 4206;
BA_ "SPN" SG_ 2348814096 ControlPurpose 3350;
BA_ "SPN" SG_ 2348814096 TransmissionRate 3349;
BA_ "SPN" SG_ 2348814096 EngRqedTorque_TorqueLimit 518;
BA_ "SigType" SG_ 2348814096 EngRqedTorque_TorqueLimit 1;
BA_ "SPN" SG_ 2348814096 EngRqedSpeed_SpeedLimit 898;
BA_ "SigType" SG_ 2348814096 EngRqedSpeed_SpeedLimit 1;
BA_ "SPN" SG_ 2348814096 OverrideCtrlModePriority 897;
BA_ "SPN" SG_ 2348814096 EngRqedSpeedCtrlConditions 696;
BA_ "SPN" SG_ 2348814096 EngOverrideCtrlMode 695;
BA_ "SPN" SG_ 2348814096 MessageChecksum 4207;
BA_ "SPN" SG_ 2348814096 EngineRequestedTorqueHiRes 4191;
BA_ "SPN" SG_ 2348810251 EngRqedTorque_TorqueLimit_Engine 518;
BA_ "SigType" SG_ 2348810251 EngRqedTorque_TorqueLimit_Engine 1;
BA_ "SPN" SG_ 2348810251 EngRqedSpeed_SpeedLimit_Engine 898;
BA_ "SigType" SG_ 2348810251 EngRqedSpeed_SpeedLimit_Engine 1;
BA_ "SPN" SG_ 2348810251 OverrideCtrlModePriority_Engine 897;
BA_ "SPN" SG_ 2348810251 EngRqedSpeedCtrlConditions_Eng 696;
BA_ "SPN" SG_ 2348810251 EngOverrideCtrlMode_Engine 695;
BA_ "SPN" SG_ 2566834699 FlashRedStopLamp 3039;
BA_ "SigType" SG_ 2566834699 FlashRedStopLamp 4;
BA_ "SPN" SG_ 2566834699 FlashProtectLamp 3041;
BA_ "SigType" SG_ 2566834699 FlashProtectLamp 4;
BA_ "SPN" SG_ 2566834699 FlashMalfuncIndicatorLamp 3038;
BA_ "SigType" SG_ 2566834699 FlashMalfuncIndicatorLamp 4;
BA_ "SPN" SG_ 2566834699 FlashAmberWarningLamp 3040;
BA_ "SigType" SG_ 2566834699 FlashAmberWarningLamp 4;
BA_ "SPN" SG_ 2566834699 MalfunctionIndicatorLampStatus 1213;
BA_ "SigType" SG_ 2566834699 MalfunctionIndicatorLampStatus 4;
BA_ "SPN" SG_ 2566834699 AmberWarningLampStatus 624;
BA_ "SigType" SG_ 2566834699 AmberWarningLampStatus 4;
BA_ "SPN" SG_ 2566834699 RedStopLampState 623;
BA_ "SigType" SG_ 2566834699 RedStopLampState 4;
BA_ "SPN" SG_ 2566834699 ProtectLampStatus 987;
BA_ "SigType" SG_ 2566834699 ProtectLampStatus 4;
BA_ "SigType" SG_ 2566834699 DTC5 7;
BA_ "SigType" SG_ 2566834699 DTC4 7;
BA_ "SigType" SG_ 2566834699 DTC3 7;
BA_ "SigType" SG_ 2566834699 DTC2 7;
BA_ "SigType" SG_ 2566834699 DTC1 7;
BA_ "SPN" SG_ 2566834942 FlashRedStopLamp 3039;
BA_ "SigType" SG_ 2566834942 FlashRedStopLamp 4;
BA_ "SPN" SG_ 2566834942 FlashProtectLamp 3041;
BA_ "SigType" SG_ 2566834942 FlashProtectLamp 4;
BA_ "SPN" SG_ 2566834942 FlashMalfuncIndicatorLamp 3038;
BA_ "SigType" SG_ 2566834942 FlashMalfuncIndicatorLamp 4;
BA_ "SPN" SG_ 2566834942 FlashAmberWarningLamp 3040;
BA_ "SigType" SG_ 2566834942 FlashAmberWarningLamp 4;
BA_ "SPN" SG_ 2566834942 MalfunctionIndicatorLampStatus 1213;
BA_ "SigType" SG_ 2566834942 MalfunctionIndicatorLampStatus 4;
BA_ "SPN" SG_ 2566834942 AmberWarningLampStatus 624;
BA_ "SigType" SG_ 2566834942 AmberWarningLampStatus 4;
BA_ "SPN" SG_ 2566834942 RedStopLampState 623;
BA_ "SigType" SG_ 2566834942 RedStopLampState 4;
BA_ "SPN" SG_ 2566834942 ProtectLampStatus 987;
BA_ "SigType" SG_ 2566834942 ProtectLampStatus 4;
BA_ "SigType" SG_ 2566834942 DTC5 7;
BA_ "SigType" SG_ 2566834942 DTC4 7;
BA_ "SigType" SG_ 2566834942 DTC3 7;
BA_ "SigType" SG_ 2566834942 DTC2 7;
BA_ "SigType" SG_ 2566834942 DTC1 7;
BA_ "SPN" SG_ 2566834688 FlashRedStopLamp 3039;
BA_ "SigType" SG_ 2566834688 FlashRedStopLamp 4;
BA_ "SPN" SG_ 2566834688 FlashProtectLamp 3041;
BA_ "SigType" SG_ 2566834688 FlashProtectLamp 4;
BA_ "SPN" SG_ 2566834688 FlashMalfuncIndicatorLamp 3038;
BA_ "SigType" SG_ 2566834688 FlashMalfuncIndicatorLamp 4;
BA_ "SPN" SG_ 2566834688 FlashAmberWarningLamp 3040;
BA_ "SigType" SG_ 2566834688 FlashAmberWarningLamp 4;
BA_ "SPN" SG_ 2566834688 MalfunctionIndicatorLampStatus 1213;
BA_ "SigType" SG_ 2566834688 MalfunctionIndicatorLampStatus 4;
BA_ "SPN" SG_ 2566834688 AmberWarningLampStatus 624;
BA_ "SigType" SG_ 2566834688 AmberWarningLampStatus 4;
BA_ "SPN" SG_ 2566834688 RedStopLampState 623;
BA_ "SigType" SG_ 2566834688 RedStopLampState 4;
BA_ "SPN" SG_ 2566834688 ProtectLampStatus 987;
BA_ "SigType" SG_ 2566834688 ProtectLampStatus 4;
BA_ "SigType" SG_ 2566834688 DTC5 7;
BA_ "SigType" SG_ 2566834688 DTC4 7;
BA_ "SigType" SG_ 2566834688 DTC3 7;
BA_ "SigType" SG_ 2566834688 DTC2 7;
BA_ "SigType" SG_ 2566834688 DTC1 7;
BA_ "SPN" SG_ 2566834926 FlashRedStopLamp 3039;
BA_ "SigType" SG_ 2566834926 FlashRedStopLamp 4;
BA_ "SPN" SG_ 2566834926 FlashProtectLamp 3041;
BA_ "SigType" SG_ 2566834926 FlashProtectLamp 4;
BA_ "SPN" SG_ 2566834926 FlashMalfuncIndicatorLamp 3038;
BA_ "SigType" SG_ 2566834926 FlashMalfuncIndicatorLamp 4;
BA_ "SPN" SG_ 2566834926 FlashAmberWarningLamp 3040;
BA_ "SigType" SG_ 2566834926 FlashAmberWarningLamp 4;
BA_ "SPN" SG_ 2566834926 MalfunctionIndicatorLampStatus 1213;
BA_ "SigType" SG_ 2566834926 MalfunctionIndicatorLampStatus 4;
BA_ "SPN" SG_ 2566834926 AmberWarningLampStatus 624;
BA_ "SigType" SG_ 2566834926 AmberWarningLampStatus 4;
BA_ "SPN" SG_ 2566834926 RedStopLampState 623;
BA_ "SigType" SG_ 2566834926 RedStopLampState 4;
BA_ "SPN" SG_ 2566834926 ProtectLampStatus 987;
BA_ "SigType" SG_ 2566834926 ProtectLampStatus 4;
BA_ "SigType" SG_ 2566834926 DTC5 7;
BA_ "SigType" SG_ 2566834926 DTC4 7;
BA_ "SigType" SG_ 2566834926 DTC3 7;
BA_ "SigType" SG_ 2566834926 DTC2 7;
BA_ "SigType" SG_ 2566834926 DTC1 7;
BA_ "SPN" SG_ 2631794209 AntthftEncryptonIndicatorStates 1199;
BA_ "SigType" SG_ 2631794209 AntthftEncryptonIndicatorStates 4;
BA_ "SPN" SG_ 2631794209 AntitheftDesiredExitModeStates 1200;
BA_ "SigType" SG_ 2631794209 AntitheftDesiredExitModeStates 4;
BA_ "SPN" SG_ 2631794209 AntitheftCmdStates 1201;
BA_ "SPN" SG_ 2631794209 AntitheftPasswordRepresentation 1202;
BA_ "SigType" SG_ 2631794209 AntitheftPasswordRepresentation 1;
BA_ "SPN" SG_ 2631794430 AntthftEncryptonIndicatorStates 1199;
BA_ "SigType" SG_ 2631794430 AntthftEncryptonIndicatorStates 4;
BA_ "SPN" SG_ 2631794430 AntitheftDesiredExitModeStates 1200;
BA_ "SigType" SG_ 2631794430 AntitheftDesiredExitModeStates 4;
BA_ "SPN" SG_ 2631794430 AntitheftCmdStates 1201;
BA_ "SPN" SG_ 2631794430 AntitheftPasswordRepresentation 1202;
BA_ "SigType" SG_ 2631794430 AntitheftPasswordRepresentation 1;
BA_ "SPN" SG_ 2297441790 SpprtVrblTrnsRpttnRtFrAcclrtnSns 5353;
BA_ "SigType" SG_ 2297441790 SpprtVrblTrnsRpttnRtFrAcclrtnSns 4;
BA_ "SystemSignalLongSymbol" SG_ 2297441790 SpprtVrblTrnsRpttnRtFrAcclrtnSns "SpprtVrblTrnsRpttnRtFrAcclrtnSnsr";
BA_ "SPN" SG_ 2297441790 VrtclAcclrtnExRngeFigureOfMerit 5352;
BA_ "SigType" SG_ 2297441790 VrtclAcclrtnExRngeFigureOfMerit 4;
BA_ "SPN" SG_ 2297441790 LngtdnlAcclrtnExRngFgureOfMerit 5351;
BA_ "SigType" SG_ 2297441790 LngtdnlAcclrtnExRngFgureOfMerit 4;
BA_ "SPN" SG_ 2297441790 LtrlAcclrtnExRangeFigureOfMerit 5350;
BA_ "SigType" SG_ 2297441790 LtrlAcclrtnExRangeFigureOfMerit 4;
BA_ "SPN" SG_ 2297441790 VerticalAccelerationExRange 5349;
BA_ "SigType" SG_ 2297441790 VerticalAccelerationExRange 1;
BA_ "SPN" SG_ 2297441790 LateralAccelerationExRange 5347;
BA_ "SigType" SG_ 2297441790 LateralAccelerationExRange 1;
BA_ "SPN" SG_ 2297441790 LongitudinalAccelerationExRange 5348;
BA_ "SigType" SG_ 2297441790 LongitudinalAccelerationExRange 1;
BA_ "SPN" SG_ 2566712062 HybrdBatteryPackRemainingCharge 5464;
BA_ "SigType" SG_ 2566712062 HybrdBatteryPackRemainingCharge 1;
BA_ "SPN" SG_ 2364549630 RllAndPtchExRngMsurementLatency 4982;
BA_ "SigType" SG_ 2364549630 RllAndPtchExRngMsurementLatency 1;
BA_ "SPN" SG_ 2364549630 RollAngleExRangeFigureOfMerit 4981;
BA_ "SigType" SG_ 2364549630 RollAngleExRangeFigureOfMerit 4;
BA_ "SPN" SG_ 2364549630 RollAngleExRangeCompensation 4980;
BA_ "SigType" SG_ 2364549630 RollAngleExRangeCompensation 4;
BA_ "SPN" SG_ 2364549630 PitchAngleExRangeFigureOfMerit 4979;
BA_ "SigType" SG_ 2364549630 PitchAngleExRangeFigureOfMerit 4;
BA_ "SPN" SG_ 2364549630 PitchAngleExRangeCompensation 4978;
BA_ "SigType" SG_ 2364549630 PitchAngleExRangeCompensation 4;
BA_ "SPN" SG_ 2364549630 RollAngleExRange 4977;
BA_ "SigType" SG_ 2364549630 RollAngleExRange 1;
BA_ "SPN" SG_ 2364549630 PitchAngleExRange 4976;
BA_ "SigType" SG_ 2364549630 PitchAngleExRange 1;
BA_ "SPN" SG_ 2499614462 OccpntClssfcationSystem10Status 4972;
BA_ "SigType" SG_ 2499614462 OccpntClssfcationSystem10Status 4;
BA_ "SPN" SG_ 2499614462 OccpntClssficationSystem9Status 4971;
BA_ "SigType" SG_ 2499614462 OccpntClssficationSystem9Status 4;
BA_ "SPN" SG_ 2499614462 OccpntClssficationSystem8Status 4970;
BA_ "SigType" SG_ 2499614462 OccpntClssficationSystem8Status 4;
BA_ "SPN" SG_ 2499614462 OccpntClssficationSystem7Status 4969;
BA_ "SigType" SG_ 2499614462 OccpntClssficationSystem7Status 4;
BA_ "SPN" SG_ 2499614462 OccpntClssficationSystem6Status 4968;
BA_ "SigType" SG_ 2499614462 OccpntClssficationSystem6Status 4;
BA_ "SPN" SG_ 2499614462 OccpntClssficationSystem5Status 4967;
BA_ "SigType" SG_ 2499614462 OccpntClssficationSystem5Status 4;
BA_ "SPN" SG_ 2499614462 OccpntClssficationSystem4Status 4966;
BA_ "SigType" SG_ 2499614462 OccpntClssficationSystem4Status 4;
BA_ "SPN" SG_ 2499614462 OccpntClssficationSystem3Status 4965;
BA_ "SigType" SG_ 2499614462 OccpntClssficationSystem3Status 4;
BA_ "SPN" SG_ 2499614462 PssngrOccpntClssfctnSystmStatus 4964;
BA_ "SigType" SG_ 2499614462 PssngrOccpntClssfctnSystmStatus 4;
BA_ "SPN" SG_ 2499614462 DrvrOccpntClssfctonSystemStatus 4963;
BA_ "SigType" SG_ 2499614462 DrvrOccpntClssfctonSystemStatus 4;
BA_ "SPN" SG_ 2560098046 CabNoiseCtrlTuningStatus 5060;
BA_ "SigType" SG_ 2560098046 CabNoiseCtrlTuningStatus 4;
BA_ "SPN" SG_ 2560098046 CabNoiseCtrlStatus 5059;
BA_ "SigType" SG_ 2560098046 CabNoiseCtrlStatus 4;
BA_ "SPN" SG_ 2560163582 CabNoiseCtrlTuningState 5058;
BA_ "SigType" SG_ 2560163582 CabNoiseCtrlTuningState 4;
BA_ "SPN" SG_ 2560163582 CabNoiseCtrlState 5057;
BA_ "SigType" SG_ 2560163582 CabNoiseCtrlState 4;
BA_ "SPN" SG_ 2297441534 DropRelayCtrl 5403;
BA_ "SigType" SG_ 2297441534 DropRelayCtrl 4;
BA_ "SPN" SG_ 2297441534 LiftRelayCtrl 5402;
BA_ "SigType" SG_ 2297441534 LiftRelayCtrl 4;
BA_ "SPN" SG_ 2297441534 MaterialDropActiveStatus 5014;
BA_ "SigType" SG_ 2297441534 MaterialDropActiveStatus 4;
BA_ "SPN" SG_ 2297441534 MaterialLiftActiveStatus 5013;
BA_ "SigType" SG_ 2297441534 MaterialLiftActiveStatus 4;
BA_ "SPN" SG_ 2297441534 GnratorCurrentBoostActiveStatus 5012;
BA_ "SigType" SG_ 2297441534 GnratorCurrentBoostActiveStatus 4;
BA_ "SPN" SG_ 2297441534 MaterialDropSwitch 5011;
BA_ "SigType" SG_ 2297441534 MaterialDropSwitch 4;
BA_ "SPN" SG_ 2297441534 MaterialLiftSwitch 5010;
BA_ "SigType" SG_ 2297441534 MaterialLiftSwitch 4;
BA_ "SPN" SG_ 2297441534 MagnetReverseCurrent 5009;
BA_ "SigType" SG_ 2297441534 MagnetReverseCurrent 1;
BA_ "SPN" SG_ 2297441534 MagnetForwardCurrent 5008;
BA_ "SigType" SG_ 2297441534 MagnetForwardCurrent 1;
BA_ "SPN" SG_ 2566722302 GneratorDutyCycleExceededStatus 5007;
BA_ "SigType" SG_ 2566722302 GneratorDutyCycleExceededStatus 4;
BA_ "SPN" SG_ 2566722302 VoltageMonitorActiveStatus 5006;
BA_ "SigType" SG_ 2566722302 VoltageMonitorActiveStatus 4;
BA_ "SPN" SG_ 2566722302 GensetEnableActiveStatus 5005;
BA_ "SigType" SG_ 2566722302 GensetEnableActiveStatus 4;
BA_ "SPN" SG_ 2566722302 ReverseCurrentRangeSetting 5002;
BA_ "SigType" SG_ 2566722302 ReverseCurrentRangeSetting 4;
BA_ "SPN" SG_ 2566722302 GensetSoftstartActiveStatus 5004;
BA_ "SigType" SG_ 2566722302 GensetSoftstartActiveStatus 4;
BA_ "SPN" SG_ 2566722302 Grapple_MagnetSelectionSwitch 5003;
BA_ "SigType" SG_ 2566722302 Grapple_MagnetSelectionSwitch 4;
BA_ "SPN" SG_ 2566722302 GnstSystmOtptVoltageRangeStatus 5001;
BA_ "SigType" SG_ 2566722302 GnstSystmOtptVoltageRangeStatus 4;
BA_ "SPN" SG_ 2566722302 GeneratorOverheatStatus 5000;
BA_ "SigType" SG_ 2566722302 GeneratorOverheatStatus 4;
BA_ "SPN" SG_ 2566722558 MagnetRatedPower 4999;
BA_ "SigType" SG_ 2566722558 MagnetRatedPower 1;
BA_ "SPN" SG_ 2566722558 MagnetBoostTime 4998;
BA_ "SigType" SG_ 2566722558 MagnetBoostTime 1;
BA_ "SPN" SG_ 2560032510 LwVltgDscnnctDsredOperatingMode 5149;
BA_ "SigType" SG_ 2560032510 LwVltgDscnnctDsredOperatingMode 4;
BA_ "SPN" SG_ 2566717950 LowVoltageDisconnectTemp 5148;
BA_ "SigType" SG_ 2566717950 LowVoltageDisconnectTemp 1;
BA_ "SPN" SG_ 2566717950 LwVltgDisconnectVoutOutputState 5147;
BA_ "SigType" SG_ 2566717950 LwVltgDisconnectVoutOutputState 4;
BA_ "SPN" SG_ 2566717950 LwVoltageDisconnectOutput1State 5146;
BA_ "SigType" SG_ 2566717950 LwVoltageDisconnectOutput1State 4;
BA_ "SPN" SG_ 2566717950 LwVoltageDisconnectOutput2State 5145;
BA_ "SigType" SG_ 2566717950 LwVoltageDisconnectOutput2State 4;
BA_ "SPN" SG_ 2566717950 LwVoltageDisconnectOutput3State 5144;
BA_ "SigType" SG_ 2566717950 LwVoltageDisconnectOutput3State 4;
BA_ "SPN" SG_ 2566717950 LwVltgDscnnctCrrntOperatingMode 5143;
BA_ "SigType" SG_ 2566717950 LwVltgDscnnctCrrntOperatingMode 4;
BA_ "SPN" SG_ 2566717950 LwVltgDscnnctManualConnectState 5142;
BA_ "SigType" SG_ 2566717950 LwVltgDscnnctManualConnectState 4;
BA_ "SPN" SG_ 2566717950 LwVltgDscnnctMnlDisconnectState 5141;
BA_ "SigType" SG_ 2566717950 LwVltgDscnnctMnlDisconnectState 4;
BA_ "SPN" SG_ 2499604222 BldRferenceElevationOffsetRight 5413;
BA_ "SigType" SG_ 2499604222 BldRferenceElevationOffsetRight 1;
BA_ "SPN" SG_ 2499604222 BldReferenceElevationOffsetLeft 5412;
BA_ "SigType" SG_ 2499604222 BldReferenceElevationOffsetLeft 1;
BA_ "SPN" SG_ 2499604222 BladeElevationDeviationRight 5411;
BA_ "SigType" SG_ 2499604222 BladeElevationDeviationRight 1;
BA_ "SPN" SG_ 2499604222 BladeElevationDeviationLeft 5410;
BA_ "SigType" SG_ 2499604222 BladeElevationDeviationLeft 1;
BA_ "SPN" SG_ 2358902526 Joystick3Lamp10Cmd 4489;
BA_ "SigType" SG_ 2358902526 Joystick3Lamp10Cmd 4;
BA_ "SPN" SG_ 2358902526 Joystick3Lamp9Cmd 4488;
BA_ "SigType" SG_ 2358902526 Joystick3Lamp9Cmd 4;
BA_ "SPN" SG_ 2358902526 Joystick3Lamp8Cmd 4487;
BA_ "SigType" SG_ 2358902526 Joystick3Lamp8Cmd 4;
BA_ "SPN" SG_ 2358902526 Joystick3Lamp7Cmd 4486;
BA_ "SigType" SG_ 2358902526 Joystick3Lamp7Cmd 4;
BA_ "SPN" SG_ 2358902526 Joystick3Lamp6Cmd 4485;
BA_ "SigType" SG_ 2358902526 Joystick3Lamp6Cmd 4;
BA_ "SPN" SG_ 2358902526 Joystick3Lamp5Cmd 4484;
BA_ "SigType" SG_ 2358902526 Joystick3Lamp5Cmd 4;
BA_ "SPN" SG_ 2358902526 Joystick3Lamp4Cmd 4483;
BA_ "SigType" SG_ 2358902526 Joystick3Lamp4Cmd 4;
BA_ "SPN" SG_ 2358902526 Joystick3Lamp3Cmd 4482;
BA_ "SigType" SG_ 2358902526 Joystick3Lamp3Cmd 4;
BA_ "SPN" SG_ 2358902526 Joystick3Lamp2Cmd 4481;
BA_ "SigType" SG_ 2358902526 Joystick3Lamp2Cmd 4;
BA_ "SPN" SG_ 2358902526 Joystick3Lamp1Cmd 4480;
BA_ "SigType" SG_ 2358902526 Joystick3Lamp1Cmd 4;
BA_ "SPN" SG_ 2358902526 Joystick2Lamp10Cmd 4479;
BA_ "SigType" SG_ 2358902526 Joystick2Lamp10Cmd 4;
BA_ "SPN" SG_ 2358902526 Joystick2Lamp9Cmd 4478;
BA_ "SigType" SG_ 2358902526 Joystick2Lamp9Cmd 4;
BA_ "SPN" SG_ 2358902526 Joystick2Lamp8Cmd 4477;
BA_ "SigType" SG_ 2358902526 Joystick2Lamp8Cmd 4;
BA_ "SPN" SG_ 2358902526 Joystick2Lamp7Cmd 4476;
BA_ "SigType" SG_ 2358902526 Joystick2Lamp7Cmd 4;
BA_ "SPN" SG_ 2358902526 Joystick2Lamp6Cmd 4475;
BA_ "SigType" SG_ 2358902526 Joystick2Lamp6Cmd 4;
BA_ "SPN" SG_ 2358902526 Joystick2Lamp5Cmd 4474;
BA_ "SigType" SG_ 2358902526 Joystick2Lamp5Cmd 4;
BA_ "SPN" SG_ 2358902526 Joystick2Lamp4Cmd 4473;
BA_ "SigType" SG_ 2358902526 Joystick2Lamp4Cmd 4;
BA_ "SPN" SG_ 2358902526 Joystick2Lamp3Cmd 4472;
BA_ "SigType" SG_ 2358902526 Joystick2Lamp3Cmd 4;
BA_ "SPN" SG_ 2358902526 Joystick2Lamp2Cmd 4471;
BA_ "SigType" SG_ 2358902526 Joystick2Lamp2Cmd 4;
BA_ "SPN" SG_ 2358902526 Joystick2Lamp1Cmd 4470;
BA_ "SigType" SG_ 2358902526 Joystick2Lamp1Cmd 4;
BA_ "SPN" SG_ 2358902526 Joystick1Lamp10Cmd 4469;
BA_ "SigType" SG_ 2358902526 Joystick1Lamp10Cmd 4;
BA_ "SPN" SG_ 2358902526 Joystick1Lamp9Cmd 4468;
BA_ "SigType" SG_ 2358902526 Joystick1Lamp9Cmd 4;
BA_ "SPN" SG_ 2358902526 Joystick1Lamp8Cmd 4467;
BA_ "SigType" SG_ 2358902526 Joystick1Lamp8Cmd 4;
BA_ "SPN" SG_ 2358902526 Joystick1Lamp7Cmd 4466;
BA_ "SigType" SG_ 2358902526 Joystick1Lamp7Cmd 4;
BA_ "SPN" SG_ 2358902526 Joystick1Lamp6Cmd 4465;
BA_ "SigType" SG_ 2358902526 Joystick1Lamp6Cmd 4;
BA_ "SPN" SG_ 2358902526 Joystick1Lamp5Cmd 4464;
BA_ "SigType" SG_ 2358902526 Joystick1Lamp5Cmd 4;
BA_ "SPN" SG_ 2358902526 Joystick1Lamp4Cmd 4463;
BA_ "SigType" SG_ 2358902526 Joystick1Lamp4Cmd 4;
BA_ "SPN" SG_ 2358902526 Joystick1Lamp3Cmd 4462;
BA_ "SigType" SG_ 2358902526 Joystick1Lamp3Cmd 4;
BA_ "SPN" SG_ 2358902526 Joystick1Lamp2Cmd 4461;
BA_ "SigType" SG_ 2358902526 Joystick1Lamp2Cmd 4;
BA_ "SPN" SG_ 2358902526 Joystick1Lamp1Cmd 4460;
BA_ "SigType" SG_ 2358902526 Joystick1Lamp1Cmd 4;
BA_ "SPN" SG_ 2566711550 IntkVlvActtnSystmOlPrss2SlndCtrl 5500;
BA_ "SigType" SG_ 2566711550 IntkVlvActtnSystmOlPrss2SlndCtrl 4;
BA_ "SPN" SG_ 2566711550 IntkVlvActtnSystmOlPrss1SlndCtrl 5499;
BA_ "SigType" SG_ 2566711550 IntkVlvActtnSystmOlPrss1SlndCtrl 4;
BA_ "SPN" SG_ 2633832958 SpecialIgnitorLoop90Resistance 4917;
BA_ "SigType" SG_ 2633832958 SpecialIgnitorLoop90Resistance 1;
BA_ "SPN" SG_ 2633832958 SpecialIgnitorLoop89Resistance 4916;
BA_ "SigType" SG_ 2633832958 SpecialIgnitorLoop89Resistance 1;
BA_ "SPN" SG_ 2633832958 SpecialIgnitorLoop88Resistance 4915;
BA_ "SigType" SG_ 2633832958 SpecialIgnitorLoop88Resistance 1;
BA_ "SPN" SG_ 2633832958 SpecialIgnitorLoop87Resistance 4914;
BA_ "SigType" SG_ 2633832958 SpecialIgnitorLoop87Resistance 1;
BA_ "SPN" SG_ 2633832958 SpecialIgnitorLoop86Resistance 4913;
BA_ "SigType" SG_ 2633832958 SpecialIgnitorLoop86Resistance 1;
BA_ "SPN" SG_ 2633832958 SpecialIgnitorLoop85Resistance 4912;
BA_ "SigType" SG_ 2633832958 SpecialIgnitorLoop85Resistance 1;
BA_ "SPN" SG_ 2633832958 SpecialIgnitorLoop84Resistance 4911;
BA_ "SigType" SG_ 2633832958 SpecialIgnitorLoop84Resistance 1;
BA_ "SPN" SG_ 2633832958 SpecialIgnitorLoop83Resistance 4910;
BA_ "SigType" SG_ 2633832958 SpecialIgnitorLoop83Resistance 1;
BA_ "SPN" SG_ 2633832958 SpecialIgnitorLoop82Resistance 4909;
BA_ "SigType" SG_ 2633832958 SpecialIgnitorLoop82Resistance 1;
BA_ "SPN" SG_ 2633832958 SpecialIgnitorLoop81Resistance 4908;
BA_ "SigType" SG_ 2633832958 SpecialIgnitorLoop81Resistance 1;
BA_ "SPN" SG_ 2633832958 SpecialIgnitorLoop80Resistance 4907;
BA_ "SigType" SG_ 2633832958 SpecialIgnitorLoop80Resistance 1;
BA_ "SPN" SG_ 2633832958 SpecialIgnitorLoop79Resistance 4906;
BA_ "SigType" SG_ 2633832958 SpecialIgnitorLoop79Resistance 1;
BA_ "SPN" SG_ 2633832958 SpecialIgnitorLoop78Resistance 4905;
BA_ "SigType" SG_ 2633832958 SpecialIgnitorLoop78Resistance 1;
BA_ "SPN" SG_ 2633832958 SpecialIgnitorLoop77Resistance 4904;
BA_ "SigType" SG_ 2633832958 SpecialIgnitorLoop77Resistance 1;
BA_ "SPN" SG_ 2633832958 SpecialIgnitorLoop76Resistance 4903;
BA_ "SigType" SG_ 2633832958 SpecialIgnitorLoop76Resistance 1;
BA_ "SPN" SG_ 2633832958 SpecialIgnitorLoop75Resistance 4902;
BA_ "SigType" SG_ 2633832958 SpecialIgnitorLoop75Resistance 1;
BA_ "SPN" SG_ 2633832958 SpecialIgnitorLoop74Resistance 4901;
BA_ "SigType" SG_ 2633832958 SpecialIgnitorLoop74Resistance 1;
BA_ "SPN" SG_ 2633832958 SpecialIgnitorLoop73Resistance 4900;
BA_ "SigType" SG_ 2633832958 SpecialIgnitorLoop73Resistance 1;
BA_ "SPN" SG_ 2633832958 SpecialIgnitorLoop72Resistance 4899;
BA_ "SigType" SG_ 2633832958 SpecialIgnitorLoop72Resistance 1;
BA_ "SPN" SG_ 2633832958 SpecialIgnitorLoop71Resistance 4898;
BA_ "SigType" SG_ 2633832958 SpecialIgnitorLoop71Resistance 1;
BA_ "SPN" SG_ 2633832958 SpecialIgnitorLoop70Resistance 4897;
BA_ "SigType" SG_ 2633832958 SpecialIgnitorLoop70Resistance 1;
BA_ "SPN" SG_ 2633832958 SpecialIgnitorLoop69Resistance 4896;
BA_ "SigType" SG_ 2633832958 SpecialIgnitorLoop69Resistance 1;
BA_ "SPN" SG_ 2633832958 SpecialIgnitorLoop68Resistance 4895;
BA_ "SigType" SG_ 2633832958 SpecialIgnitorLoop68Resistance 1;
BA_ "SPN" SG_ 2633832958 SpecialIgnitorLoop67Resistance 4894;
BA_ "SigType" SG_ 2633832958 SpecialIgnitorLoop67Resistance 1;
BA_ "SPN" SG_ 2633832958 SpecialIgnitorLoop66Resistance 4893;
BA_ "SigType" SG_ 2633832958 SpecialIgnitorLoop66Resistance 1;
BA_ "SPN" SG_ 2633832958 SpecialIgnitorLoop65Resistance 4892;
BA_ "SigType" SG_ 2633832958 SpecialIgnitorLoop65Resistance 1;
BA_ "SPN" SG_ 2633832958 SpecialIgnitorLoop64Resistance 4891;
BA_ "SigType" SG_ 2633832958 SpecialIgnitorLoop64Resistance 1;
BA_ "SPN" SG_ 2633832958 SpecialIgnitorLoop63Resistance 4890;
BA_ "SigType" SG_ 2633832958 SpecialIgnitorLoop63Resistance 1;
BA_ "SPN" SG_ 2633832958 SpecialIgnitorLoop61Resistance 4888;
BA_ "SigType" SG_ 2633832958 SpecialIgnitorLoop61Resistance 1;
BA_ "SPN" SG_ 2633832958 SpecialIgnitorLoop60Resistance 4887;
BA_ "SigType" SG_ 2633832958 SpecialIgnitorLoop60Resistance 1;
BA_ "SPN" SG_ 2633832958 SpecialIgnitorLoop59Resistance 4886;
BA_ "SigType" SG_ 2633832958 SpecialIgnitorLoop59Resistance 1;
BA_ "SPN" SG_ 2633832958 SpecialIgnitorLoop58Resistance 4885;
BA_ "SigType" SG_ 2633832958 SpecialIgnitorLoop58Resistance 1;
BA_ "SPN" SG_ 2633832958 SpecialIgnitorLoop57Resistance 4884;
BA_ "SigType" SG_ 2633832958 SpecialIgnitorLoop57Resistance 1;
BA_ "SPN" SG_ 2633832958 SpecialIgnitorLoop56Resistance 4883;
BA_ "SigType" SG_ 2633832958 SpecialIgnitorLoop56Resistance 1;
BA_ "SPN" SG_ 2633832958 SpecialIgnitorLoop55Resistance 4882;
BA_ "SigType" SG_ 2633832958 SpecialIgnitorLoop55Resistance 1;
BA_ "SPN" SG_ 2633832958 SpecialIgnitorLoop54Resistance 4881;
BA_ "SigType" SG_ 2633832958 SpecialIgnitorLoop54Resistance 1;
BA_ "SPN" SG_ 2633832958 SpecialIgnitorLoop53Resistance 4880;
BA_ "SigType" SG_ 2633832958 SpecialIgnitorLoop53Resistance 1;
BA_ "SPN" SG_ 2633832958 SpecialIgnitorLoop52Resistance 4879;
BA_ "SigType" SG_ 2633832958 SpecialIgnitorLoop52Resistance 1;
BA_ "SPN" SG_ 2633832958 SpecialIgnitorLoop51Resistance 4878;
BA_ "SigType" SG_ 2633832958 SpecialIgnitorLoop51Resistance 1;
BA_ "SPN" SG_ 2633832958 SpecialIgnitorLoop50Resistance 4877;
BA_ "SigType" SG_ 2633832958 SpecialIgnitorLoop50Resistance 1;
BA_ "SPN" SG_ 2633832958 SpecialIgnitorLoop49Resistance 4876;
BA_ "SigType" SG_ 2633832958 SpecialIgnitorLoop49Resistance 1;
BA_ "SPN" SG_ 2633832958 SpecialIgnitorLoop48Resistance 4875;
BA_ "SigType" SG_ 2633832958 SpecialIgnitorLoop48Resistance 1;
BA_ "SPN" SG_ 2633832958 SpecialIgnitorLoop47Resistance 4874;
BA_ "SigType" SG_ 2633832958 SpecialIgnitorLoop47Resistance 1;
BA_ "SPN" SG_ 2633832958 SpecialIgnitorLoop46Resistance 4873;
BA_ "SigType" SG_ 2633832958 SpecialIgnitorLoop46Resistance 1;
BA_ "SPN" SG_ 2633832958 SpecialIgnitorLoop45Resistance 4872;
BA_ "SigType" SG_ 2633832958 SpecialIgnitorLoop45Resistance 1;
BA_ "SPN" SG_ 2633832958 SpecialIgnitorLoop44Resistance 4871;
BA_ "SigType" SG_ 2633832958 SpecialIgnitorLoop44Resistance 1;
BA_ "SPN" SG_ 2633832958 SpecialIgnitorLoop43Resistance 4870;
BA_ "SigType" SG_ 2633832958 SpecialIgnitorLoop43Resistance 1;
BA_ "SPN" SG_ 2633832958 SpecialIgnitorLoop42Resistance 4869;
BA_ "SigType" SG_ 2633832958 SpecialIgnitorLoop42Resistance 1;
BA_ "SPN" SG_ 2633832958 SpecialIgnitorLoop41Resistance 4868;
BA_ "SigType" SG_ 2633832958 SpecialIgnitorLoop41Resistance 1;
BA_ "SPN" SG_ 2633832958 SpecialIgnitorLoop40Resistance 4867;
BA_ "SigType" SG_ 2633832958 SpecialIgnitorLoop40Resistance 1;
BA_ "SPN" SG_ 2633832958 SpecialIgnitorLoop39Resistance 4866;
BA_ "SigType" SG_ 2633832958 SpecialIgnitorLoop39Resistance 1;
BA_ "SPN" SG_ 2633832958 SpecialIgnitorLoop38Resistance 4865;
BA_ "SigType" SG_ 2633832958 SpecialIgnitorLoop38Resistance 1;
BA_ "SPN" SG_ 2633832958 SpecialIgnitorLoop37Resistance 4864;
BA_ "SigType" SG_ 2633832958 SpecialIgnitorLoop37Resistance 1;
BA_ "SPN" SG_ 2633832958 SpecialIgnitorLoop36Resistance 4863;
BA_ "SigType" SG_ 2633832958 SpecialIgnitorLoop36Resistance 1;
BA_ "SPN" SG_ 2633832958 SpecialIgnitorLoop35Resistance 4862;
BA_ "SigType" SG_ 2633832958 SpecialIgnitorLoop35Resistance 1;
BA_ "SPN" SG_ 2633832958 SpecialIgnitorLoop34Resistance 4861;
BA_ "SigType" SG_ 2633832958 SpecialIgnitorLoop34Resistance 1;
BA_ "SPN" SG_ 2633832958 SpecialIgnitorLoop33Resistance 4860;
BA_ "SigType" SG_ 2633832958 SpecialIgnitorLoop33Resistance 1;
BA_ "SPN" SG_ 2633832958 SpecialIgnitorLoop32Resistance 4859;
BA_ "SigType" SG_ 2633832958 SpecialIgnitorLoop32Resistance 1;
BA_ "SPN" SG_ 2633832958 SpecialIgnitorLoop31Resistance 4858;
BA_ "SigType" SG_ 2633832958 SpecialIgnitorLoop31Resistance 1;
BA_ "SPN" SG_ 2633832958 SpecialIgnitorLoop30Resistance 4857;
BA_ "SigType" SG_ 2633832958 SpecialIgnitorLoop30Resistance 1;
BA_ "SPN" SG_ 2633832958 SpecialIgnitorLoop29Resistance 4856;
BA_ "SigType" SG_ 2633832958 SpecialIgnitorLoop29Resistance 1;
BA_ "SPN" SG_ 2633832958 SpecialIgnitorLoop28Resistance 4855;
BA_ "SigType" SG_ 2633832958 SpecialIgnitorLoop28Resistance 1;
BA_ "SPN" SG_ 2633832958 SpecialIgnitorLoop27Resistance 4854;
BA_ "SigType" SG_ 2633832958 SpecialIgnitorLoop27Resistance 1;
BA_ "SPN" SG_ 2633832958 SpecialIgnitorLoop26Resistance 4853;
BA_ "SigType" SG_ 2633832958 SpecialIgnitorLoop26Resistance 1;
BA_ "SPN" SG_ 2633832958 SpecialIgnitorLoop25Resistance 4852;
BA_ "SigType" SG_ 2633832958 SpecialIgnitorLoop25Resistance 1;
BA_ "SPN" SG_ 2633832958 SpecialIgnitorLoop24Resistance 4851;
BA_ "SigType" SG_ 2633832958 SpecialIgnitorLoop24Resistance 1;
BA_ "SPN" SG_ 2633832958 SpecialIgnitorLoop23Resistance 4850;
BA_ "SigType" SG_ 2633832958 SpecialIgnitorLoop23Resistance 1;
BA_ "SPN" SG_ 2633832958 SpecialIgnitorLoop22Resistance 4849;
BA_ "SigType" SG_ 2633832958 SpecialIgnitorLoop22Resistance 1;
BA_ "SPN" SG_ 2633832958 SpecialIgnitorLoop21Resistance 4848;
BA_ "SigType" SG_ 2633832958 SpecialIgnitorLoop21Resistance 1;
BA_ "SPN" SG_ 2633832958 SpecialIgnitorLoop20Resistance 4847;
BA_ "SigType" SG_ 2633832958 SpecialIgnitorLoop20Resistance 1;
BA_ "SPN" SG_ 2633832958 SpecialIgnitorLoop19Resistance 4846;
BA_ "SigType" SG_ 2633832958 SpecialIgnitorLoop19Resistance 1;
BA_ "SPN" SG_ 2633832958 SpecialIgnitorLoop18Resistance 4845;
BA_ "SigType" SG_ 2633832958 SpecialIgnitorLoop18Resistance 1;
BA_ "SPN" SG_ 2633832958 SpecialIgnitorLoop17Resistance 4844;
BA_ "SigType" SG_ 2633832958 SpecialIgnitorLoop17Resistance 1;
BA_ "SPN" SG_ 2633832958 SpecialIgnitorLoop16Resistance 4843;
BA_ "SigType" SG_ 2633832958 SpecialIgnitorLoop16Resistance 1;
BA_ "SPN" SG_ 2633832958 SpecialIgnitorLoop15Resistance 4842;
BA_ "SigType" SG_ 2633832958 SpecialIgnitorLoop15Resistance 1;
BA_ "SPN" SG_ 2633832958 SpecialIgnitorLoop14Resistance 4841;
BA_ "SigType" SG_ 2633832958 SpecialIgnitorLoop14Resistance 1;
BA_ "SPN" SG_ 2633832958 SpecialIgnitorLoop13Resistance 4840;
BA_ "SigType" SG_ 2633832958 SpecialIgnitorLoop13Resistance 1;
BA_ "SPN" SG_ 2633832958 SpecialIgnitorLoop12Resistance 4839;
BA_ "SigType" SG_ 2633832958 SpecialIgnitorLoop12Resistance 1;
BA_ "SPN" SG_ 2633832958 SpecialIgnitorLoop11Resistance 4838;
BA_ "SigType" SG_ 2633832958 SpecialIgnitorLoop11Resistance 1;
BA_ "SPN" SG_ 2633832958 SpecialIgnitorLoop10Resistance 4837;
BA_ "SigType" SG_ 2633832958 SpecialIgnitorLoop10Resistance 1;
BA_ "SPN" SG_ 2633832958 SpecialIgnitorLoop9Resistance 4836;
BA_ "SigType" SG_ 2633832958 SpecialIgnitorLoop9Resistance 1;
BA_ "SPN" SG_ 2633832958 SpecialIgnitorLoop8Resistance 4835;
BA_ "SigType" SG_ 2633832958 SpecialIgnitorLoop8Resistance 1;
BA_ "SPN" SG_ 2633832958 SpecialIgnitorLoop7Resistance 4834;
BA_ "SigType" SG_ 2633832958 SpecialIgnitorLoop7Resistance 1;
BA_ "SPN" SG_ 2633832958 SpecialIgnitorLoop6Resistance 4833;
BA_ "SigType" SG_ 2633832958 SpecialIgnitorLoop6Resistance 1;
BA_ "SPN" SG_ 2633832958 SpecialIgnitorLoop5Resistance 4832;
BA_ "SigType" SG_ 2633832958 SpecialIgnitorLoop5Resistance 1;
BA_ "SPN" SG_ 2633832958 SpecialIgnitorLoop4Resistance 4831;
BA_ "SigType" SG_ 2633832958 SpecialIgnitorLoop4Resistance 1;
BA_ "SPN" SG_ 2633832958 SpecialIgnitorLoop3Resistance 4830;
BA_ "SigType" SG_ 2633832958 SpecialIgnitorLoop3Resistance 1;
BA_ "SPN" SG_ 2633832958 SpecialIgnitorLoop2Resistance 4829;
BA_ "SigType" SG_ 2633832958 SpecialIgnitorLoop2Resistance 1;
BA_ "SPN" SG_ 2633832958 SpecialIgnitorLoop1Resistance 4828;
BA_ "SigType" SG_ 2633832958 SpecialIgnitorLoop1Resistance 1;
BA_ "SPN" SG_ 2633832958 SdBgIgnitorLoop2RightResistance 4827;
BA_ "SigType" SG_ 2633832958 SdBgIgnitorLoop2RightResistance 1;
BA_ "SPN" SG_ 2633832958 SdBgIgnitorLoop1RightResistance 4826;
BA_ "SigType" SG_ 2633832958 SdBgIgnitorLoop1RightResistance 1;
BA_ "SPN" SG_ 2633832958 SdBagIgnitorLoop2LeftResistance 4825;
BA_ "SigType" SG_ 2633832958 SdBagIgnitorLoop2LeftResistance 1;
BA_ "SPN" SG_ 2633832958 SdBagIgnitorLoop1LeftResistance 4824;
BA_ "SigType" SG_ 2633832958 SdBagIgnitorLoop1LeftResistance 1;
BA_ "SPN" SG_ 2633832958 PssngrBltTnsnrIgntrLpResistance 4823;
BA_ "SigType" SG_ 2633832958 PssngrBltTnsnrIgntrLpResistance 1;
BA_ "SPN" SG_ 2633832958 DrvrBltTnsnrIgntrLoopResistance 4822;
BA_ "SigType" SG_ 2633832958 DrvrBltTnsnrIgntrLoopResistance 1;
BA_ "SPN" SG_ 2633832958 PssngrArbgIgntrLp2ndStgRsstance 4821;
BA_ "SigType" SG_ 2633832958 PssngrArbgIgntrLp2ndStgRsstance 1;
BA_ "SPN" SG_ 2633832958 DrvrArbgIgntrLp2ndStgResistance 4820;
BA_ "SigType" SG_ 2633832958 DrvrArbgIgntrLp2ndStgResistance 1;
BA_ "SPN" SG_ 2633832958 PssngrArbgIgntrLp1stStgRsstance 4819;
BA_ "SigType" SG_ 2633832958 PssngrArbgIgntrLp1stStgRsstance 1;
BA_ "SPN" SG_ 2633832958 DrvrArbgIgntrLp1stStgResistance 4818;
BA_ "SigType" SG_ 2633832958 DrvrArbgIgntrLp1stStgResistance 1;
BA_ "SPN" SG_ 2566719998 HighResolutionEngTotalFuelUsed 5054;
BA_ "SigType" SG_ 2566719998 HighResolutionEngTotalFuelUsed 1;
BA_ "SPN" SG_ 2566719998 HighResolutionEngTripFuel 5053;
BA_ "SigType" SG_ 2566719998 HighResolutionEngTripFuel 1;
VAL_ 2566841377 ConcretePumpStartRequest 3 "NA Error" 2 "No Request" 1 "Engine Start" ;
VAL_ 2566841377 APUPressureSwitchStatus 3 "NotAvailable" 2 "Error" 1 "On" 0 "Off" ;
VAL_ 2566841377 AC_clutch_status 3 "Not Available" 2 "Error" 1 "A/C clutch is engaged" 0 "A/C clutch is not engaged" ;
VAL_ 2566841377 EngOverspeedTest 3 "NotAvailable" 2 "Reserved" 1 "EngOverspeedTestActive" 0 "EngOverspeedTestNotActive" ;
VAL_ 2566841377 EngAirShutoffCmdStatus 0 "ArShtffDsbldNtAttmptngTShtffEng" 3 "NotAvailable" 2 "Reserved" 1 "ArShtffEnbldAttmptngTShtffEngAr" ;
VAL_ 2566841377 EngAlarmOutputCmdStatus 3 "NotAvailable" 2 "Reserved" 1 "EngAlarmOutputCmdActive" 0 "EngAlarmOutputCmdNotActive" ;
VAL_ 2566841377 EngAlarmAcknowledge 3 "NotAvailable" 2 "Error" 1 "EngAlarmAcknowledgeActive" 0 "EngAlarmAcknowledgeNotActive" ;
VAL_ 2566841377 EngProtectionSystemConfig 3 "NotAvailable" 2 "Error" 1 "EnabledInCalib" 0 "DisabledInCalib" ;
VAL_ 2566841377 EngProtectionSystemTimerState 3 "NotAvailable" 2 "Error" 1 "Active" 0 "Inactive" ;
VAL_ 2566841377 EngPrtectionSystemTimerOverride 3 "NotAvailable" 2 "Error" 1 "Active" 0 "Inactive" ;
VAL_ 2566841377 EngPrtctnSystmApprchingShutdown 3 "NotAvailable" 2 "Error" 1 "Approaching" 0 "NotApproaching" ;
VAL_ 2566841377 EngWaitToStartLamp 3 "NotAvailable" 2 "Error" 1 "On" 0 "Off" ;
VAL_ 2566841377 RefrigerantHighPressSwitch 3 "NotAvailable" 2 "Error" 1 "PrssTHghCmprssrCltchMyBDsngaged" 0 "PressNormal" ;
VAL_ 2566841377 RefrigerantLowPressSwitch 3 "NotAvailable" 2 "Error" 1 "PrssTLwCmprssrCltchMyBDsengaged" 0 "PressNormal" ;
VAL_ 2566841377 A_CHighPressFanSwitch 3 "NotAvailable" 2 "Error" 1 "PressHighFanMayBeEngaged" 0 "PressNormal" ;
VAL_ 2566841377 EngIdleShutdownTimerFunction 3 "NotAvailable" 2 "Error" 1 "EnabledInCalib" 0 "DisabledInCalib" ;
VAL_ 2566841377 EngIdleShutdownTimerState 3 "NotAvailable" 2 "Error" 1 "Active" 0 "Inactive" ;
VAL_ 2566841377 EngIdleShutdownTimerOverride 3 "NotAvailable" 2 "Error" 1 "Active" 0 "Inactive" ;
VAL_ 2566841377 EngIdleShutdownDriverAlertMode 3 "NotAvailable" 2 "Error" 1 "Active" 0 "Inactive" ;
VAL_ 2566841377 PTOShutdownHasShutdownEng 3 "NotAvailable" 2 "Error" 1 "Yes" 0 "No" ;
VAL_ 2566841377 EngPrtctnSystmHasShutdownEngine 3 "NotAvailable" 2 "Error" 1 "Yes" 0 "No" ;
VAL_ 2566841377 EngIdlShutdownHasShutdownEngine 3 "NotAvailable" 2 "Error" 1 "Yes" 0 "No" ;
VAL_ 2566841377 EngAirShutoffStatus 3 "NotAvailable" 2 "Error" 1 "AirFlowRestricted" 0 "AirFlowAllowedToEng" ;
VAL_ 2349541921 AEBS2_DriverActivationDemand 3 "Dont't care / Take no action" 2 "Error" 1 "NoDeactivationofAEBS" 0 "DeactivationofAEBS" ;
VAL_ 2633936126 BrkLnngRmnngAxle4Left 255 "NotAvailable" 254 "Error" 252 "BrkPadWearSensorNOK" 251 "BrkPadWearSensorOK" ;
VAL_ 2633936126 BrkLnngRmningAxle4Right 255 "NotAvailable" 254 "Error" 252 "BrkPadWearSensorNOK" 251 "BrkPadWearSensorOK" ;
VAL_ 2633936126 BrkLnngRmnngAxle3Left 255 "NotAvailable" 254 "Error" 252 "BrkPadWearSensorNOK" 251 "BrkPadWearSensorOK" ;
VAL_ 2633936126 BrkLnngRmningAxle3Right 255 "NotAvailable" 254 "Error" 252 "BrkPadWearSensorNOK" 251 "BrkPadWearSensorOK" ;
VAL_ 2633936126 BrkLnngRmnngAxle2Left 255 "NotAvailable" 254 "Error" 252 "BrkPadWearSensorNOK" 251 "BrkPadWearSensorOK" ;
VAL_ 2633936126 BrkLnngRmningAxle2Right 255 "NotAvailable" 254 "Error" 252 "BrkPadWearSensorNOK" 251 "BrkPadWearSensorOK" ;
VAL_ 2633936126 BrkLnngRmnngAxle1Left 255 "NotAvailable" 254 "Error" 252 "BrkPadWearSensorNOK" 251 "BrkPadWearSensorOK" ;
VAL_ 2633936126 BrkLnngRmningAxle1Right 255 "NotAvailable" 254 "Error" 252 "BrkPadWearSensorNOK" 251 "BrkPadWearSensorOK" ;
VAL_ 2566843681 ASLDEnableSwitch 3 "Not available" 2 "Error" 1 "Actuated" 0 "Not actuated" ;
VAL_ 2566843681 SpeedLimitation 3 "Not available" 2 "Error" 1 "Enable Speed Limitation" 0 "Disable Speed Limitation" ;
VAL_ 2566843681 OverspeedWarning 3 "Not available" 2 "Error" 1 "Enable Overspeed Warning" 0 "Disable Overspeed Warning" ;
VAL_ 2566843681 External_Vehicle_Speed_Enable 3 "Not available" 2 "Error" 1 "Enable external speed limit" 0 "Disable external speed limit" ;
VAL_ 2566844705 AutoECall_Inhibit 3 "Not available" 2 "Error indicator" 1 "E-Call Inhibit Active" 0 "E-Call Inhibit Not Active" ;
VAL_ 2566844705 PCCScreenSelection 3 "Not Available" 2 "Error" 1 "Active" 0 "Deactive" ;
VAL_ 2566844705 CruiseCtrlEnableSwitch_BCM 3 "NotAvailable" 2 "Error" 1 "CruiseCtrlEnabled" 0 "CruiseCtrlDisabled" ;
VAL_ 2566844705 CruiseControlDisableCommand_BCM 3 "Dont Care" 2 "Reserved" 1 "Cruise Control Not Allowed" 0 "Cruise Control Allowed" ;
VAL_ 2566844705 ConcretePumpTransferCaseACK 3 "NotAvailable" 2 "Error" 1 "TCEngaged" 0 "TCNotEngaged" ;
VAL_ 2566844705 PTO_Application_Mode 7 "SIGError" 6 "MinError" 5 "MaxError" 4 "NotPlausible" 3 "Mode3" 2 "Mode2" 1 "Mode1" 0 "Mode0" ;
VAL_ 2566844705 ParkBrakeReleaseInhibitRq_CCVSB 3 "Unavailable" 2 "SAEReserved" 1 "ParkBrakeReleaseInhibitRqed" 0 "ParkBrakeReleaseInhibitNotRqed" ;
VAL_ 2566844705 PTOGovernorState_CCVS_BCM 31 "NotAvailable" 20 "11110NotDefined" 19 "PTOSetSpeedMemory2" 18 "PTOSetSpeedMemory1" 17 "PreprogrammedSetSpeed8" 16 "PreprogrammedSetSpeed7" 15 "PreprogrammedSetSpeed6" 14 "PreprogrammedSetSpeed5" 13 "PreprogrammedSetSpeed4" 12 "PreprogrammedSetSpeed3" 11 "PreprogrammedSetSpeed2" 10 "PreprogrammedSetSpeed1" 9 "AccelOverride" 8 "Accelerate" 7 "Resume" 6 "Decelerate_Coast" 5 "Set" 4 "RemoteStandby" 3 "Standby" 2 "RemoteHold" 1 "Hold" 0 "Off_Disabled" ;
VAL_ 2566844705 CruiseCtrlAccelerateSwitch_CCVSB 3 "NotAvailable" 2 "Error" 1 "CrsCtrlActivatorInPosAccelerate" 0 "CrsCtrlActvtrNotInPosAccelerate" ;
VAL_ 2566844705 CruiseCtrlResumeSwitch_CCVS_BCM 3 "NotAvailable" 2 "Error" 1 "CruiseCtrlActivatorInPosResume" 0 "CrseCtrlActivatorNotInPosResume" ;
VAL_ 2566844705 CruiseCtrlCoastSwitch_CCVS_BCM 3 "NotAvailable" 2 "Error" 1 "CruiseCtrlActivatorInPosCoast" 0 "CriseCtrlActivatorNotInPosCoast" ;
VAL_ 2566844705 CruiseCtrlOffSwitch 3 "NotAvailable" 2 "Error" 1 "Actuated" 0 "Not_Actuated" ;
VAL_ 2566844705 ClutchSwitch_CCVS_BCM 3 "NotAvailable" 2 "Error" 1 "ClutchPedalDepressed" 0 "ClutchPedalReleased" ;
VAL_ 2566844705 BrakeSwitch_CCVS_BCM 3 "NotAvailable" 2 "Error" 1 "BrakePedalDepressed" 0 "BrakePedalReleased" ;
VAL_ 2566844705 DamperActivation 3 "NotAvailable" 2 "Error" 1 "DamperActivationOn" 0 "DamperActivationOff" ;
VAL_ 2566844705 CruiseCtrlPauseSwitch_CCVS_BCM 3 "TakeNoAction" 2 "ErrorIndicator" 1 "On" 0 "Off" ;
VAL_ 2566844705 ParkingBrakeSwitch_CCVS_BCM 3 "NotAvailable" 2 "Error" 1 "ParkingBrakeSet" 0 "ParkingBrakeNotSet" ;
VAL_ 2566834967 MalfunctionIndicatorLampStatus 3 "Not available" 2 "Reserved" 1 "Lamp on" 0 "Lamp off" ;
VAL_ 2566834967 RedStopLampState 3 "Not available" 2 "Reserved" 1 "Lamp on" 0 "Lamp off" ;
VAL_ 2566834967 AmberWarningLampStatus 3 "Not available" 2 "Reserved" 1 "Lamp on" 0 "Lamp off" ;
VAL_ 2566834967 ProtectLampStatus 3 "Not available" 2 "Reserved" 1 "Lamp on" 0 "Lamp off" ;
VAL_ 2566834967 FlashRedStopLamp 3 "Unavailable / Do Not Flash" 2 "Reserved" 1 "Fast Flash" 0 "Slow Flash" ;
VAL_ 2566834967 FlashProtectLamp 3 "Unavailable / Do Not Flash" 2 "Reserved" 1 "Fast Flash" 0 "Slow Flash" ;
VAL_ 2566834967 FlashMalfuncIndicatorLamp 3 "Unavailable / Do Not Flash" 2 "Reserved" 1 "Fast Flash" 0 "Slow Flash" ;
VAL_ 2566834967 FlashAmberWarningLamp 3 "Unavailable / Do Not Flash" 2 "Reserved" 1 "Fast Flash" 0 "Slow Flash" ;
VAL_ 2566834711 FlashRedStopLamp 3 "Unavailable / Do Not Flash" 2 "Reserved" 1 "Fast Flash" 0 "Slow Flash" ;
VAL_ 2566834711 FlashProtectLamp 3 "Unavailable / Do Not Flash" 2 "Reserved" 1 "Fast Flash" 0 "Slow Flash" ;
VAL_ 2566834711 FlashMalfuncIndicatorLamp 3 "Unavailable / Do Not Flash" 2 "Reserved" 1 "Fast Flash" 0 "Slow Flash" ;
VAL_ 2566834711 FlashAmberWarningLamp 3 "Unavailable / Do Not Flash" 2 "Reserved" 1 "Fast Flash" 0 "Slow Flash" ;
VAL_ 2566834711 MalfunctionIndicatorLampStatus 3 "Not available" 2 "Reserved" 1 "Lamp on" 0 "Lamp off" ;
VAL_ 2566834711 AmberWarningLampStatus 3 "Not available" 2 "Reserved" 1 "Lamp on" 0 "Lamp off" ;
VAL_ 2566834711 RedStopLampState 3 "Not available" 2 "Reserved" 1 "Lamp on" 0 "Lamp off" ;
VAL_ 2566834711 ProtectLampStatus 3 "Not available" 2 "Reserved" 1 "Lamp on" 0 "Lamp off" ;
VAL_ 2161910270 AntitheftComponentStatusStates 3 "NotDefined" 2 "BlckdThsSttIndctsThtALckUnlckCm" 1 "LckdThsSttIndctsThtCmpnntCnNOTB" 0 "UnlckdThsSttIndctsThtCmpnntCnBS" ;
VAL_ 2161910270 AntthftEncryptnSdPrsntIndicator 3 "NotAvailable" 2 "Error" 1 "RandomNumberIsPresent" 0 "RandomNumberIsNotPresent" ;
VAL_ 2161910270 AntitheftModifyPwdStates 3 "Notvalid" 2 "EmptyOfPwdsThsSttIndctsThtCmpnn" 1 "FullofPwds" 0 "OkThsSttIndctsThtRqWsSccssfllyP" ;
VAL_ 2161910270 AntitheftPwdValidIndicator 3 "NotAvailable" 2 "Error" 1 "PwdIsAValidatedPassword" 0 "PwdIsNotAValidatedPassword" ;
VAL_ 2566835198 MalfunctionIndicatorLampStatus 3 "Not available" 2 "Reserved" 1 "Lamp on" 0 "Lamp off" ;
VAL_ 2566835198 RedStopLampState 3 "Not available" 2 "Reserved" 1 "Lamp on" 0 "Lamp off" ;
VAL_ 2566835198 AmberWarningLampStatus 3 "Not available" 2 "Reserved" 1 "Lamp on" 0 "Lamp off" ;
VAL_ 2566835198 ProtectLampStatus 3 "Not available" 2 "Reserved" 1 "Lamp on" 0 "Lamp off" ;
VAL_ 2566835198 FlashRedStopLamp 3 "Unavailable / Do Not Flash" 2 "Reserved" 1 "Fast Flash" 0 "Slow Flash" ;
VAL_ 2566835198 FlashProtectLamp 3 "Unavailable / Do Not Flash" 2 "Reserved" 1 "Fast Flash" 0 "Slow Flash" ;
VAL_ 2566835198 FlashMalfuncIndicatorLamp 3 "Unavailable / Do Not Flash" 2 "Reserved" 1 "Fast Flash" 0 "Slow Flash" ;
VAL_ 2566835198 FlashAmberWarningLamp 3 "Unavailable / Do Not Flash" 2 "Reserved" 1 "Fast Flash" 0 "Slow Flash" ;
VAL_ 2566881534 TBMTelltale 3 "Unknown" 2 "Flash" 1 "Off" 0 "On" ;
VAL_ 2566881534 ErrorIndication 63 "ErrorCode" 62 "ErrorCode" 61 "ErrorCode" 60 "ForbiddenValues" 59 "ErrorCode" 58 "ErrorCode" 57 "ErrorCode" 56 "ErrorCode" 55 "ErrorCode" 54 "ErrorCode" 53 "ErrorCode" 52 "ErrorCode" 51 "ErrorCode" 50 "ForbiddenValues" 49 "ErrorCode" 48 "ErrorCode" 47 "ErrorCode" 46 "ErrorCode" 45 "ErrorCode" 44 "ErrorCode" 43 "ErrorCode" 42 "ErrorCode" 41 "ErrorCode" 40 "ForbiddenValues" 39 "ErrorCode" 38 "ErrorCode" 37 "ErrorCode" 36 "ErrorCode" 35 "ErrorCode" 34 "ErrorCode" 33 "ErrorCode" 32 "ErrorCode" 31 "ErrorCode" 30 "ForbiddenValues" 29 "ErrorCode" 28 "ErrorCode" 27 "ErrorCode" 26 "ErrorCode" 25 "ErrorCode" 24 "ErrorCode" 23 "ErrorCode" 22 "ErrorCode" 21 "ErrorCode" 20 "ForbiddenValues" 19 "ErrorCode" 18 "ErrorCode" 17 "ErrorCode" 16 "ErrorCode" 15 "ErrorCode" 14 "ErrorCode" 13 "ErrorCode" 12 "ErrorCode" 11 "ErrorCode" 10 "ForbiddenValues" 9 "ForbiddenValues" 8 "ForbiddenValues" 7 "ForbiddenValues" 6 "ForbiddenValues" 5 "ForbiddenValues" 4 "ForbiddenValues" 3 "ForbiddenValues" 2 "ForbiddenValues" 1 "ForbiddenValues" 0 "ForbiddenValues" ;
VAL_ 2565873864 ROPsystemenabledDisabled 3 "NotAvailable" 2 "Error" 1 "Enabled" 0 "Disabled" ;
VAL_ 2565873864 YCSystemEnabledDisabled 3 "NotAvailable" 2 "Error" 1 "Enabled" 0 "Disabled" ;
VAL_ 2566882563 CheckPhase 3 "NotAvailable" 2 "Error" 1 "CheckPhaseActive" 0 "CheckPhaseNotActive" ;
VAL_ 2566882563 ReleaseAcceleratorPedalWarning2 3 "NotAvailable" 2 "Error" 1 "ReleaseAccPedal" 0 "Acc.PedalPosOk" ;
VAL_ 2566882563 PutLevertoNeutral 3 "NotAvailable" 2 "Error" 1 "PTO1Active" 0 "PTO1notActive" ;
VAL_ 2566882563 PTO2ActiveWarnings2 3 "NotAvailable" 2 "Error" 1 "PTO2Active" 0 "PTO2notactive" ;
VAL_ 2566882563 ClutchWear 1 "Active" 0 "NotActive" ;
VAL_ 2566882563 ClutchOverloadWarning1 3 "NotAvailable" 2 "Error" 1 "ClutchOverloaded" 0 "ClutchNotOverloaded" ;
VAL_ 2566882563 ASTronicLowairWarnings1 1 "Low air pressure" 0 "Not active" ;
VAL_ 2566882563 TemperatureTooHighWar1 3 "NotAvailable" 2 "Error" 1 "TemperaturetooHigh" 0 "TemperatureOK" ;
VAL_ 2566882563 StopRequested 3 "NotAvailable" 2 "Error" 1 "StopWarning" 0 "NoStopWarning" ;
VAL_ 2566882563 WorkshopRequested 1 "Workshop requested" 0 "Not active" ;
VAL_ 2566882563 ManouveringModeStat 3 "NotAvailable" 2 "Error" 1 "ManoeuveringModeActive" 0 "ManoeuveringModeNotActive" ;
VAL_ 2566882563 AutomaticManualModeStat 3 "NotAvailable" 2 "Error" 1 "AutomaticModeActive" 0 "ManualModeActive" ;
VAL_ 2566804992 AdBlueQuality 1 "Incorrect AdBlue Detected" 0 "No warning message" ;
VAL_ 2566804992 AdBlueUreaWarning 4 "Fill Up AdBlue" 1 "AdBlue Level Low" 0 "No warning message" ;
VAL_ 2566857214 EngineDegradationLevel 15 "notDefined" 14 "notDefined" 13 "notDefined" 12 "notDefined" 11 "notDefined" 10 "notDefined" 9 "notDefined" 8 "notDefined" 7 "notDefined" 6 "notDefined" 5 "notDefined" 4 "Degradation Level 4" 3 "Degradation Level 3" 2 "Degradation Level 2" 1 "Degradation Level 1" 0 "NoDegradation" ;
VAL_ 2566857214 EDCOperationalStat 15 "NotDefined" 14 "NotDefined" 13 "NotDefined" 12 "NotDefined" 11 "NotDefined" 10 "NotDefined" 9 "NotDefined" 8 "NotDefined" 7 "NotDefined" 6 "NotDefined" 5 "NotDefined" 4 "NotDefined" 3 "OverRunMonitoringActive" 2 "DiagnosticTest" 1 "AfterrunActive" 0 "NormalOperation" ;
VAL_ 2566857214 EngineOilPressureLow 3 "NotAvailable" 2 "Reserved" 1 "AboveOperatingRange" 0 "Normal" ;
VAL_ 2566857214 WaterinFeulDetection 3 "Description for the value '0x3'" 2 "Reserved" 1 "Yes" 0 "No" ;
VAL_ 2566857214 FuelFilterStatus 3 "NotAvailable" 2 "Reserved" 1 "On" 0 "Off" ;
VAL_ 2566857214 EngineOilTemperatureHigh 3 "NotAvailable" 2 "Reserved" 1 "AboveOperatingRange" 0 "Normal" ;
VAL_ 2566857214 StatofEngComprtmntStopButton 3 "NotAvailable" 2 "Reserved" 1 "On" 0 "Off" ;
VAL_ 2566857214 StatofEngCompartmentStartButton 3 "NotAvailable" 2 "Reserved" 1 "On" 0 "Off" ;
VAL_ 2566857214 MILStatus 3 "NotAvailable" 2 "Blink" 1 "On" 0 "Off" ;
VAL_ 2566857214 AdjustabelSpeedLimiterStatus 3 "Description for the value '0x3'" 2 "onn(LmtnActive" 1 "on(viaCC)" 0 "off" ;
VAL_ 2566857214 ECMFuellingState 3 "NotAvailable" 1 "NotReadyto Inject" 0 "ReadytoInject" ;
VAL_ 2566857214 SpeedLimiterStatus 3 "2ndspeedandprogSpdLmtnRq" 2 "Progr.VehicleSpeedLmtnrequested" 1 "2ndSpeedLimitationRequest" 0 "NoSpeedLimitationRequest" ;
VAL_ 2566857214 EngineOverSpeed 3 "NotAvailable" 2 "Reserved" 1 "AboveOperatingRange" 0 "Normal" ;
VAL_ 2566857214 EngineOverTemperature 3 "NotDefined" 2 "Warning" 1 "PreWarning" 0 "NoWarning" ;
VAL_ 2566857214 ColdStartHeaterStat 15 "NotDefined" 14 "NotDefined" 13 "NotDefined" 12 "NotDefined" 11 "NotDefined" 10 "NotDefined" 9 "CldStrtHtActvtdPrtcleFilterRgnrt" 8 "ColdStartHeaterTestinProgress" 7 "TemperaturePre-EvaluationPhase" 6 "PostHeatingPhase" 5 "CrankwithExtraHeatingPhase" 4 "CrankPhase" 3 "StandbyPhasew/oHeating" 2 "StandbyPhasewithHeating" 1 "Pre-HeatingPhase" 0 "OffPhase" ;
VAL_ 2566857214 FuelBlockStatByImmobilizer 2 "NoImmobilizer" 1 "FuelBlocked" 0 "FuelReleased" ;
VAL_ 2566857214 DiagnosticLampStat 3 "NoAction" 2 "reserved" 1 "on" 0 "off" ;
VAL_ 2566835710 EngTorqueMode 15 "Not available" 11 "Remote accelerator" 10 "Braking system" 9 "High speed governor" 8 "Torque limiting" 7 "ABS control" 6 "Transmission control" 5 "ASR control" 4 "Road speed governor" 3 "PTO governor" 2 "Cruise control" 1 "Accelerator pedal/operator selec" 0 "Low idle governor/no request (de" ;
VAL_ 2566840592 RetarderCtrlMethod 0 "ContinuousControl" ;
VAL_ 2566840592 RetarderLocation 15 "NotAvailable" 14 "Other" 6 "1101NotDefined" 5 "Trailer" 4 "Driveline" 3 "TransOutput" 2 "TransInput" 1 "EngExhaustBrake" 0 "EngCompressionReleaseBrake" ;
VAL_ 2566840592 RetarderType 15 "NotAvailable" 14 "Other" 5 "1101NotDefined" 4 "Exhaust" 3 "CompressionRelease" 2 "CooledFriction" 1 "Hyd" 0 "Electric_Magnetic" ;
VAL_ 2565865488 RetarderRoadSpeedLimitSwitch 3 "NotAvailable" 2 "ErrorIndicator" 1 "RdSpdLmtngByRtrdrIsEnbldRdSpdTh" 0 "RdSpdLmtingByRetarderIsDisabled" ;
VAL_ 2565865488 RetarderRoadSpeedExceededStatus 3 "DontCare_TakeNoAction" 2 "Reserved" 1 "RdSpdIsAbvThrshldAndRtrdrIsAllw" 0 "RoadSpeedIsBelowThreshold" ;
VAL_ 2565865488 RetarderRqingBrakeLight 3 "NotAvailable_TakeNoAction" 2 "Reserved" 1 "RtrdrIsRqngThtBrkLghtsArIllmntd" 0 "RtrdrIsNtRqngThtBrkLghtsArIllmn" ;
VAL_ 2565865488 EngCoolantLoadIncrease 3 "NotAvailable" 2 "Error" 1 "CoolantLoadIncreasePossible" 0 "NoCoolantLoadIncrease" ;
VAL_ 2565865488 RetarderEnableShiftAssistSwitch 3 "NotAvailable" 2 "Error" 1 "RetarderShiftAssistEnabled" 0 "RetarderShiftAssistDisabled" ;
VAL_ 2565865488 RetarderEnableBrakeAssistSwitch 3 "NotAvailable" 2 "Error" 1 "RetarderBrakeAssistEnabled" 0 "RetarderBrakeAssistDisabled" ;
VAL_ 2565865488 RetarderTorqueMode 15 "NotAvailable" 14 "OtherSytems" 13 "NotDefined" 12 "NotDefined" 11 "NotDefined" 10 "BrakingSystem" 9 "HighSpeedGovernor" 8 "TorqueLimiter" 7 "ABSControl" 6 "TransmissionControl" 5 "ASRControl" 4 "RoadSpeedLimiter" 3 "PowerTakeOffGovernor" 2 "CruiseControl" 1 "OperatorSelection" 0 "NoRequest" ;
VAL_ 2566834960 MalfunctionIndicatorLampStatus 3 "Not available" 2 "Reserved" 1 "Lamp on" 0 "Lamp off" ;
VAL_ 2566834960 RedStopLampState 3 "Not available" 2 "Reserved" 1 "Lamp on" 0 "Lamp off" ;
VAL_ 2566834960 AmberWarningLampStatus 3 "Not available" 2 "Reserved" 1 "Lamp on" 0 "Lamp off" ;
VAL_ 2566834960 ProtectLampStatus 3 "Not available" 2 "Reserved" 1 "Lamp on" 0 "Lamp off" ;
VAL_ 2566834960 FlashRedStopLamp 3 "Unavailable / Do Not Flash" 2 "Reserved" 1 "Fast Flash" 0 "Slow Flash" ;
VAL_ 2566834960 FlashProtectLamp 3 "Unavailable / Do Not Flash" 2 "Reserved" 1 "Fast Flash" 0 "Slow Flash" ;
VAL_ 2566834960 FlashMalfuncIndicatorLamp 3 "Unavailable / Do Not Flash" 2 "Reserved" 1 "Fast Flash" 0 "Slow Flash" ;
VAL_ 2566834960 FlashAmberWarningLamp 3 "Unavailable / Do Not Flash" 2 "Reserved" 1 "Fast Flash" 0 "Slow Flash" ;
VAL_ 2566834749 FlashRedStopLamp 3 "Unavailable / Do Not Flash" 2 "Reserved" 1 "Fast Flash" 0 "Slow Flash" ;
VAL_ 2566834749 FlashProtectLamp 3 "Unavailable / Do Not Flash" 2 "Reserved" 1 "Fast Flash" 0 "Slow Flash" ;
VAL_ 2566834749 FlashMalfuncIndicatorLamp 3 "Unavailable / Do Not Flash" 2 "Reserved" 1 "Fast Flash" 0 "Slow Flash" ;
VAL_ 2566834749 FlashAmberWarningLamp 3 "Unavailable / Do Not Flash" 2 "Reserved" 1 "Fast Flash" 0 "Slow Flash" ;
VAL_ 2566834749 MalfunctionIndicatorLampStatus 3 "Not available" 2 "Reserved" 1 "Lamp on" 0 "Lamp off" ;
VAL_ 2566834749 AmberWarningLampStatus 3 "Not available" 2 "Reserved" 1 "Lamp on" 0 "Lamp off" ;
VAL_ 2566834749 RedStopLampState 3 "Not available" 2 "Reserved" 1 "Lamp on" 0 "Lamp off" ;
VAL_ 2566834749 ProtectLampStatus 3 "Not available" 2 "Reserved" 1 "Lamp on" 0 "Lamp off" ;
VAL_ 2348875297 MessageCounter 14 "Reserved" 13 "Reserved" 12 "Reserved" 11 "Reserved" 10 "Reserved" 9 "Reserved" 8 "Reserved" 15 "Not Available" ;
VAL_ 2348875297 ControlPurpose 5 "TemporaryPowerTrainControl" 4 "EngineProtection" 3 "RoadSpeedGovernor" 2 "PTOGovernor" 1 "CruiseControl" 0 "AcceleratorPedal" ;
VAL_ 2348875297 TransmissionRate 7 "UseStandardRate" 6 "25ms" 5 "50ms" 4 "100ms" 3 "250ms" 2 "500ms" 1 "750ms" 0 "1000ms" ;
VAL_ 2348875297 OverrideCtrlModePriority 3 "LowPriority" 2 "MdmPrrtyUsdFrPwrtrnCtrlOprtnsWh" 1 "HighPriority" 0 "HghstPrrtyUsdFrSttnsThtRqrImmdt" ;
VAL_ 2348875297 EngRqedSpeedCtrlConditions 2 "ThsCtrlCndtnHsBnOptmzdTMnmzRpmO" 3 "StbltyOptmzdFrDrvlnEnggdAnd_OrI" 1 "StbltyOptmzdFrDrvlnDsnggdAndNnl" 0 "ThsSpdGvrnrGnSlctnIsAdjstdTPrvd" ;
VAL_ 2348875297 EngOverrideCtrlMode 3 "Spd_TrqLmtCtrlLmtSpdAnd_OrTrqBs" 2 "TrqCtrlCntrlTrqTInclddDsrdTrqVl" 1 "SpdCtrlGvrnSpdTInclddDsrdSpdVle" 0 "OvrrdDsbldDsblAnyExstngCtrlCmdd" ;
VAL_ 2348875297 MessageChecksum 15 "Not Available" ;
VAL_ 2348875297 EngineRequestedTorqueHiRes 15 "Not Available" 14 "Not Available" 13 "Not Available" 12 "Not Available" 11 "Not Available" 10 "Not Available" 9 "Not Available" 8 "Not Available" ;
VAL_ 2348810243 MessageCounter 14 "Reserved" 13 "Reserved" 12 "Reserved" 11 "Reserved" 10 "Reserved" 9 "Reserved" 8 "Reserved" 15 "Not Available" ;
VAL_ 2348810243 ControlPurpose 5 "TemporaryPowerTrainControl" 4 "EngineProtection" 3 "RoadSpeedGovernor" 2 "PTOGovernor" 1 "CruiseControl" 0 "AcceleratorPedal" ;
VAL_ 2348810243 TransmissionRate 7 "UseStandardRate" 6 "25ms" 5 "50ms" 4 "100ms" 3 "250ms" 2 "500ms" 1 "750ms" 0 "1000ms" ;
VAL_ 2348810243 OverrideCtrlModePriority 3 "LowPriority" 2 "MdmPrrtyUsdFrPwrtrnCtrlOprtnsWh" 1 "HighPriority" 0 "HghstPrrtyUsdFrSttnsThtRqrImmdt" ;
VAL_ 2348810243 EngRqedSpeedCtrlConditions 2 "ThsCtrlCndtnHsBnOptmzdTMnmzRpmO" 3 "StbltyOptmzdFrDrvlnEnggdAnd_OrI" 1 "StbltyOptmzdFrDrvlnDsnggdAndNnl" 0 "ThsSpdGvrnrGnSlctnIsAdjstdTPrvd" ;
VAL_ 2348810243 EngOverrideCtrlMode 3 "Spd_TrqLmtCtrlLmtSpdAnd_OrTrqBs" 2 "TrqCtrlCntrlTrqTInclddDsrdTrqVl" 1 "SpdCtrlGvrnSpdTInclddDsrdSpdVle" 0 "OvrrdDsbldDsblAnyExstngCtrlCmdd" ;
VAL_ 2348810243 MessageChecksum 15 "Not Available" ;
VAL_ 2348810243 EngineRequestedTorqueHiRes 15 "Not Available" 14 "Not Available" 13 "Not Available" 12 "Not Available" 11 "Not Available" 10 "Not Available" 9 "Not Available" 8 "Not Available" ;
VAL_ 2348814091 OverrideCtrlModePriority_EngBr 3 "LowPriority" 2 "MdmPrrtyUsdFrPwrtrnCtrlOprtnsWh" 1 "HighPriority" 0 "HghstPrrtyUsdFrSttnsThtRqrImmdt" ;
VAL_ 2348814091 EngRqedSpeedCtrlConditions_EngBr 3 "XStbOptDrvEngaged" 2 "StbOptDrvEngaged" 1 "StbOptDrvDisengaged" 0 "TrnstOptDrvDisengaged" ;
VAL_ 2348814091 EngOverrideCtrlMode_EngBr 3 "Spd_TrqLmtCtrlLmtSpdAnd_OrTrqBs" 2 "TrqCtrlCntrlTrqTInclddDsrdTrqVl" 1 "SpdCtrlGvrnSpdTInclddDsrdSpdVle" 0 "OvrrdDsbldDsblAnyExstngCtrlCmdd" ;
VAL_ 2348814083 MessageCounter 14 "Reserved" 13 "Reserved" 12 "Reserved" 11 "Reserved" 10 "Reserved" 9 "Reserved" 8 "Reserved" 15 "Not Available" ;
VAL_ 2348814083 ControlPurpose 5 "TemporaryPowerTrainControl" 4 "EngineProtection" 3 "RoadSpeedGovernor" 2 "PTOGovernor" 1 "CruiseControl" 0 "AcceleratorPedal" ;
VAL_ 2348814083 TransmissionRate 7 "UseStandardRate" 6 "25ms" 5 "50ms" 4 "100ms" 3 "250ms" 2 "500ms" 1 "750ms" 0 "1000ms" ;
VAL_ 2348814083 OverrideCtrlModePriority 3 "LowPriority" 2 "MdmPrrtyUsdFrPwrtrnCtrlOprtnsWh" 1 "HighPriority" 0 "HghstPrrtyUsdFrSttnsThtRqrImmdt" ;
VAL_ 2348814083 EngRqedSpeedCtrlConditions 2 "ThsCtrlCndtnHsBnOptmzdTMnmzRpmO" 3 "StbltyOptmzdFrDrvlnEnggdAnd_OrI" 1 "StbltyOptmzdFrDrvlnDsnggdAndNnl" 0 "ThsSpdGvrnrGnSlctnIsAdjstdTPrvd" ;
VAL_ 2348814083 EngOverrideCtrlMode 3 "Spd_TrqLmtCtrlLmtSpdAnd_OrTrqBs" 1 "SpdCtrlGvrnSpdTInclddDsrdSpdVle" 2 "TrqCtrlCntrlTrqTInclddDsrdTrqVl" 0 "OvrrdDsbldDsblAnyExstngCtrlCmdd" ;
VAL_ 2348814083 MessageChecksum 15 "Not Available" ;
VAL_ 2348814083 EngineRequestedTorqueHiRes 15 "Not Available" 14 "Not Available" 13 "Not Available" 12 "Not Available" 11 "Not Available" 10 "Not Available" 9 "Not Available" 8 "Not Available" ;
VAL_ 2348814096 MessageCounter 14 "Reserved" 13 "Reserved" 12 "Reserved" 11 "Reserved" 10 "Reserved" 9 "Reserved" 8 "Reserved" 15 "Not Available" ;
VAL_ 2348814096 ControlPurpose 5 "TemporaryPowerTrainControl" 4 "EngineProtection" 3 "RoadSpeedGovernor" 2 "PTOGovernor" 1 "CruiseControl" 0 "AcceleratorPedal" ;
VAL_ 2348814096 TransmissionRate 7 "UseStandardRate" 6 "25ms" 5 "50ms" 4 "100ms" 3 "250ms" 2 "500ms" 1 "750ms" 0 "1000ms" ;
VAL_ 2348814096 OverrideCtrlModePriority 3 "LowPriority" 2 "MdmPrrtyUsdFrPwrtrnCtrlOprtnsWh" 1 "HighPriority" 0 "HghstPrrtyUsdFrSttnsThtRqrImmdt" ;
VAL_ 2348814096 EngRqedSpeedCtrlConditions 2 "ThsCtrlCndtnHsBnOptmzdTMnmzRpmO" 3 "StbltyOptmzdFrDrvlnEnggdAnd_OrI" 1 "StbltyOptmzdFrDrvlnDsnggdAndNnl" 0 "ThsSpdGvrnrGnSlctnIsAdjstdTPrvd" ;
VAL_ 2348814096 EngOverrideCtrlMode 3 "Spd_TrqLmtCtrlLmtSpdAnd_OrTrqBs" 2 "TrqCtrlCntrlTrqTInclddDsrdTrqVl" 1 "SpdCtrlGvrnSpdTInclddDsrdSpdVle" 0 "OvrrdDsbldDsblAnyExstngCtrlCmdd" ;
VAL_ 2348814096 MessageChecksum 15 "Not Available" ;
VAL_ 2348814096 EngineRequestedTorqueHiRes 15 "Not Available" 14 "Not Available" 13 "Not Available" 12 "Not Available" 11 "Not Available" 10 "Not Available" 9 "Not Available" 8 "Not Available" ;
VAL_ 2348810251 OverrideCtrlModePriority_Engine 3 "LowPriority" 2 "MdmPrrtyUsdFrPwrtrnCtrlOprtnsWh" 1 "HighPriority" 0 "HghstPrrtyUsdFrSttnsThtRqrImmdt" ;
VAL_ 2348810251 EngRqedSpeedCtrlConditions_Eng 3 "XStbOptDrvEngaged" 2 "StbOptDrvEngaged" 1 "StbOptDrvDisengaged" 0 "TrnstOptDrvDisengaged" ;
VAL_ 2348810251 EngOverrideCtrlMode_Engine 3 "Spd_TrqLmtCtrlLmtSpdAnd_OrTrqBs" 2 "TrqCtrlCntrlTrqTInclddDsrdTrqVl" 1 "SpdCtrlGvrnSpdTInclddDsrdSpdVle" 0 "OvrrdDsbldDsblAnyExstngCtrlCmdd" ;
VAL_ 2566834699 FlashRedStopLamp 3 "Unavailable / Do Not Flash" 2 "Reserved" 1 "Fast Flash" 0 "Slow Flash" ;
VAL_ 2566834699 FlashProtectLamp 3 "Unavailable / Do Not Flash" 2 "Reserved" 1 "Fast Flash" 0 "Slow Flash" ;
VAL_ 2566834699 FlashMalfuncIndicatorLamp 3 "Unavailable / Do Not Flash" 2 "Reserved" 1 "Fast Flash" 0 "Slow Flash" ;
VAL_ 2566834699 FlashAmberWarningLamp 3 "Unavailable / Do Not Flash" 2 "Reserved" 1 "Fast Flash" 0 "Slow Flash" ;
VAL_ 2566834699 MalfunctionIndicatorLampStatus 3 "Not available" 2 "Reserved" 1 "Lamp on" 0 "Lamp off" ;
VAL_ 2566834699 AmberWarningLampStatus 3 "Not available" 2 "Reserved" 1 "Lamp on" 0 "Lamp off" ;
VAL_ 2566834699 RedStopLampState 3 "Not available" 2 "Reserved" 1 "Lamp on" 0 "Lamp off" ;
VAL_ 2566834699 ProtectLampStatus 3 "Not available" 2 "Reserved" 1 "Lamp on" 0 "Lamp off" ;
VAL_ 2566834942 FlashRedStopLamp 3 "Unavailable / Do Not Flash" 2 "Reserved" 1 "Fast Flash" 0 "Slow Flash" ;
VAL_ 2566834942 FlashProtectLamp 3 "Unavailable / Do Not Flash" 2 "Reserved" 1 "Fast Flash" 0 "Slow Flash" ;
VAL_ 2566834942 FlashMalfuncIndicatorLamp 3 "Unavailable / Do Not Flash" 2 "Reserved" 1 "Fast Flash" 0 "Slow Flash" ;
VAL_ 2566834942 FlashAmberWarningLamp 3 "Unavailable / Do Not Flash" 2 "Reserved" 1 "Fast Flash" 0 "Slow Flash" ;
VAL_ 2566834942 MalfunctionIndicatorLampStatus 3 "Not available" 2 "Reserved" 1 "Lamp on" 0 "Lamp off" ;
VAL_ 2566834942 AmberWarningLampStatus 3 "Not available" 2 "Reserved" 1 "Lamp on" 0 "Lamp off" ;
VAL_ 2566834942 RedStopLampState 3 "Not available" 2 "Reserved" 1 "Lamp on" 0 "Lamp off" ;
VAL_ 2566834942 ProtectLampStatus 3 "Not available" 2 "Reserved" 1 "Lamp on" 0 "Lamp off" ;
VAL_ 2566834688 FlashRedStopLamp 3 "Unavailable / Do Not Flash" 2 "Reserved" 1 "Fast Flash" 0 "Slow Flash" ;
VAL_ 2566834688 FlashProtectLamp 3 "Unavailable / Do Not Flash" 2 "Reserved" 1 "Fast Flash" 0 "Slow Flash" ;
VAL_ 2566834688 FlashMalfuncIndicatorLamp 3 "Unavailable / Do Not Flash" 2 "Reserved" 1 "Fast Flash" 0 "Slow Flash" ;
VAL_ 2566834688 FlashAmberWarningLamp 3 "Unavailable / Do Not Flash" 2 "Reserved" 1 "Fast Flash" 0 "Slow Flash" ;
VAL_ 2566834688 MalfunctionIndicatorLampStatus 3 "Not available" 2 "Reserved" 1 "Lamp on" 0 "Lamp off" ;
VAL_ 2566834688 AmberWarningLampStatus 3 "Not available" 2 "Reserved" 1 "Lamp on" 0 "Lamp off" ;
VAL_ 2566834688 RedStopLampState 3 "Not available" 2 "Reserved" 1 "Lamp on" 0 "Lamp off" ;
VAL_ 2566834688 ProtectLampStatus 3 "Not available" 2 "Reserved" 1 "Lamp on" 0 "Lamp off" ;
VAL_ 2566834926 FlashRedStopLamp 3 "Unavailable / Do Not Flash" 2 "Reserved" 1 "Fast Flash" 0 "Slow Flash" ;
VAL_ 2566834926 FlashProtectLamp 3 "Unavailable / Do Not Flash" 2 "Reserved" 1 "Fast Flash" 0 "Slow Flash" ;
VAL_ 2566834926 FlashMalfuncIndicatorLamp 3 "Unavailable / Do Not Flash" 2 "Reserved" 1 "Fast Flash" 0 "Slow Flash" ;
VAL_ 2566834926 FlashAmberWarningLamp 3 "Unavailable / Do Not Flash" 2 "Reserved" 1 "Fast Flash" 0 "Slow Flash" ;
VAL_ 2566834926 MalfunctionIndicatorLampStatus 3 "Not available" 2 "Reserved" 1 "Lamp on" 0 "Lamp off" ;
VAL_ 2566834926 AmberWarningLampStatus 3 "Not available" 2 "Reserved" 1 "Lamp on" 0 "Lamp off" ;
VAL_ 2566834926 RedStopLampState 3 "Not available" 2 "Reserved" 1 "Lamp on" 0 "Lamp off" ;
VAL_ 2566834926 ProtectLampStatus 3 "Not available" 2 "Reserved" 1 "Lamp on" 0 "Lamp off" ;
VAL_ 2631794209 AntthftEncryptonIndicatorStates 3 "NtAvlblThsSttIsUsdTIndctThtARnd" 2 "NotDefined" 1 "EncryptdCdPrsntThsSttIsUsdTIndc" 0 "EncryptnSdRqThsSttRprsntsARqstT" ;
VAL_ 2631794209 AntitheftDesiredExitModeStates 3 "NtAvlblThsSttIsIndctsThtOptnIsN" 2 "NotDefined" 1 "LckWhnKyffThsSttIsUsdTIndctThtC" 0 "LckUpnOprtrRqThsSttIsUsdTIndctT" ;
VAL_ 2631794209 AntitheftCmdStates 6 "111NotDefined" 5 "Login" 4 "ChckSttsThsSttRprsntsARqTChckTS" 3 "LockorUnlock" 2 "ChngPwdThsSttRprsntsARqTCmpnntT" 1 "DeletePwd" 0 "AddPwdThsSttRprsntsARqTCmpnntTA" ;
VAL_ 2631794430 AntthftEncryptonIndicatorStates 3 "NtAvlblThsSttIsUsdTIndctThtARnd" 2 "NotDefined" 1 "EncryptdCdPrsntThsSttIsUsdTIndc" 0 "EncryptnSdRqThsSttRprsntsARqstT" ;
VAL_ 2631794430 AntitheftDesiredExitModeStates 3 "NtAvlblThsSttIsIndctsThtOptnIsN" 2 "NotDefined" 1 "LckWhnKyffThsSttIsUsdTIndctThtC" 0 "LckUpnOprtrRqThsSttIsUsdTIndctT" ;
VAL_ 2631794430 AntitheftCmdStates 6 "111NotDefined" 5 "Login" 4 "ChckSttsThsSttRprsntsARqTChckTS" 3 "LockorUnlock" 2 "ChngPwdThsSttRprsntsARqTCmpnntT" 1 "DeletePwd" 0 "AddPwdThsSttRprsntsARqTCmpnntTA" ;
VAL_ 2297441790 SpprtVrblTrnsRpttnRtFrAcclrtnSns 1 "MsTransRate" ;
VAL_ 2297441790 VrtclAcclrtnExRngeFigureOfMerit 3 "NotAvailable" 2 "Error" 1 "VrtclcclrtnIsDgrddDtIsSspctDTEn" 0 "VrtclAcclrtnIsFllyFnctnlDtIsWth" ;
VAL_ 2297441790 LngtdnlAcclrtnExRngFgureOfMerit 3 "NotAvailable" 2 "Error" 1 "LngtdnlAcclrtnIsDgrddDtIsSspctD" 0 "LngtdnlAcclrtnIsFllyFnctnlDtIsW" ;
VAL_ 2297441790 LtrlAcclrtnExRangeFigureOfMerit 3 "NotAvailable" 2 "Error" 1 "LtrlAcclrtnIsDgrddDtIsSspctDTEn" 0 "LtrlAcclrtnIsFllyFnctnlDtIsWthn" ;
VAL_ 2364549630 RollAngleExRangeFigureOfMerit 3 "NotAvailable" 2 "Error" 1 "RllRtDgrddDtIsSspctDTEnvrnmntlC" 0 "RllRtFllyFnctnlDtIsWthnSnsrSpcf" ;
VAL_ 2364549630 RollAngleExRangeCompensation 3 "NotAvailable" 2 "Error" 1 "Off" 0 "On" ;
VAL_ 2364549630 PitchAngleExRangeFigureOfMerit 3 "NotAvailable" 2 "Error" 1 "PtchRtDgrddDtIsSspctDTEnvrnmntl" 0 "PtchRtFllyFnctnlDtIsWthnSnsrSpc" ;
VAL_ 2364549630 PitchAngleExRangeCompensation 3 "NotAvailable" 2 "Error" 1 "Off" 0 "On" ;
VAL_ 2499614462 OccpntClssfcationSystem10Status 3 "NotAvailable" 2 "ErrrClssfctonCannotBeDetermined" 1 "Occupied" 0 "Empty" ;
VAL_ 2499614462 OccpntClssficationSystem9Status 3 "NotAvailable" 2 "ErrrClssfctonCannotBeDetermined" 1 "Occupied" 0 "Empty" ;
VAL_ 2499614462 OccpntClssficationSystem8Status 3 "NotAvailable" 2 "ErrrClssfctonCannotBeDetermined" 1 "Occupied" 0 "Empty" ;
VAL_ 2499614462 OccpntClssficationSystem7Status 3 "NotAvailable" 2 "ErrrClssfctonCannotBeDetermined" 1 "Occupied" 0 "Empty" ;
VAL_ 2499614462 OccpntClssficationSystem6Status 3 "NotAvailable" 2 "ErrrClssfctonCannotBeDetermined" 1 "Occupied" 0 "Empty" ;
VAL_ 2499614462 OccpntClssficationSystem5Status 3 "NotAvailable" 2 "ErrrClssfctonCannotBeDetermined" 1 "Occupied" 0 "Empty" ;
VAL_ 2499614462 OccpntClssficationSystem4Status 3 "NotAvailable" 2 "ErrrClssfctonCannotBeDetermined" 1 "Occupied" 0 "Empty" ;
VAL_ 2499614462 OccpntClssficationSystem3Status 3 "NotAvailable" 2 "ErrrClssfctonCannotBeDetermined" 1 "Occupied" 0 "Empty" ;
VAL_ 2499614462 PssngrOccpntClssfctnSystmStatus 7 "NotAvailable" 5 "ErrrClssfctnOfOccpntCnntBDtrmnd" 3 "Adult" 4 "LargeAdult" 2 "SmallAdult" 1 "Child" 0 "Empty" ;
VAL_ 2499614462 DrvrOccpntClssfctonSystemStatus 7 "NotAvailable" 6 "ErrrClssfctnOfOccpntCnntBDtrmnd" 5 "Reserved" 4 "LargeAdult" 3 "Adult" 2 "SmallAdult" 1 "Child" 0 "Empty" ;
VAL_ 2560098046 CabNoiseCtrlTuningStatus 15 "NotAvailable_NotTuning_NotRqed" 14 "TuningModeError" 10 "AutomaticTuningModeSavingData" 9 "AutomaticTuningModeCmdComplete" 8 "AutomaticTuningMode" 7 "MnlTnngDndRqrsScrtyVerification" 13 "Reserved" 2 "ManualTuningModeSavingData" 1 "ManualTuningModeCmdComplete" 0 "ManualTuningMode" ;
VAL_ 2560098046 CabNoiseCtrlStatus 3 "NotAvailable_NotRqed" 2 "ErrorIndicator" 1 "CabNoiseCtrlSystemOFFLine" 0 "CabNoiseCtrlSystemONLine" ;
VAL_ 2560163582 CabNoiseCtrlTuningState 7 "DontCareNOTCmded" 6 "Reserved" 5 "ExitTuningSavingParameters" 4 "ExitTuningNotSavingParameters" 3 "RmnInTningSaveCurrentParameters" 2 "ActvtAtmtcTnngSttSvngPrmtrsExtO" 1 "ActvtAtmtcTnngWtFrSvAndExitCmds" 0 "ActvtMnlTnngWtFrSaveAndExitCmds" ;
VAL_ 2560163582 CabNoiseCtrlState 3 "DontCare_NotCmded" 2 "Reserved" 1 "BringCabNoiseCtrlSystemOnLine" 0 "TakeCabNoiseCtrlSystemOffLine" ;
VAL_ 2297441534 DropRelayCtrl 3 "TakeNoAction" 2 "Reserved" 1 "OnEnableDropRelayRq" 0 "OffDisableDropRelayRq" ;
VAL_ 2297441534 LiftRelayCtrl 3 "TakeNoAction" 2 "Reserved" 1 "OnEnableLiftRelayRq" 0 "OffDisableLiftRelayRq" ;
VAL_ 2297441534 MaterialDropActiveStatus 3 "NotAvailable" 2 "Error" 1 "On" 0 "Off" ;
VAL_ 2297441534 MaterialLiftActiveStatus 3 "NotAvailable" 2 "Error" 1 "On" 0 "Off" ;
VAL_ 2297441534 GnratorCurrentBoostActiveStatus 3 "NotAvailable" 2 "Error" 1 "On" 0 "Off" ;
VAL_ 2297441534 MaterialDropSwitch 3 "NotAvailable" 2 "Error" 1 "Drop" 0 "DontDrop" ;
VAL_ 2297441534 MaterialLiftSwitch 3 "NotAvailable" 2 "Error" 1 "Lift" 0 "DontLift" ;
VAL_ 2566722302 GneratorDutyCycleExceededStatus 3 "NotAvaiable" 2 "Error" 1 "DutyCycleExceed" 0 "DutyCycleNotExceed" ;
VAL_ 2566722302 VoltageMonitorActiveStatus 3 "NotAvailable" 2 "Error" 1 "MonitorIsOn" 0 "MonitorIsOff" ;
VAL_ 2566722302 GensetEnableActiveStatus 3 "NotAvaialble" 2 "Error" 1 "Enabled" 0 "NotEnabled" ;
VAL_ 2566722302 ReverseCurrentRangeSetting 31 "NotAvailable" 30 "Error" 16 "11101NotUsed" 15 "16" 14 "15" 13 "14" 12 "13" 11 "12" 10 "11" 9 "10" 8 "9" 7 "8" 6 "7" 5 "6" 4 "5" 3 "4" 2 "3" 1 "2" 0 "1" ;
VAL_ 2566722302 GensetSoftstartActiveStatus 3 "NotAvailable" 2 "Error" 1 "On" 0 "Off" ;
VAL_ 2566722302 Grapple_MagnetSelectionSwitch 3 "NotAvailable" 2 "Error" 1 "MagnetSelected" 0 "GrappleSelected" ;
VAL_ 2566722302 GnstSystmOtptVoltageRangeStatus 3 "NotAvailable" 2 "Error" 1 "InRange" 0 "OutOfRange" ;
VAL_ 2566722302 GeneratorOverheatStatus 3 "NotAvailable" 2 "Error" 1 "Overheat" 0 "NotOverheat" ;
VAL_ 2560032510 LwVltgDscnnctDsredOperatingMode 15 "NoChange" 6 "1110Reserved" 5 "ManualConnect" 4 "ManualDisconnect" 1 "0011Reserved" 0 "Automatic" ;
VAL_ 2566717950 LwVltgDisconnectVoutOutputState 15 "NotAvailableNotInstalled" 14 "OutputFault" 5 "1101Reserved" 4 "ConnectPendingAlarmActive" 3 "DisconnectPendingAlarmActive" 2 "DscnnctAlrmExprdOtptOffDscnnctd" 1 "OutputOnConnected" 0 "OutputOffDisconnected" ;
VAL_ 2566717950 LwVoltageDisconnectOutput1State 15 "NotAvailableNotInstalled" 14 "OutputFault" 5 "1101Reserved" 4 "ConnectPendingAlarmActive" 3 "DisconnectPendingAlarmActive" 2 "DscnnctAlrmExprdOtptOffDscnnctd" 1 "OutputOnConnected" 0 "OutputOffDisconnected" ;
VAL_ 2566717950 LwVoltageDisconnectOutput2State 15 "NotAvailableNotInstalled" 14 "OutputFault" 5 "1101Reserved" 4 "ConnectPendingAlarmActive" 3 "DisconnectPendingAlarmActive" 2 "DscnnctAlrmExprdOtptOffDscnnctd" 1 "OutputOnConnected" 0 "OutputOffDisconnected" ;
VAL_ 2566717950 LwVoltageDisconnectOutput3State 15 "NotAvailableNotInstalled" 14 "OutputFault" 5 "1101Reserved" 4 "ConnectPendingAlarmActive" 3 "DisconnectPendingAlarmActive" 2 "DscnnctAlrmExprdOtptOffDscnnctd" 1 "OutputOnConnected" 0 "OutputOffDisconnected" ;
VAL_ 2566717950 LwVltgDscnnctCrrntOperatingMode 15 "NotAvailable" 10 "1110Reserved" 9 "ManualConnectViaHardwiredInput" 8 "MnalDisconnectViaHardwiredInput" 6 "0111Reserved" 5 "ManualConnectViaJ1939Rq" 4 "ManualDisconnectViaJ1939Rq" 1 "0011Reserved" 0 "Automatic" ;
VAL_ 2566717950 LwVltgDscnnctManualConnectState 3 "NotInstalled" 2 "Error" 1 "InputOn" 0 "InputOff" ;
VAL_ 2566717950 LwVltgDscnnctMnlDisconnectState 3 "NotInstalled" 2 "Error" 1 "InputOn" 0 "InputOff" ;
VAL_ 2358902526 Joystick3Lamp10Cmd 3 "NotAvailableNotInstalled" 2 "Blinking" 1 "On" 0 "Off" ;
VAL_ 2358902526 Joystick3Lamp9Cmd 3 "NotAvailableNotInstalled" 2 "Blinking" 1 "On" 0 "Off" ;
VAL_ 2358902526 Joystick3Lamp8Cmd 3 "NotAvailableNotInstalled" 2 "Blinking" 1 "On" 0 "Off" ;
VAL_ 2358902526 Joystick3Lamp7Cmd 3 "NotAvailableNotInstalled" 2 "Blinking" 1 "On" 0 "Off" ;
VAL_ 2358902526 Joystick3Lamp6Cmd 3 "NotAvailableNotInstalled" 2 "Blinking" 1 "On" 0 "Off" ;
VAL_ 2358902526 Joystick3Lamp5Cmd 3 "NotAvailableNotInstalled" 2 "Blinking" 1 "On" 0 "Off" ;
VAL_ 2358902526 Joystick3Lamp4Cmd 3 "NotAvailableNotInstalled" 2 "Blinking" 1 "On" 0 "Off" ;
VAL_ 2358902526 Joystick3Lamp3Cmd 3 "NotAvailableNotInstalled" 2 "Blinking" 1 "On" 0 "Off" ;
VAL_ 2358902526 Joystick3Lamp2Cmd 3 "NotAvailableNotInstalled" 2 "Blinking" 1 "On" 0 "Off" ;
VAL_ 2358902526 Joystick3Lamp1Cmd 3 "NotAvailableNotInstalled" 2 "Blinking" 1 "On" 0 "Off" ;
VAL_ 2358902526 Joystick2Lamp10Cmd 3 "NotAvailableNotInstalled" 2 "Blinking" 1 "On" 0 "Off" ;
VAL_ 2358902526 Joystick2Lamp9Cmd 3 "NotAvailableNotInstalled" 2 "Blinking" 1 "On" 0 "Off" ;
VAL_ 2358902526 Joystick2Lamp8Cmd 3 "NotAvailableNotInstalled" 2 "Blinking" 1 "On" 0 "Off" ;
VAL_ 2358902526 Joystick2Lamp7Cmd 3 "NotAvailableNotInstalled" 2 "Blinking" 1 "On" 0 "Off" ;
VAL_ 2358902526 Joystick2Lamp6Cmd 3 "NotAvailableNotInstalled" 2 "Blinking" 1 "On" 0 "Off" ;
VAL_ 2358902526 Joystick2Lamp5Cmd 3 "NotAvailableNotInstalled" 2 "Blinking" 1 "On" 0 "Off" ;
VAL_ 2358902526 Joystick2Lamp4Cmd 3 "NotAvailableNotInstalled" 2 "Blinking" 1 "On" 0 "Off" ;
VAL_ 2358902526 Joystick2Lamp3Cmd 3 "NotAvailableNotInstalled" 2 "Blinking" 1 "On" 0 "Off" ;
VAL_ 2358902526 Joystick2Lamp2Cmd 3 "NotAvailableNotInstalled" 2 "Blinking" 1 "On" 0 "Off" ;
VAL_ 2358902526 Joystick2Lamp1Cmd 3 "NotAvailableNotInstalled" 2 "Blinking" 1 "On" 0 "Off" ;
VAL_ 2358902526 Joystick1Lamp10Cmd 3 "NotAvailableNotInstalled" 2 "Blinking" 1 "On" 0 "Off" ;
VAL_ 2358902526 Joystick1Lamp9Cmd 3 "NotAvailableNotInstalled" 2 "Blinking" 1 "On" 0 "Off" ;
VAL_ 2358902526 Joystick1Lamp8Cmd 3 "NotAvailableNotInstalled" 2 "Blinking" 1 "On" 0 "Off" ;
VAL_ 2358902526 Joystick1Lamp7Cmd 3 "NotAvailableNotInstalled" 2 "Blinking" 1 "On" 0 "Off" ;
VAL_ 2358902526 Joystick1Lamp6Cmd 3 "NotAvailableNotInstalled" 2 "Blinking" 1 "On" 0 "Off" ;
VAL_ 2358902526 Joystick1Lamp5Cmd 3 "NotAvailableNotInstalled" 2 "Blinking" 1 "On" 0 "Off" ;
VAL_ 2358902526 Joystick1Lamp4Cmd 3 "NotAvailableNotInstalled" 2 "Blinking" 1 "On" 0 "Off" ;
VAL_ 2358902526 Joystick1Lamp3Cmd 3 "NotAvailableNotInstalled" 2 "Blinking" 1 "On" 0 "Off" ;
VAL_ 2358902526 Joystick1Lamp2Cmd 3 "NotAvailableNotInstalled" 2 "Blinking" 1 "On" 0 "Off" ;
VAL_ 2358902526 Joystick1Lamp1Cmd 3 "NotAvailableNotInstalled" 2 "Blinking" 1 "On" 0 "Off" ;
VAL_ 2566711550 IntkVlvActtnSystmOlPrss2SlndCtrl 3 "notAvailable" 2 "reservedForSAEAssignment" 1 "on" 0 "off" ;
VAL_ 2566711550 IntkVlvActtnSystmOlPrss1SlndCtrl 3 "notAvailable" 2 "reservedForSAEAssignment" 1 "on" 0 "off" ;
